VERSION ""

NS_ :

BS_:

BU_: Inverter1 Tester OBC_DDC VCU IPB Labcar_Transmit OBD_Tester TestTool_RB IMU_RB HU_B HU_C HU_A EPAS CKM12RX CKM12TX

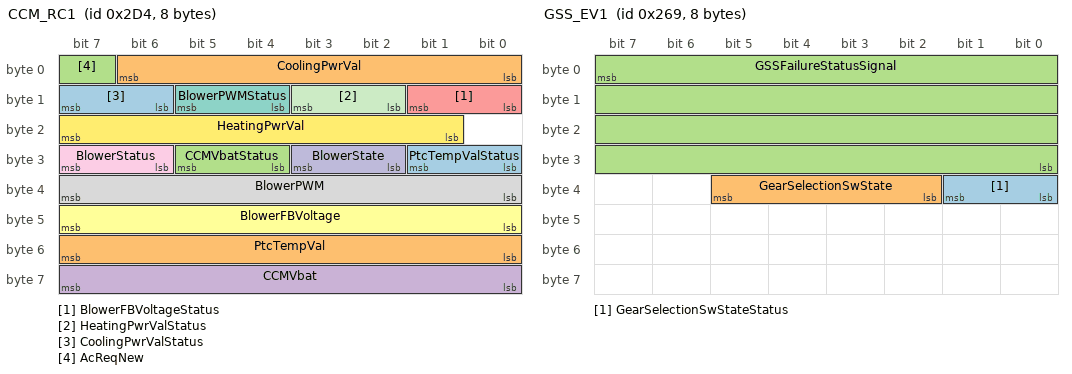
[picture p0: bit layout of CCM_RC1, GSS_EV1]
BO_ 724 CCM_RC1: 8 Vector__XXX
 SG_ PtcTempValStatus : 25|2@0+ (1,0) [0|3] ""  VCU
 SG_ PtcTempVal : 55|8@0+ (1,-40) [-40|215] "°C"  VCU
 SG_ CCMVbatStatus : 29|2@0+ (1,0) [0|3] ""  VCU
 SG_ CCMVbat : 63|8@0+ (0.1,0) [0|25.5] "Volts"  VCU
 SG_ BlowerFBVoltageStatus : 9|2@0+ (1,0) [0|3] ""  VCU
 SG_ BlowerFBVoltage : 47|8@0+ (0.1,0) [0|25.5] "Volts"  VCU
 SG_ BlowerPWMStatus : 13|2@0+ (1,0) [0|3] ""  VCU
 SG_ BlowerPWM : 39|8@0+ (1,0) [0|100] "%"  VCU
 SG_ BlowerStatus : 31|2@0+ (1,0) [0|3] ""  VCU
 SG_ BlowerState : 27|2@0+ (1,0) [0|3] ""  VCU
 SG_ HeatingPwrValStatus : 11|2@0+ (1,0) [0|3] ""  VCU
 SG_ HeatingPwrVal : 23|7@0+ (1,0) [0|100] "%"  VCU
 SG_ CoolingPwrValStatus : 15|2@0+ (1,0) [0|3] ""  VCU
 SG_ CoolingPwrVal : 6|7@0+ (1,0) [0|100] "%"  VCU
 SG_ AcReqNew : 7|1@0+ (1,0) [0|1] ""  VCU

BO_ 408 IPC14: 8 Vector__XXX
 SG_ ICDispSpeedSigStatus : 11|2@0+ (1,0) [0|3] ""  VCU
 SG_ ICDispSpeedSig : 7|12@0+ (0.03125,0) [0|127.96875] "m/s"  VCU

BO_ 495 TelematicsEventMsg_RC4: 8 Vector__XXX
 SG_ RemoteValetCmdStatus : 47|2@0+ (1,0) [0|3] ""  VCU
 SG_ RemoteValetCmd : 33|1@0+ (1,0) [0|1] ""  VCU

BO_ 617 GSS_EV1: 8 Vector__XXX
 SG_ GearSelectionSwStateStatus : 33|2@0+ (1,0) [0|3] ""  VCU
 SG_ GearSelectionSwState : 37|4@0+ (1,0) [0|15] ""  VCU
 SG_ GSSFailureStatusSignal : 7|32@0+ (1,0) [0|4294967295] ""  VCU

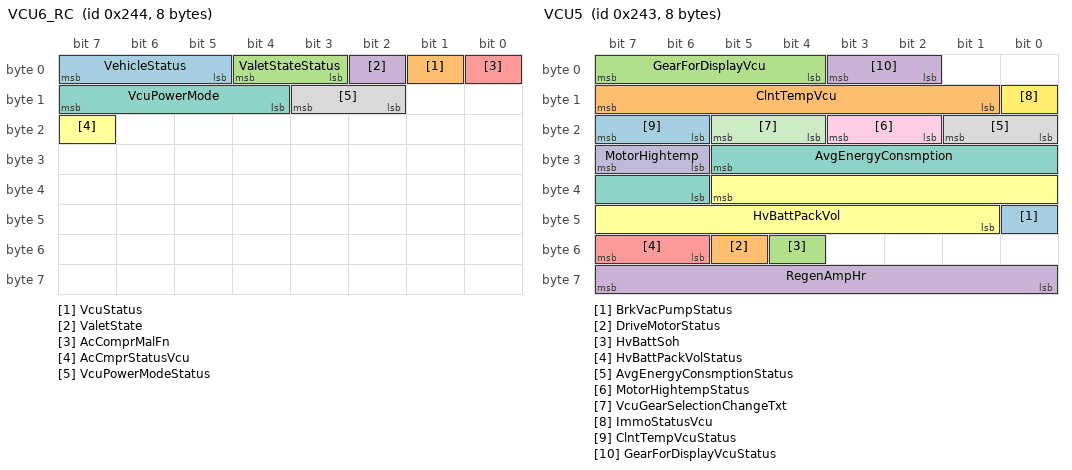
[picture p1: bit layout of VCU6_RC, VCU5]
BO_ 580 VCU6_RC: 8 VCU
 SG_ VehicleStatus : 7|3@0+ (1,0) [0|7] "" Vector__XXX
 SG_ VcuStatus : 1|1@0+ (1,0) [0|1] "" Vector__XXX
 SG_ ValetStateStatus : 4|2@0+ (1,0) [0|3] "" Vector__XXX
 SG_ ValetState : 2|1@0+ (1,0) [0|1] "" Vector__XXX
 SG_ AcComprMalFn : 0|1@0+ (1,0) [0|1] "" Vector__XXX
 SG_ AcCmprStatusVcu : 23|1@0+ (1,0) [0|1] "" Vector__XXX
 SG_ VcuPowerMode : 15|4@0+ (1,0) [0|15] "" Vector__XXX
 SG_ VcuPowerModeStatus : 11|2@0+ (1,0) [0|3] "" Vector__XXX

BO_ 579 VCU5: 8 VCU
 SG_ BrkVacPumpStatus : 40|1@0+ (1,0) [0|1] "" Vector__XXX
 SG_ DriveMotorStatus : 53|1@0+ (1,0) [0|1] "" Vector__XXX
 SG_ HvBattSoh : 52|1@0+ (1,0) [0|1] "" Vector__XXX
 SG_ RegenAmpHr : 63|8@0+ (0.5,0) [0|125] "" Vector__XXX
 SG_ HvBattPackVolStatus : 55|2@0+ (1,0) [0|3] "" Vector__XXX
 SG_ HvBattPackVol : 37|13@0+ (0.1,0) [0|500] "" Vector__XXX
 SG_ AvgEnergyConsmption : 29|8@0+ (1,0) [0|250] "kwH/Km" Vector__XXX
 SG_ AvgEnergyConsmptionStatus : 17|2@0+ (1,0) [0|3] "" Vector__XXX
 SG_ MotorHightempStatus : 19|2@0+ (1,0) [0|3] "" Vector__XXX
 SG_ MotorHightemp : 31|2@0+ (1,0) [0|3] "" Vector__XXX
 SG_ VcuGearSelectionChangeTxt : 21|2@0+ (1,0) [0|3] "" Vector__XXX
 SG_ ImmoStatusVcu : 8|1@0+ (1,0) [0|1] "" Vector__XXX
 SG_ ClntTempVcuStatus : 23|2@0+ (1,0) [0|3] "" Vector__XXX
 SG_ ClntTempVcu : 15|7@0+ (1,-10) [-10|80] "deg" Vector__XXX
 SG_ GearForDisplayVcu : 7|4@0+ (1,0) [0|15] "" Vector__XXX
 SG_ GearForDisplayVcuStatus : 3|2@0+ (1,0) [0|3] "" Vector__XXX

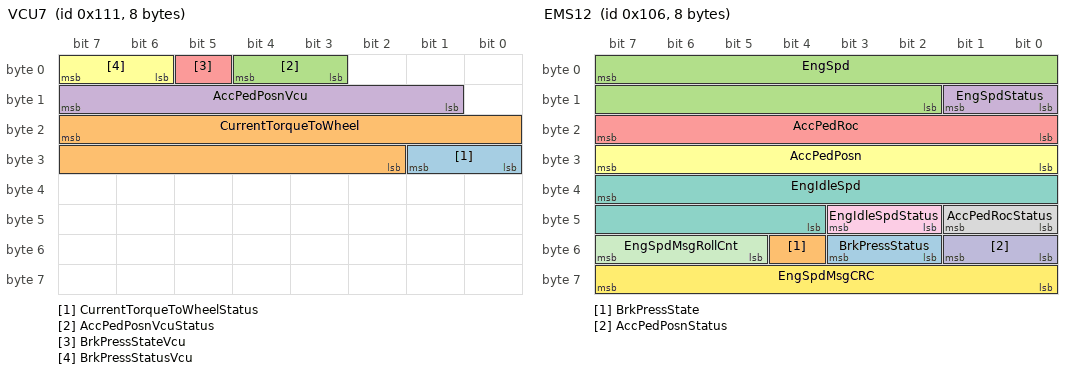
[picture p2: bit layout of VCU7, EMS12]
BO_ 273 VCU7: 8 VCU
 SG_ CurrentTorqueToWheelStatus : 25|2@0+ (1,0) [0|3] "" Vector__XXX
 SG_ CurrentTorqueToWheel : 23|14@0+ (0.25,-2048) [-2048|2047.75] "" Vector__XXX
 SG_ AccPedPosnVcuStatus : 4|2@0+ (1,0) [0|3] "" Vector__XXX
 SG_ AccPedPosnVcu : 15|7@0+ (1,0) [0|100] "%" Vector__XXX
 SG_ BrkPressStateVcu : 5|1@0+ (1,0) [0|1] "" Vector__XXX
 SG_ BrkPressStatusVcu : 7|2@0+ (1,0) [0|3] "" Vector__XXX

BO_ 257 VICM1: 8 Vector__XXX
 SG_ PEPSAuthMsg : 7|64@0+ (1,0) [0|0] ""  VCU

BO_ 259 SRS1: 8 Vector__XXX
 SG_ CrashoutputSignal : 7|8@0+ (1,0) [0|255] ""  VCU

BO_ 262 EMS12: 8 VCU
 SG_ BrkPressStatus : 51|2@0+ (1,0) [0|3] "" Vector__XXX
 SG_ BrkPressState : 52|1@0+ (1,0) [0|1] "" Vector__XXX
 SG_ EngSpd : 7|14@0+ (1,0) [0|16383] "rpm" Vector__XXX
 SG_ EngSpdStatus : 9|2@0+ (1,0) [0|3] "" Vector__XXX
 SG_ AccPedRoc : 23|8@0+ (16,-2000) [-2000|2000] "% / s" Vector__XXX
 SG_ AccPedPosn : 31|8@0+ (0.5,0) [0|100] "%" Vector__XXX
 SG_ EngIdleSpd : 39|12@0+ (1,0) [0|3000] "rpm" Vector__XXX
 SG_ AccPedRocStatus : 41|2@0+ (1,0) [0|3] "" Vector__XXX
 SG_ EngIdleSpdStatus : 43|2@0+ (1,0) [0|3] "" Vector__XXX
 SG_ AccPedPosnStatus : 49|2@0+ (1,0) [0|3] "" Vector__XXX
 SG_ EngSpdMsgRollCnt : 55|3@0+ (1,0) [0|7] "" Vector__XXX
 SG_ EngSpdMsgCRC : 63|8@0+ (1,0) [0|255] "" Vector__XXX

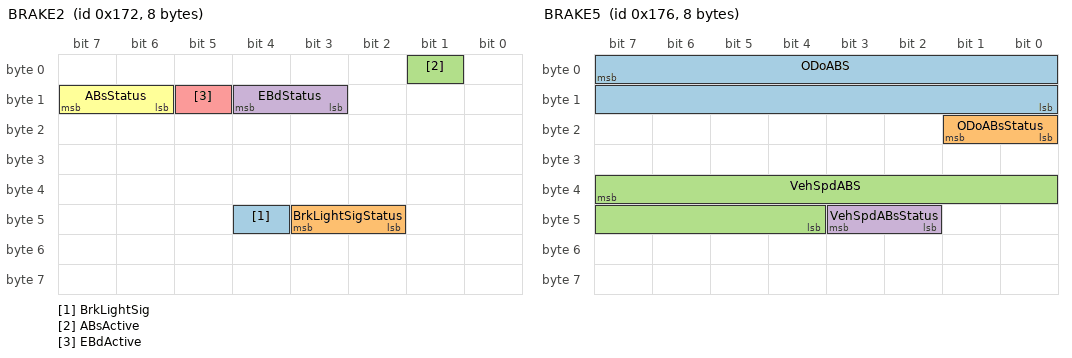
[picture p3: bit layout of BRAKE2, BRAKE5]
BO_ 370 BRAKE2: 8 IPB
 SG_ BrkLightSig : 44|1@0+ (1,0) [0|1] "" Vector__XXX
 SG_ BrkLightSigStatus : 43|2@0+ (1,0) [0|3] "" Vector__XXX
 SG_ ABsActive : 1|1@0+ (1,0) [0|1] ""  VCU
 SG_ EBdStatus : 12|2@0+ (1,0) [0|3] ""  VCU
 SG_ EBdActive : 13|1@0+ (1,0) [0|1] ""  VCU
 SG_ ABsStatus : 15|2@0+ (1,0) [0|3] ""  VCU

BO_ 374 BRAKE5: 8 IPB
 SG_ ODoABS : 7|16@0+ (1,0) [0|65534] "m"  VCU
 SG_ ODoABsStatus : 17|2@0+ (1,0) [0|3] ""  VCU
 SG_ VehSpdABS : 39|12@0+ (0.03125,0) [0|127.96875] "m/s"  VCU
 SG_ VehSpdABsStatus : 43|2@0+ (1,0) [0|3] ""  VCU

BO_ 646 EMS5: 8 VCU
 SG_ UserSpdLim : 7|8@0+ (1,0) [0|255] "km/h" Vector__XXX
 SG_ UserSpdLimLamp : 8|1@0+ (1,0) [0|1] "" Vector__XXX
 SG_ UserSpdLimFault : 10|2@0+ (1,0) [0|3] "" Vector__XXX
 SG_ UserSpdLimStatus : 12|2@0+ (1,0) [0|3] "" Vector__XXX
 SG_ EngStatus : 15|3@0+ (1,0) [0|7] "" Vector__XXX
 SG_ CeLampState : 18|2@0+ (1,0) [0|3] "" Vector__XXX
 SG_ StaterProhibitionDelay : 19|1@0+ (1,0) [0|1] "" Vector__XXX
 SG_ StarterControlState : 21|2@0+ (1,0) [0|3] "" Vector__XXX
 SG_ UserSpdLimState : 23|2@0+ (1,0) [0|3] "" Vector__XXX
 SG_ SFCActiveEMS : 25|2@0+ (1,0) [0|3] "" Vector__XXX
 SG_ DrvModeIndctnEMSstatus : 27|2@0+ (1,0) [0|3] "" Vector__XXX
 SG_ CruiseSpdLamp : 29|2@0+ (1,0) [0|3] "" Vector__XXX
 SG_ StartercControlStatus : 31|2@0+ (1,0) [0|3] "" Vector__XXX
 SG_ CurrGearEms : 35|4@0+ (1,0) [0|15] "" Vector__XXX
 SG_ CruiseSpdFault : 37|2@0+ (1,0) [0|3] "" Vector__XXX
 SG_ CruiseSpdStatus : 39|2@0+ (1,0) [0|3] "" Vector__XXX
 SG_ CruiseSpd : 47|8@0+ (1,0) [0|255] "Km/h" Vector__XXX
 SG_ CurrGearEmsStatus : 50|2@0+ (1,0) [0|3] "" Vector__XXX
 SG_ GearShiftIndctnEmsStatus : 52|2@0+ (1,0) [0|3] "" Vector__XXX
 SG_ GearShiftIndctnEms : 55|3@0+ (1,0) [0|7] "" Vector__XXX
 SG_ CruiseSwitchstate : 57|2@0+ (1,0) [0|3] "" Vector__XXX
 SG_ CruiseSwitchstateStatus : 59|2@0+ (1,0) [0|3] "" Vector__XXX
 SG_ DrvModeIndctnEMS : 63|4@0+ (1,0) [0|15] "" Vector__XXX

BO_ 697 IPC5: 8 Vector__XXX
 SG_ IcHuResetTripB : 57|1@0+ (1,0) [0|1] ""  VCU
 SG_ IcHuResetTripA : 58|1@0+ (1,0) [0|1] ""  VCU

BO_ 699 IPC11: 8 Vector__XXX
 SG_ IcHuTripAInfofull : 7|17@0+ (0.1,0) [0|9999.9] "Km"  VCU
 SG_ IcHuTripBInfofull : 22|17@0+ (0.1,0) [0|9999.9] "Km"  VCU

BO_ 946 BCM_IC_RC4: 8 Vector__XXX
 SG_ DoorStateRearLHStatus : 1|2@0+ (1,0) [0|3] ""  VCU
 SG_ DoorStatePassStatus : 3|2@0+ (1,0) [0|3] ""  VCU
 SG_ DoorStatePass : 4|1@0+ (1,0) [0|1] ""  VCU
 SG_ DoorStateDrvrStatus : 6|2@0+ (1,0) [0|3] ""  VCU
 SG_ DoorStateDrvr : 7|1@0+ (1,0) [0|1] ""  VCU
 SG_ DoorStateRearRH : 8|1@0+ (1,0) [0|1] ""  VCU
 SG_ DoorStateRearRHStatus : 10|2@0+ (1,0) [0|3] ""  VCU
 SG_ DoorStateRearLH : 11|1@0+ (1,0) [0|1] ""  VCU
 SG_ TailgateState : 15|1@0+ (1,0) [0|1] ""  VCU
 SG_ TailgateStateStatus : 19|2@0+ (1,0) [0|3] ""  VCU
 SG_ LowBeamMalFn : 32|1@0+ (1,0) [0|1] ""  VCU
 SG_ HighBeamTelltale : 33|1@0+ (1,0) [0|1] ""  VCU
 SG_ HighBeamTelltaleStatus : 35|2@0+ (1,0) [0|3] ""  VCU
 SG_ DRLTelltale : 36|1@0+ (1,0) [0|1] ""  VCU
 SG_ DRLTelltaleStatus : 43|2@0+ (1,0) [0|3] ""  VCU
 SG_ LowBeamMalFnStatus : 52|2@0+ (1,0) [0|3] ""  VCU
 SG_ BonnetState : 54|1@0+ (1,0) [0|1] ""  VCU
 SG_ BonnetStateStatus : 57|2@0+ (1,0) [0|3] ""  VCU

BO_ 948 IPC12: 8 Vector__XXX
 SG_ OdoICFullSigPeriodic : 7|32@0+ (1,0) [0|999999000] "m"  VCU
 SG_ OdoICFullSigPeriodicStatus : 33|2@0+ (1,0) [0|3] ""  VCU

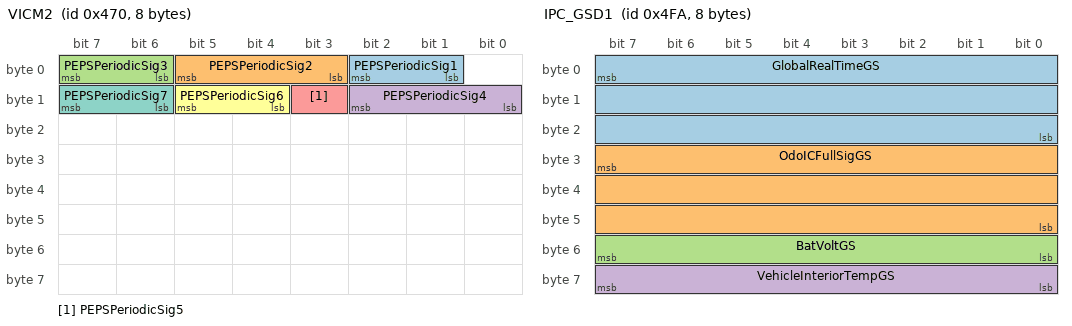
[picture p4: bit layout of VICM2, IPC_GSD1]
BO_ 1136 VICM2: 8 Vector__XXX
 SG_ PEPSPeriodicSig1 : 2|2@0+ (1,0) [0|3] ""  VCU
 SG_ PEPSPeriodicSig2 : 5|3@0+ (1,0) [0|7] ""  VCU
 SG_ PEPSPeriodicSig3 : 7|2@0+ (1,0) [0|3] ""  VCU
 SG_ PEPSPeriodicSig4 : 10|3@0+ (1,0) [0|7] ""  VCU
 SG_ PEPSPeriodicSig5 : 11|1@0+ (1,0) [0|1] ""  VCU
 SG_ PEPSPeriodicSig6 : 13|2@0+ (1,0) [0|3] ""  VCU
 SG_ PEPSPeriodicSig7 : 15|2@0+ (1,0) [0|3] ""  VCU

BO_ 1274 IPC_GSD1: 8 Vector__XXX
 SG_ GlobalRealTimeGS : 7|24@0+ (1,0) [0|16777214] "min"  VCU
 SG_ OdoICFullSigGS : 31|24@0+ (1,0) [0|16777214] "km"  VCU
 SG_ BatVoltGS : 55|8@0+ (0.1,0) [0|25.4] "V"  VCU
 SG_ VehicleInteriorTempGS : 63|8@0+ (1,-40) [-40|214] "Deg"  VCU

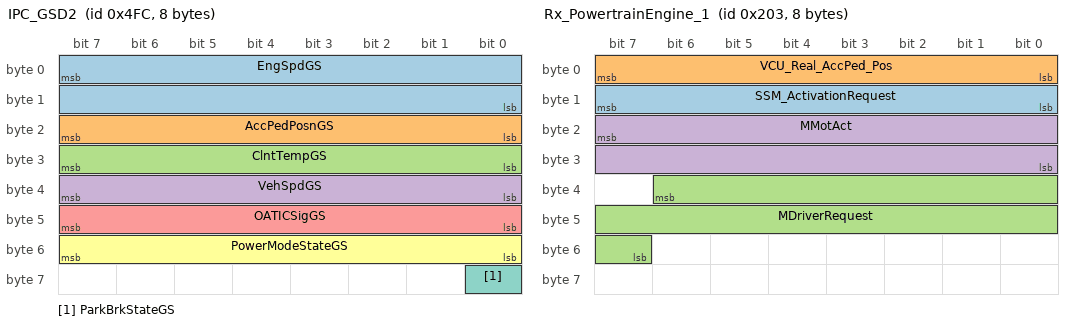
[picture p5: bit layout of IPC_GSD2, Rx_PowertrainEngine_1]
BO_ 1276 IPC_GSD2: 8 Vector__XXX
 SG_ EngSpdGS : 7|16@0+ (1,0) [0|65534] "rpm"  VCU
 SG_ AccPedPosnGS : 23|8@0+ (0.5,0) [0|127] "%"  VCU
 SG_ ClntTempGS : 31|8@0+ (1,-40) [-40|214] "Deg"  VCU
 SG_ VehSpdGS : 39|8@0+ (1,0) [0|254] "km/h"  VCU
 SG_ OATICSigGS : 47|8@0+ (1,-40) [-40|214] "Deg"  VCU
 SG_ PowerModeStateGS : 55|8@0+ (1,0) [0|255] ""  VCU
 SG_ ParkBrkStateGS : 56|1@0+ (1,0) [0|1] ""  VCU

BO_ 1278 IPC_GSD3: 8 Vector__XXX
 SG_ VehIdetNumGS : 7|40@0+ (1,0) [0|0] ""  VCU

BO_ 1280 BCM_NMPDU: 8 Vector__XXX
 SG_ BCM_NMPDU_SRC_ECU_ID : 7|8@0+ (1,0) [0|255] ""  VCU
 SG_ RepeatMessageReq_BCM : 8|1@0+ (1,0) [0|1] ""  VCU
 SG_ Reserved0 : 9|1@0+ (1,0) [0|1] ""  VCU
 SG_ Reserved1 : 10|1@0+ (1,0) [0|1] ""  VCU
 SG_ NMCoOrdSlpReady_BCM : 11|1@0+ (1,0) [0|1] ""  VCU
 SG_ ActiveWakeUp_BCM : 12|1@0+ (1,0) [0|1] ""  VCU
 SG_ Reserved2 : 13|1@0+ (1,0) [0|1] ""  VCU
 SG_ PartialNetworkInformation_BCM : 14|1@0+ (1,0) [0|1] ""  VCU
 SG_ Reserved3 : 15|1@0+ (1,0) [0|1] ""  VCU
 SG_ CurrentState_BCM : 16|1@0+ (1,0) [0|1] ""  VCU
 SG_ PreviousState_BCM : 19|3@0+ (1,0) [0|7] ""  VCU
 SG_ Reserved4 : 20|1@0+ (1,0) [0|1] ""  VCU
 SG_ Reserved5 : 21|1@0+ (1,0) [0|1] ""  VCU
 SG_ Reserved6 : 22|1@0+ (1,0) [0|1] ""  VCU
 SG_ Reserved7 : 23|1@0+ (1,0) [0|1] ""  VCU
 SG_ BCM_NMPDU_USER_DATA_D1 : 31|8@0+ (1,0) [0|255] ""  VCU
 SG_ BCM_NMPDU_USER_DATA_D2 : 39|8@0+ (1,0) [0|255] ""  VCU
 SG_ BCM_NMPDU_USER_DATA_D3 : 47|8@0+ (1,0) [0|255] ""  VCU
 SG_ BCM_NMPDU_USER_DATA_D4 : 55|8@0+ (1,0) [0|255] ""  VCU
 SG_ BCM_NMPDU_USER_DATA_D5 : 63|8@0+ (1,0) [0|255] ""  VCU

BO_ 515 Rx_PowertrainEngine_1: 8 Labcar_Transmit
 SG_ SSM_ActivationRequest : 15|8@0+ (1,0) [0|1] ""  VCU
 SG_ VCU_Real_AccPed_Pos : 7|8@0+ (1,0) [0|100] "%"  VCU
 SG_ MDriverRequest : 38|16@0+ (1,-30000) [-30000|30000] "Nm"  VCU,IPB
 SG_ MMotAct : 23|16@0+ (1,-30000) [-30000|30000] "Nm"  VCU,IPB

BO_ 516 Rx_PowertrainGearbox: 8 Labcar_Transmit
 SG_ ActGear_Updated : 29|1@0+ (1,0) [0|1] "-"  IPB
 SG_ ActGear : 19|6@0+ (1,-16) [-16|16] "-"  IPB

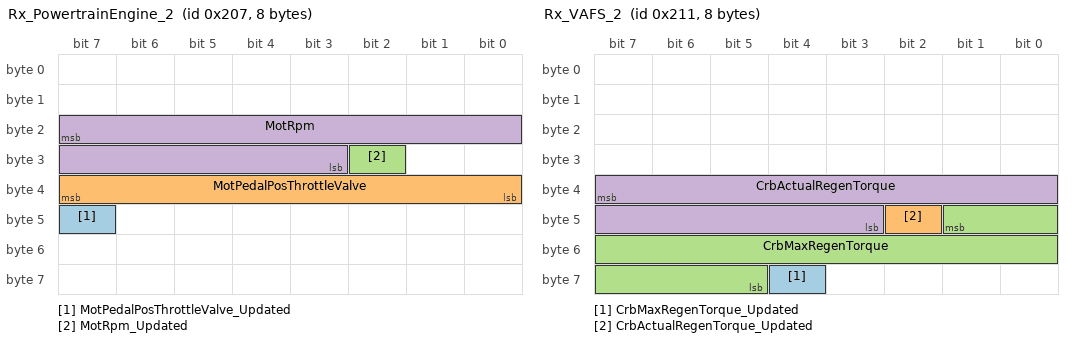
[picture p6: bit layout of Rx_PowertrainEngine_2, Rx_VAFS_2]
BO_ 519 Rx_PowertrainEngine_2: 8 Labcar_Transmit
 SG_ MotPedalPosThrottleValve_Updated : 47|1@0+ (1,0) [0|1] "-"  IPB
 SG_ MotPedalPosThrottleValve : 39|8@0+ (0.012207,0) [0|3.112785] "%"  IPB
 SG_ MotRpm_Updated : 26|1@0+ (1,0) [0|1] "-"  IPB
 SG_ MotRpm : 23|13@0+ (1,0) [0|8000] "rpm"  IPB

BO_ 529 Rx_VAFS_2: 8 Labcar_Transmit
 SG_ CrbMaxRegenTorque_Updated : 60|1@0+ (1,0) [0|1] ""  IPB
 SG_ CrbActualRegenTorque_Updated : 42|1@0+ (1,0) [0|1] ""  IPB
 SG_ CrbMaxRegenTorque : 41|13@0+ (1,0) [0|8191] "Nm"  IPB
 SG_ CrbActualRegenTorque : 39|13@0+ (1,0) [0|8191] "Nm"  IPB

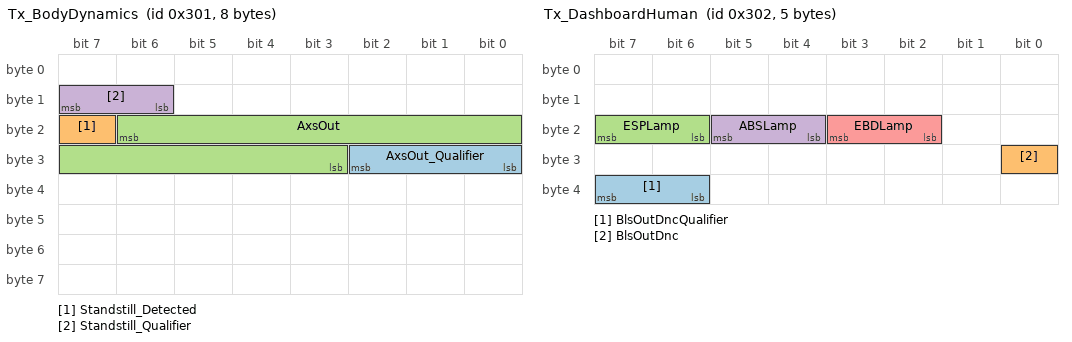
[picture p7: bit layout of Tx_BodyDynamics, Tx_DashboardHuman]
BO_ 769 Tx_BodyDynamics: 8 IPB
 SG_ AxsOut_Qualifier : 26|3@0+ (1,0) [0|7] "enum"  Labcar_Transmit
 SG_ Standstill_Detected : 23|1@0+ (1,0) [0|1] ""  Labcar_Transmit
 SG_ AxsOut : 22|12@0+ (0.027127,-21.5928) [-21.5928|21.5928] "m/s^2"  Labcar_Transmit
 SG_ Standstill_Qualifier : 15|2@0+ (1,0) [0|3] ""  Labcar_Transmit

BO_ 770 Tx_DashboardHuman: 5 IPB
 SG_ BlsOutDncQualifier : 39|2@0+ (1,0) [0|2] ""  Labcar_Transmit
 SG_ BlsOutDnc : 24|1@0+ (1,0) [0|1] ""  Labcar_Transmit
 SG_ ESPLamp : 23|2@0+ (1,0) [0|3] ""  Labcar_Transmit
 SG_ ABSLamp : 21|2@0+ (1,0) [0|3] ""  Labcar_Transmit
 SG_ EBDLamp : 19|2@0+ (1,0) [0|3] ""  Labcar_Transmit

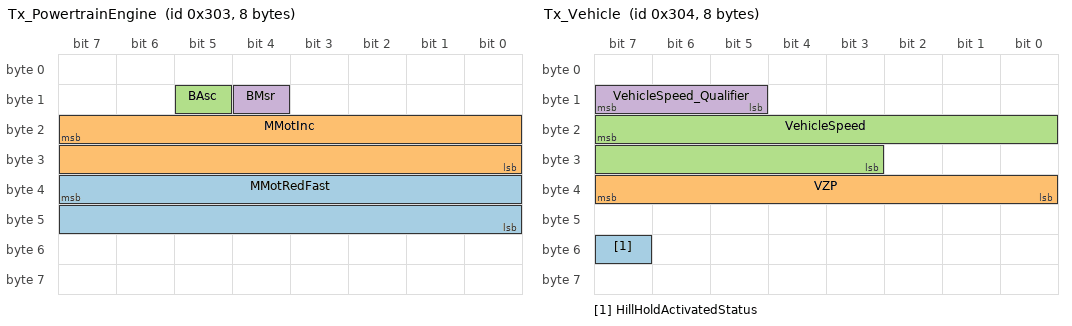
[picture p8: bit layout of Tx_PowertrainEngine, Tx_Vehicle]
BO_ 771 Tx_PowertrainEngine: 8 IPB
 SG_ MMotRedFast : 39|16@0+ (1,-30000) [-30000|30000] "Nm"  Labcar_Transmit
 SG_ MMotInc : 23|16@0+ (1,-30000) [-30000|30000] "Nm"  Labcar_Transmit
 SG_ BAsc : 13|1@0+ (1,0) [0|1] ""  Labcar_Transmit
 SG_ BMsr : 12|1@0+ (1,0) [0|1] ""  Labcar_Transmit

BO_ 772 Tx_Vehicle: 8 IPB
 SG_ HillHoldActivatedStatus : 55|1@0+ (1,0) [0|1] "" Vector__XXX
 SG_ VZP : 39|8@0+ (0.5,0) [0|50] "%" Vector__XXX
 SG_ VehicleSpeed : 23|13@0+ (0.05625,0) [0|460.74375] "Km/h"  Labcar_Transmit
 SG_ VehicleSpeed_Qualifier : 15|3@0+ (1,0) [0|7] ""  Labcar_Transmit

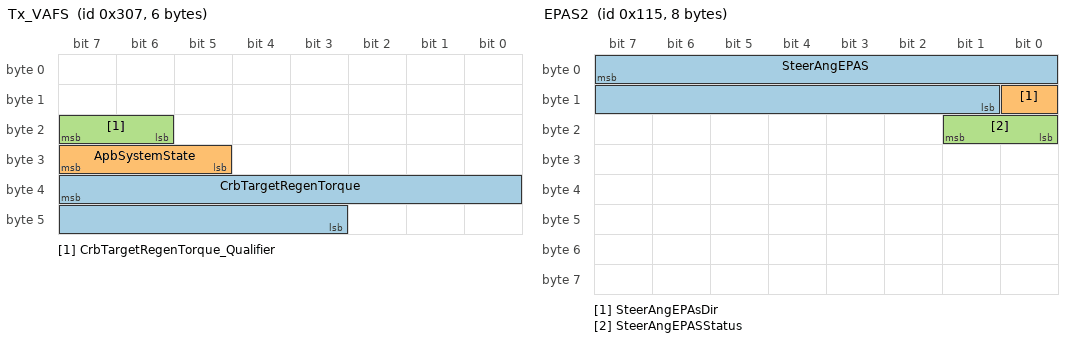
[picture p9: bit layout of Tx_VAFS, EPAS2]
BO_ 775 Tx_VAFS: 6 IPB
 SG_ CrbTargetRegenTorque : 39|13@0+ (1,0) [0|8191] "Nm"  Labcar_Transmit
 SG_ ApbSystemState : 31|3@0+ (1,0) [0|7] ""  Labcar_Transmit
 SG_ CrbTargetRegenTorque_Qualifier : 23|2@0+ (1,0) [0|3] ""  Labcar_Transmit

BO_ 1586 Dev3_IPB: 8 IPB
 SG_ IPB_PlungerPressure : 42|10@1+ (0.3,-5) [-5|301.9] "bar"  Labcar_Transmit

BO_ 277 EPAS2: 8 EPAS
 SG_ SteerAngEPAS : 7|15@0+ (0.04375,0) [0|1433.55625] " deg"  IPB,HU_B,HU_C,HU_A
 SG_ SteerAngEPAsDir : 8|1@0+ (1,0) [0|1] ""  IPB,HU_C,HU_A,HU_B
 SG_ SteerAngEPASStatus : 17|2@0+ (1,0) [0|3] ""  IPB,HU_B,HU_A,HU_C

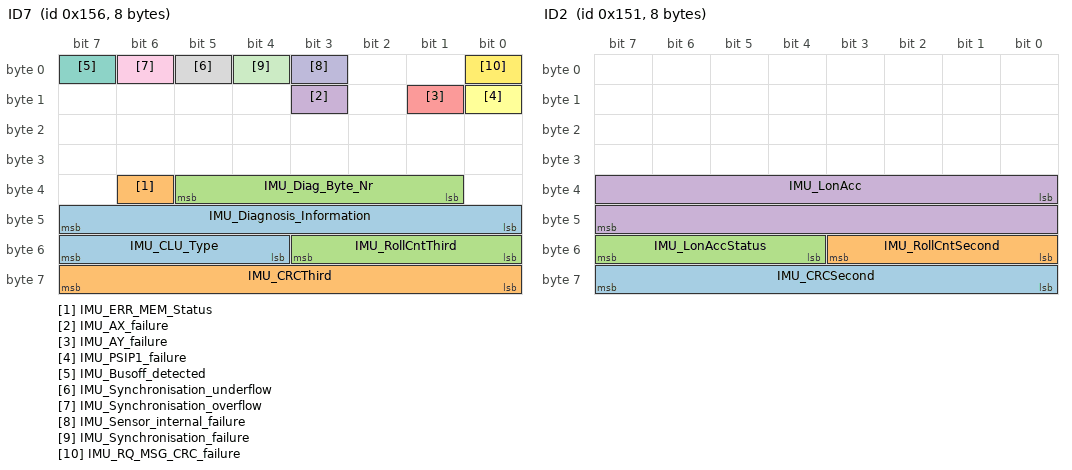
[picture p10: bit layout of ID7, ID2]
BO_ 342 ID7: 8 IMU_RB
 SG_ IMU_Diagnosis_Information : 40|8@1+ (1,0) [0|255] ""  TestTool_RB
 SG_ IMU_ERR_MEM_Status : 38|1@1+ (1,0) [0|1] ""  TestTool_RB
 SG_ IMU_Diag_Byte_Nr : 33|5@1+ (1,0) [0|31] ""  TestTool_RB
 SG_ IMU_AX_failure : 11|1@1+ (1,0) [0|1] ""  TestTool_RB
 SG_ IMU_AY_failure : 9|1@1+ (1,0) [0|1] ""  TestTool_RB
 SG_ IMU_PSIP1_failure : 8|1@1+ (1,0) [0|1] ""  TestTool_RB
 SG_ IMU_Busoff_detected : 7|1@1+ (1,0) [0|1] ""  TestTool_RB
 SG_ IMU_Synchronisation_underflow : 5|1@1+ (1,0) [0|1] ""  TestTool_RB
 SG_ IMU_Synchronisation_overflow : 6|1@1+ (1,0) [0|1] ""  TestTool_RB
 SG_ IMU_Sensor_internal_failure : 3|1@1+ (1,0) [0|1] ""  TestTool_RB
 SG_ IMU_Synchronisation_failure : 4|1@1+ (1,0) [0|1] ""  TestTool_RB
 SG_ IMU_RQ_MSG_CRC_failure : 0|1@1+ (1,0) [0|1] "" Vector__XXX
 SG_ IMU_CLU_Type : 52|4@1+ (1,0) [0|15] ""  TestTool_RB
 SG_ IMU_CRCThird : 56|8@1+ (1,0) [0|255] ""  TestTool_RB
 SG_ IMU_RollCntThird : 48|4@1+ (1,0) [0|15] ""  TestTool_RB

BO_ 337 ID2: 8 IMU_RB
 SG_ IMU_CRCSecond : 56|8@1+ (1,0) [0|255] ""  IPB,TestTool_RB
 SG_ IMU_RollCntSecond : 48|4@1+ (1,0) [0|15] ""  IPB,TestTool_RB
 SG_ IMU_LonAccStatus : 52|4@1+ (1,0) [0|15] ""  IPB,TestTool_RB
 SG_ IMU_LonAcc : 32|16@1+ (0.00125,-40.96) [-40.96|40.95875] "m/s²"  IPB,TestTool_RB

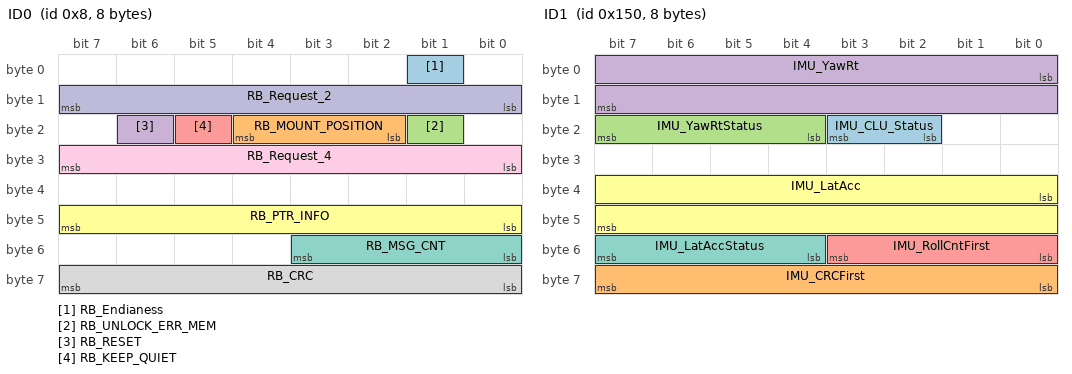
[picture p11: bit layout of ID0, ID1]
BO_ 8 ID0: 8 TestTool_RB
 SG_ RB_Endianess : 1|1@1+ (1,0) [0|1] "" Vector__XXX
 SG_ RB_MOUNT_POSITION : 18|3@1+ (1,0) [0|0] "" Vector__XXX
 SG_ RB_UNLOCK_ERR_MEM : 17|1@1+ (1,0) [0|0] ""  IMU_RB
 SG_ RB_RESET : 22|1@1+ (1,0) [0|0] ""  IMU_RB
 SG_ RB_KEEP_QUIET : 21|1@1+ (1,0) [0|0] ""  IMU_RB
 SG_ RB_PTR_INFO : 40|8@1+ (1,0) [0|0] ""  IMU_RB
 SG_ RB_MSG_CNT : 48|4@1+ (1,0) [0|15] ""  IMU_RB
 SG_ RB_CRC : 56|8@1+ (1,0) [0|0] "" Vector__XXX
 SG_ RB_Request_4 : 24|8@1+ (1,0) [0|0] ""  IMU_RB
 SG_ RB_Request_2 : 8|8@1+ (1,0) [0|0] ""  IMU_RB

BO_ 336 ID1: 8 IMU_RB
 SG_ IMU_CLU_Status : 18|2@1+ (1,0) [0|3] ""  IPB,TestTool_RB
 SG_ IMU_CRCFirst : 56|8@1+ (1,0) [0|255] ""  IPB,TestTool_RB
 SG_ IMU_YawRtStatus : 20|4@1+ (1,0) [0|15] ""  IPB,TestTool_RB
 SG_ IMU_YawRt : 0|16@1+ (0.005,-163.84) [-163.84|163.835] "°/sec"  IPB,TestTool_RB
 SG_ IMU_RollCntFirst : 48|4@1+ (1,0) [0|15] ""  IPB,TestTool_RB
 SG_ IMU_LatAcc : 32|16@1+ (0.00125,-40.96) [-40.96|40.95875] "m/s²"  IPB,TestTool_RB
 SG_ IMU_LatAccStatus : 52|4@1+ (1,0) [0|15] ""  IPB,TestTool_RB

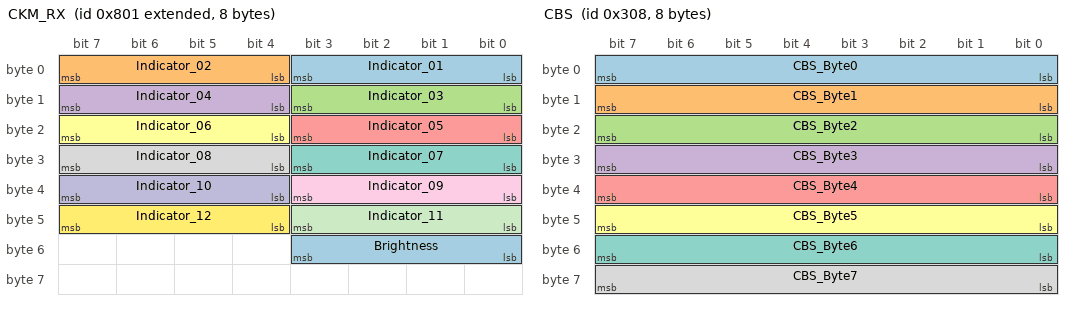
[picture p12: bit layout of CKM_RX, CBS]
BO_ 2147485697 CKM_RX: 8 Vector__XXX
 SG_ Indicator_01 : 0|4@1+ (1,0) [0|0] ""  CKM12RX
 SG_ Indicator_02 : 4|4@1+ (1,0) [0|0] ""  CKM12RX
 SG_ Indicator_03 : 8|4@1+ (1,0) [0|0] ""  CKM12RX
 SG_ Indicator_04 : 12|4@1+ (1,0) [0|0] ""  CKM12RX
 SG_ Indicator_05 : 16|4@1+ (1,0) [0|0] ""  CKM12RX
 SG_ Indicator_06 : 20|4@1+ (1,0) [0|0] ""  CKM12RX
 SG_ Indicator_07 : 24|4@1+ (1,0) [0|0] ""  CKM12RX
 SG_ Indicator_08 : 28|4@1+ (1,0) [0|0] ""  CKM12RX
 SG_ Indicator_09 : 32|4@1+ (1,0) [0|0] ""  CKM12RX
 SG_ Indicator_10 : 36|4@1+ (1,0) [0|0] ""  CKM12RX
 SG_ Indicator_11 : 40|4@1+ (1,0) [0|0] ""  CKM12RX
 SG_ Indicator_12 : 44|4@1+ (1,0) [0|0] ""  CKM12RX
 SG_ Brightness : 48|4@1+ (1,0) [0|0] ""  CKM12RX

BO_ 776 CBS: 8 IPB
 SG_ CBS_Byte0 : 0|8@1+ (1,0) [0|255] ""  Labcar_Transmit
 SG_ CBS_Byte1 : 8|8@1+ (1,0) [0|255] ""  Labcar_Transmit
 SG_ CBS_Byte2 : 16|8@1+ (1,0) [0|255] ""  Labcar_Transmit
 SG_ CBS_Byte3 : 24|8@1+ (1,0) [0|255] ""  Labcar_Transmit
 SG_ CBS_Byte4 : 32|8@1+ (1,0) [0|255] ""  Labcar_Transmit
 SG_ CBS_Byte5 : 40|8@1+ (1,0) [0|255] ""  Labcar_Transmit
 SG_ CBS_Byte6 : 48|8@1+ (1,0) [0|255] ""  Labcar_Transmit
 SG_ CBS_Byte7 : 56|8@1+ (1,0) [0|255] ""  Labcar_Transmit

BO_ 2147485696 CKM_TX: 8 CKM12TX
 SG_ Button_01 : 0|1@1+ (1,0) [0|1] "" Vector__XXX
 SG_ Button_02 : 1|1@1+ (1,0) [0|1] "" Vector__XXX
 SG_ Button_03 : 2|1@1+ (1,0) [0|1] "" Vector__XXX
 SG_ Button_04 : 3|1@1+ (1,0) [0|1] "" Vector__XXX
 SG_ Button_05 : 4|1@1+ (1,0) [0|1] "" Vector__XXX
 SG_ Button_06 : 5|1@1+ (1,0) [0|1] "" Vector__XXX
 SG_ Button_07 : 6|1@1+ (1,0) [0|1] "" Vector__XXX
 SG_ Button_08 : 7|1@1+ (1,0) [0|1] "" Vector__XXX
 SG_ Button_11 : 10|1@1+ (1,0) [0|1] "" Vector__XXX
 SG_ Button_12 : 11|1@1+ (1,0) [0|1] "" Vector__XXX
 SG_ Button_09 : 8|1@1+ (1,0) [0|1] "" Vector__XXX
 SG_ Button_10 : 9|1@1+ (1,0) [0|1] "" Vector__XXX
 SG_ DigIN_1 : 16|1@1+ (1,0) [0|1] "" Vector__XXX
 SG_ DigIN_2 : 17|1@1+ (1,0) [0|1] "" Vector__XXX
 SG_ DigIN_3 : 18|1@1+ (1,0) [0|1] "" Vector__XXX
 SG_ DigIN_4 : 19|1@1+ (1,0) [0|1] "" Vector__XXX
 SG_ DigIN_5 : 20|1@1+ (1,0) [0|1] "" Vector__XXX
 SG_ DigIN_6 : 21|1@1+ (1,0) [0|1] "" Vector__XXX
 SG_ DigIN_7 : 24|1@1+ (1,0) [0|1] "" Vector__XXX
 SG_ DigIN_8 : 25|1@1+ (1,0) [0|1] "" Vector__XXX
 SG_ DigIN_9 : 26|1@1+ (1,0) [0|1] "" Vector__XXX

BO_TX_BU_ 772 : VCU,IPB;
CM_ SG_ 724 PtcTempValStatus "PTC temperature signal status information";
CM_ SG_ 724 PtcTempVal "This signal is used to provide the current value of PTC temperature sensor";
CM_ SG_ 724 CCMVbatStatus "FATC battery Voltage Status";
CM_ SG_ 724 CCMVbat "Battery voltage measured by FATC";
CM_ SG_ 724 BlowerFBVoltageStatus "Blower feedback Voltage Status";
CM_ SG_ 724 BlowerFBVoltage "Blower Feedback voltage measured by FATC";
CM_ SG_ 724 BlowerPWMStatus "Blower PWM status";
CM_ SG_ 724 BlowerPWM "PWM% Given out by FATC for blower";
CM_ SG_ 724 BlowerStatus "Fault Occured:
It means one of the following faults has occured:
Blower Drive Line Short to Ground.
Blower Drive Line Short to Battery.
Blower Drive Line Open
Blower feedback Line Short to Battery.
Blower feedback Line Short to Ground or Open.";
CM_ SG_ 724 BlowerState "General Blower state
Not initialised:
it means blower is not yet initialised and all signal values of CCMblower message are not valid.
Off : it indicates that blower is Off.
On : it indicates that blower is On.";
CM_ SG_ 724 HeatingPwrValStatus "Indicate the status of heating power required for cabin heating ";
CM_ SG_ 724 HeatingPwrVal "This signal is used to control the PTC Heater for cabin heating";
CM_ SG_ 724 CoolingPwrValStatus "Indicate the status of cooling power required for cabin Cooling ";
CM_ SG_ 724 CoolingPwrVal "This signal is used to control the Compressor rpm for cabin Cooling";
CM_ SG_ 724 AcReqNew "VCU to recive the signal from FATC to know the AC request by driver";
CM_ SG_ 408 ICDispSpeedSigStatus "Signal represents Status of Display Vehicle Speed Signal";
CM_ SG_ 408 ICDispSpeedSig "Signal represents Display Vehicle Speed evaluated by Instrument Cluster
";
CM_ SG_ 495 RemoteValetCmdStatus "Status of the Valetcmd Status published by TCU";
CM_ SG_ 495 RemoteValetCmd "Command published by TCU to request FATC";
CM_ BO_ 617 "Gear Selection  Switch";
CM_ SG_ 617 GearSelectionSwStateStatus "Information is used to consider the Gear Selection to VCU";
CM_ SG_ 617 GearSelectionSwState "Information is used to consider the Gear Selection to VCU";
CM_ SG_ 617 GSSFailureStatusSignal "Indicates the Failure Modes in GSS";
CM_ SG_ 580 VehicleStatus "Vehicle status display messages";
CM_ SG_ 580 VcuStatus "This function displays status of the VCU Malfunctioning
";
CM_ SG_ 580 ValetStateStatus "ValetStateStatus signlal published by VCU";
CM_ SG_ 580 ValetState "ValetState as Published by VCU";
CM_ SG_ 580 AcComprMalFn "This function displays status of the AC Compressor Malfunctioning";
CM_ SG_ 580 AcCmprStatusVcu "This signal is used to cycle the compressor and diagnostic";
CM_ SG_ 580 VcuPowerMode "Indicates the VCU power mode";
CM_ SG_ 580 VcuPowerModeStatus "This information is used to determine the plausibility status for VCU power mode message";
CM_ SG_ 579 BrkVacPumpStatus "This function displays status of the Brake Vaccum Pump Malfunctioning";
CM_ SG_ 579 DriveMotorStatus "This function displays status of the Drive Motor Malfunctioning";
CM_ SG_ 579 HvBattSoh "HV Battery State of Health";
CM_ SG_ 579 RegenAmpHr "Regeneration Battery Charge";
CM_ SG_ 579 HvBattPackVolStatus "HV Battery Pack Voltage Status";
CM_ SG_ 579 HvBattPackVol "HV Battery Pack Voltage";
CM_ SG_ 579 AvgEnergyConsmption "Average Energy Consumption";
CM_ SG_ 579 AvgEnergyConsmptionStatus "Average Energy Consumption Status";
CM_ SG_ 579 MotorHightempStatus "This information is used to determine the Motor High Temp Status";
CM_ SG_ 579 MotorHightemp "This feature provides the traction motor High Temperature Status to the user.";
CM_ SG_ 579 VcuGearSelectionChangeTxt "Indicate the VCU Gear Selection Message";
CM_ SG_ 579 ImmoStatusVcu "This gives status of VCU whether mobilized or immobilized.";
CM_ SG_ 579 ClntTempVcuStatus "This information is used to determine the  Battery coolant temperature signal status. 
";
CM_ SG_ 579 ClntTempVcu "This information is used   to display or indicate the coolant temperature 
";
CM_ SG_ 579 GearForDisplayVcu "Gear For Display";
CM_ SG_ 579 GearForDisplayVcuStatus "Gear For Display Status";
CM_ SG_ 273 CurrentTorqueToWheelStatus "Status signal of Current Torque To Wheel signal";
CM_ SG_ 273 CurrentTorqueToWheel "Current Torque To Wheel values";
CM_ SG_ 273 AccPedPosnVcuStatus "This information is used to determine the accelerator pedal position signal status";
CM_ SG_ 273 AccPedPosnVcu "This information is used to determine the accelerator pedal position";
CM_ SG_ 273 BrkPressStateVcu "This inofmation tells whether brake is pressed  or not ";
CM_ SG_ 273 BrkPressStatusVcu "This information is used to determine the  Brake press status signal status. ";
CM_ SG_ 259 CrashoutputSignal "CrashOutput signal in the event of no Crash";
CM_ SG_ 262 BrkPressStatus "status information of Brake pedal";
CM_ SG_ 262 BrkPressState "This inofmation tells whether brake is pressed  or not ";
CM_ SG_ 262 EngSpd "Crank shaft speed of engine";
CM_ SG_ 262 EngSpdStatus "Crank shaft speed of engine, status
";
CM_ SG_ 262 AccPedRoc "accelerator pedal position rate of change
gradient of APM signal";
CM_ SG_ 262 AccPedPosn "accelerator pedal position.";
CM_ SG_ 262 EngIdleSpd "engine idle speed is Engine RPM signal at 0% acclerator pedal condition";
CM_ SG_ 262 AccPedRocStatus "Accelerator pedal rate of change, status
";
CM_ SG_ 262 EngIdleSpdStatus "Crank shaft speed of engine status
";
CM_ SG_ 262 AccPedPosnStatus "Accelerator pedal position, status info
";
CM_ SG_ 262 EngSpdMsgRollCnt "rolling counter for message 0x106";
CM_ SG_ 262 EngSpdMsgCRC "CRC for the message 0x106";
CM_ SG_ 370 BrkLightSig "Brake Light status signal is given by ABS / Esp to BCM for redundaent purpose";
CM_ SG_ 370 BrkLightSigStatus "status information of BrkLightSig";
CM_ SG_ 370 ABsActive "Indication that ABS / ESP system currently performs ABS intervention";
CM_ SG_ 370 EBdStatus "status information of EBD
";
CM_ SG_ 370 EBdActive "Indication that ABS / ESP system currently performs EBD intervention
";
CM_ SG_ 370 ABsStatus "status information of ABs";
CM_ SG_ 374 ODoABS "Mileage counter for odometer evaluated by ABS and ESP ECU and will be given to IC
";
CM_ SG_ 374 ODoABsStatus "status information of ODoABs";
CM_ SG_ 374 VehSpdABS "vehicle speed signal calculated by ABS and ESP ECU and will be given to IC

";
CM_ SG_ 374 VehSpdABsStatus "status information of VehSpdABs";
CM_ SG_ 646 UserSpdLim "User set limit value";
CM_ SG_ 646 UserSpdLimLamp "UserSpdLim Lamp state";
CM_ SG_ 646 UserSpdLimFault "User set limiter Fault";
CM_ SG_ 646 UserSpdLimStatus "User set limiter function state";
CM_ SG_ 646 EngStatus "Current Engine State";
CM_ SG_ 646 CeLampState "This information is used   to display or indicate the vehicle related malfunction state ";
CM_ SG_ 646 StaterProhibitionDelay "This information is used  to indicate whether starter inhibited due to prohibition delay";
CM_ SG_ 646 StarterControlState "This information is used to indicate the state of the starter control function";
CM_ SG_ 646 UserSpdLimState "User set limiter function state";
CM_ SG_ 646 SFCActiveEMS "It indicate Safety fuel cut startergy is active due to crash input from SRS ECU enabled/disabled";
CM_ SG_ 646 DrvModeIndctnEMSstatus "Driver mode statys information";
CM_ SG_ 646 CruiseSpdLamp "This information is used   to display or indicate that speed limiter is active or not";
CM_ SG_ 646 StartercControlStatus "Status information";
CM_ SG_ 646 CurrGearEms "This is information is used to display Current Gear information in cluster
";
CM_ SG_ 646 CruiseSpdFault "It indicate the fault in cruise system";
CM_ SG_ 646 CruiseSpdStatus "It indicate the cruise info status";
CM_ SG_ 646 CruiseSpd "This information is used   to indicate the speed limit values in display";
CM_ SG_ 646 CurrGearEmsStatus "status information of CurrGearRatio
";
CM_ SG_ 646 GearShiftIndctnEmsStatus "Gear shift Indication staus used to indicate the gear status signal";
CM_ SG_ 646 GearShiftIndctnEms "Gear shift Indication used to indicate the required gear status in IC  required Gear by the driver is to Improve the drive habits of driver ";
CM_ SG_ 646 CruiseSwitchstate "Resume and Set Cruise Switches stateinformation to support HDC function";
CM_ SG_ 646 CruiseSwitchstateStatus "CruiseSwitchstate Signal status information";
CM_ SG_ 646 DrvModeIndctnEMS "information is used   to display whether the vehicle is in Sports mode/economy mode";
CM_ SG_ 697 IcHuResetTripB "This signal indicates the Set/Reset of Trip B.";
CM_ SG_ 697 IcHuResetTripA "This signal indicates the Set/Reset of Trip A.";
CM_ SG_ 699 IcHuTripAInfofull "This signal indicates Trip A info";
CM_ SG_ 699 IcHuTripBInfofull "This signal indicates Trip B info";
CM_ SG_ 946 DoorStateRearLHStatus "Rear left side door valid Status





";
CM_ SG_ 946 DoorStatePassStatus "Driver Door Passenger valid Status";
CM_ SG_ 946 DoorStatePass "Co-Driver door switch state from BCM ";
CM_ SG_ 946 DoorStateDrvrStatus "DoorStateDrvr valid Status";
CM_ SG_ 946 DoorStateDrvr "Driver door switch state from BCM ";
CM_ SG_ 946 DoorStateRearRH "Rear right side door switch state from BCM to FATC and IC";
CM_ SG_ 946 DoorStateRearRHStatus "Rear right side door valid status



";
CM_ SG_ 946 DoorStateRearLH "Rear left side door switch state from BCM";
CM_ SG_ 946 TailgateState "Tailgate switch state (open or close) from BCM to various ECUs";
CM_ SG_ 946 TailgateStateStatus "Tailgate switch state vaild status";
CM_ SG_ 946 LowBeamMalFn "IC to display the message when failure in low beam lamp";
CM_ SG_ 946 HighBeamTelltale "IC to display the high beam tell-tale when the high beam lamp is active";
CM_ SG_ 946 HighBeamTelltaleStatus "Status of the High Beam Telltale";
CM_ SG_ 946 DRLTelltale "IC to display the Daytime Running Light (DRL) telltale";
CM_ SG_ 946 DRLTelltaleStatus "Status of the Daytime Running Light (DRL) telltale";
CM_ SG_ 946 LowBeamMalFnStatus "Status of the Low Beam Malfunction";
CM_ SG_ 946 BonnetState "Bonnet switch state (open or close) from BCM";
CM_ SG_ 946 BonnetStateStatus "BonnetState vaild status";
CM_ SG_ 948 OdoICFullSigPeriodic "Signal represents Odometer information in full range.";
CM_ SG_ 948 OdoICFullSigPeriodicStatus "Status of Signal representing Odometer information in full range.";
CM_ SG_ 1274 GlobalRealTimeGS "Global Real Time
";
CM_ SG_ 1274 OdoICFullSigGS "Total Distance Travelled";
CM_ SG_ 1274 BatVoltGS "Supply Voltage of Instrument Cluster";
CM_ SG_ 1274 VehicleInteriorTempGS "Vehicle Interior Temperature
";
CM_ SG_ 1276 EngSpdGS "Engine RPM signal will be transmitted by EMS
";
CM_ SG_ 1276 AccPedPosnGS "Throttle Position";
CM_ SG_ 1276 ClntTempGS "Engine Coolant Temperature";
CM_ SG_ 1276 VehSpdGS "Vehicle Speed";
CM_ SG_ 1276 OATICSigGS "Ambient Air Temperature";
CM_ SG_ 1276 PowerModeStateGS "Vehicle power mode signal shall be used by all ECUs of the vehicle for their respective functional implementation";
CM_ SG_ 1276 ParkBrkStateGS "Signal represents Status of ParkBrake";
CM_ SG_ 1278 VehIdetNumGS "Vehicle Identification Number - Last 5 digits of VIN";
CM_ SG_ 515 SSM_ActivationRequest "Hold request at standstill during eB2Z";
CM_ SG_ 515 VCU_Real_AccPed_Pos "Real Acc Ped position for OPD";
CM_ SG_ 516 ActGear " -3 = Park Gear
 -1 = Reverse Gear
  0 = Not Supported / Neutral Gear
  1 = First Gear
  2 = Second Gear
  3 = Third Gear
  4 = Fourth Gear
  5 = Fifth Gear
  6 = Sixth Gear
  7 = Seventh Gear
  8 = Eight Gear
  9 = CVT Forward Gear";
CM_ SG_ 529 CrbMaxRegenTorque_Updated "CRB - Updated flag for Maximal possible/available generator  torque (MbRegenMaxWheel)";
CM_ SG_ 529 CrbActualRegenTorque_Updated "CRB - Updated Flag for Actual possible generator torque (MbRegenWheel)";
CM_ SG_ 529 CrbMaxRegenTorque "CRB - Maximal possible/available generator torque (MbRegenMaxWheel)";
CM_ SG_ 529 CrbActualRegenTorque "CRB - Actual possible generator torque (MbRegenWheel)";
CM_ SG_ 772 HillHoldActivatedStatus "Acknowledgement of Hydraulic hold during eB2Z";
CM_ SG_ 772 VZP "Current VZP for OPD";
CM_ SG_ 775 CrbTargetRegenTorque "CRB - Target generator torque (MbRegenTargetWheel)";
CM_ BO_ 1586 "Development Message for IPB ECU";
CM_ SG_ 1586 IPB_PlungerPressure "plunger pressure, offset corrected and filtered signal";
CM_ SG_ 277 SteerAngEPAS "Steering Angle information can be used only for comfort function";
CM_ SG_ 277 SteerAngEPAsDir "Steering wheel angle direction";
CM_ SG_ 277 SteerAngEPASStatus "Steering Angle information can be used only for comfort function,Status info";
CM_ SG_ 337 IMU_LonAcc "Inertial Measurement Unit Longitudinal Accleration Primary";
CM_ SG_ 336 IMU_LatAcc "Inertial Measurement Unit Lateral Acceleration Primary";
BA_DEF_ SG_  "SignalType" STRING ;
BA_DEF_ SG_  "Remarks" STRING ;
BA_DEF_ SG_  "NWM_WakeupAllowed" ENUM  "No","Yes";
BA_DEF_ SG_  "GenSigTimeoutTime_HU_Mid_X451" INT 0 65535;
BA_DEF_ SG_  "GenSigTimeoutTime_HU_High_X451" INT 0 65535;
BA_DEF_ SG_  "GenSigTimeoutTime_HU_B" INT 0 65535;
BA_DEF_ SG_  "GenSigTimeoutTime_HU_A" INT 0 65535;
BA_DEF_ SG_  "GenSigTimeoutTime_BCM_Mid" INT 0 65535;
BA_DEF_ SG_  "GenSigTimeoutMsg_HU_Mid_X451" INT 0 65535;
BA_DEF_ SG_  "GenSigTimeoutMsg_HU_High_X451" INT 0 65535;
BA_DEF_ SG_  "GenSigTimeoutMsg_HU_B" INT 0 65535;
BA_DEF_ SG_  "GenSigTimeoutMsg_HU_A" INT 0 65535;
BA_DEF_ SG_  "GenSigStartValue" INT -2147483648 2147483647;
BA_DEF_ SG_  "GenSigSendType" ENUM  "Cyclic","OnWrite","OnWriteWithRepetition","OnChange","OnChangeWithRepetition","IfActive","IfActiveWithRepetition","NoSigSendType","NotUsed","NotUsed","NotUsed","NotUsed","NotUsed";
BA_DEF_ SG_  "GenSigInactiveValue" INT 0 0;
BA_DEF_ SG_  "GenSigEnvVarType" ENUM  "int","float","undef";
BA_DEF_ SG_  "GenSigCycleTimeActive" INT 0 0;
BA_DEF_ SG_  "GenSigCycleTime" INT 0 0;
BA_DEF_ SG_  "GenSigTimeoutMsg_HU_High_X445" INT 0 65535;
BA_DEF_ SG_  "GenSigTimeoutMsg_HU_Mid_X445" INT 0 65535;
BA_DEF_ SG_  "GenSigTimeoutTime_HU_High_X445" INT 0 65535;
BA_DEF_ SG_  "GenSigTimeoutTime_HU_Mid_X445" INT 0 65535;
BA_DEF_ BO_  "NmMessage" ENUM  "no","yes";
BA_DEF_ BO_  "NmAsrMessage" ENUM  "<n.a.>","No","Yes";
BA_DEF_ BO_  "MessageTimeout" INT 0 65535;
BA_DEF_ BO_  "GenMsgStartDelayTime" INT 0 0;
BA_DEF_ BO_  "GenMsgSendType" ENUM  "Cyclic","Event","Mixed","cyclicX","not_used","not_used","not_used","not_used","NoMsgSendType";
BA_DEF_ BO_  "GenMsgNrOfRepetition" INT 0 0;
BA_DEF_ BO_  "GenMsgILSupport" ENUM  "No","Yes";
BA_DEF_ BO_  "GenMsgCycleTimeFast" INT 0 0;
BA_DEF_ BO_  "GenMsgCycleTime" INT 0 65535;
BA_DEF_ BO_  "DiagUudtResponse" ENUM  "false","true";
BA_DEF_ BO_  "DiagUsdtResponse" ENUM  "false","true";
BA_DEF_ BO_  "DiagResponse" ENUM  "No","Yes";
BA_DEF_ BO_  "DiagRequest" ENUM  "No","Yes";
BA_DEF_DEF_  "SignalType" "";
BA_DEF_DEF_  "Remarks" "null";
BA_DEF_DEF_  "NWM_WakeupAllowed" "No";
BA_DEF_DEF_  "GenSigTimeoutTime_HU_Mid_X451" 500;
BA_DEF_DEF_  "GenSigTimeoutTime_HU_High_X451" 500;
BA_DEF_DEF_  "GenSigTimeoutTime_HU_B" 500;
BA_DEF_DEF_  "GenSigTimeoutTime_HU_A" 500;
BA_DEF_DEF_  "GenSigTimeoutTime_BCM_Mid" 0;
BA_DEF_DEF_  "GenSigTimeoutMsg_HU_Mid_X451" 500;
BA_DEF_DEF_  "GenSigTimeoutMsg_HU_High_X451" 500;
BA_DEF_DEF_  "GenSigTimeoutMsg_HU_B" 500;
BA_DEF_DEF_  "GenSigTimeoutMsg_HU_A" 500;
BA_DEF_DEF_  "GenSigStartValue" 0;
BA_DEF_DEF_  "GenSigSendType" "Cyclic";
BA_DEF_DEF_  "GenSigInactiveValue" 0;
BA_DEF_DEF_  "GenSigEnvVarType" "undef";
BA_DEF_DEF_  "GenSigCycleTimeActive" 0;
BA_DEF_DEF_  "GenSigCycleTime" 0;
BA_DEF_DEF_  "GenSigTimeoutMsg_HU_High_X445" 500;
BA_DEF_DEF_  "GenSigTimeoutMsg_HU_Mid_X445" 500;
BA_DEF_DEF_  "GenSigTimeoutTime_HU_High_X445" 500;
BA_DEF_DEF_  "GenSigTimeoutTime_HU_Mid_X445" 500;
BA_DEF_DEF_  "NmMessage" "no";
BA_DEF_DEF_  "NmAsrMessage" "<n.a.>";
BA_DEF_DEF_  "MessageTimeout" 500;
BA_DEF_DEF_  "GenMsgStartDelayTime" 0;
BA_DEF_DEF_  "GenMsgSendType" "NoMsgSendType";
BA_DEF_DEF_  "GenMsgNrOfRepetition" 0;
BA_DEF_DEF_  "GenMsgILSupport" "Yes";
BA_DEF_DEF_  "GenMsgCycleTimeFast" 0;
BA_DEF_DEF_  "GenMsgCycleTime" 0;
BA_DEF_DEF_  "DiagUudtResponse" "false";
BA_DEF_DEF_  "DiagUsdtResponse" "false";
BA_DEF_DEF_  "DiagResponse" "No";
BA_DEF_DEF_  "DiagRequest" "No";
BA_ "GenMsgCycleTime" BO_ 724 100;
BA_ "GenMsgCycleTime" BO_ 408 20;
BA_ "GenMsgCycleTimeFast" BO_ 495 200;
BA_ "GenMsgNrOfRepetition" BO_ 495 10;
BA_ "MessageTimeout" BO_ 495 0;
BA_ "GenMsgCycleTime" BO_ 617 100;
BA_ "GenMsgCycleTimeFast" BO_ 617 100;
BA_ "GenMsgCycleTime" BO_ 580 100;
BA_ "GenMsgCycleTime" BO_ 579 100;
BA_ "GenMsgCycleTime" BO_ 273 10;
BA_ "GenMsgSendType" BO_ 273 0;
BA_ "MessageTimeout" BO_ 257 0;
BA_ "GenMsgCycleTime" BO_ 259 100;
BA_ "GenMsgCycleTimeFast" BO_ 259 20;
BA_ "GenMsgNrOfRepetition" BO_ 259 4;
BA_ "GenMsgSendType" BO_ 259 0;
BA_ "GenMsgCycleTime" BO_ 262 10;
BA_ "GenMsgSendType" BO_ 262 0;
BA_ "GenMsgStartDelayTime" BO_ 262 3;
BA_ "GenMsgCycleTime" BO_ 370 20;
BA_ "GenMsgSendType" BO_ 370 0;
BA_ "GenMsgCycleTime" BO_ 374 20;
BA_ "GenMsgSendType" BO_ 374 0;
BA_ "GenMsgCycleTime" BO_ 646 100;
BA_ "GenMsgSendType" BO_ 646 0;
BA_ "GenMsgStartDelayTime" BO_ 646 18;
BA_ "GenMsgCycleTime" BO_ 697 100;
BA_ "GenMsgSendType" BO_ 697 0;
BA_ "GenMsgStartDelayTime" BO_ 697 15;
BA_ "GenMsgCycleTime" BO_ 699 100;
BA_ "GenMsgCycleTime" BO_ 946 500;
BA_ "GenMsgSendType" BO_ 946 0;
BA_ "MessageTimeout" BO_ 946 2500;
BA_ "GenMsgCycleTime" BO_ 948 500;
BA_ "MessageTimeout" BO_ 948 2500;
BA_ "GenMsgCycleTime" BO_ 1136 100;
BA_ "GenMsgSendType" BO_ 1136 0;
BA_ "GenMsgStartDelayTime" BO_ 1136 10;
BA_ "GenMsgCycleTime" BO_ 1274 1000;
BA_ "GenMsgSendType" BO_ 1274 0;
BA_ "MessageTimeout" BO_ 1274 5000;
BA_ "GenMsgCycleTime" BO_ 1276 1000;
BA_ "GenMsgSendType" BO_ 1276 0;
BA_ "GenMsgStartDelayTime" BO_ 1276 45;
BA_ "MessageTimeout" BO_ 1276 5000;
BA_ "GenMsgCycleTime" BO_ 1278 1000;
BA_ "GenMsgSendType" BO_ 1278 0;
BA_ "MessageTimeout" BO_ 1278 5000;
BA_ "GenMsgCycleTime" BO_ 1280 200;
BA_ "GenMsgSendType" BO_ 1280 0;
BA_ "MessageTimeout" BO_ 1280 1000;
BA_ "GenMsgCycleTime" BO_ 515 10;
BA_ "GenMsgCycleTime" BO_ 516 10;
BA_ "GenMsgCycleTime" BO_ 519 10;
BA_ "GenMsgCycleTime" BO_ 529 10;
BA_ "GenMsgCycleTime" BO_ 769 10;
BA_ "GenMsgCycleTime" BO_ 770 10;
BA_ "GenMsgCycleTime" BO_ 771 10;
BA_ "GenMsgCycleTime" BO_ 772 10;
BA_ "GenMsgCycleTime" BO_ 775 10;
BA_ "GenMsgCycleTime" BO_ 1586 10;
BA_ "GenMsgCycleTime" BO_ 277 10;
BA_ "GenSigCycleTime" SG_ 724 PtcTempValStatus 100;
BA_ "GenSigCycleTimeActive" SG_ 724 PtcTempValStatus 100;
BA_ "GenSigSendType" SG_ 724 PtcTempValStatus 7;
BA_ "GenSigStartValue" SG_ 724 PtcTempValStatus 2;
BA_ "GenSigTimeoutMsg_HU_A" SG_ 724 PtcTempValStatus 0;
BA_ "GenSigTimeoutMsg_HU_B" SG_ 724 PtcTempValStatus 0;
BA_ "GenSigTimeoutMsg_HU_High_X451" SG_ 724 PtcTempValStatus 0;
BA_ "GenSigTimeoutMsg_HU_Mid_X451" SG_ 724 PtcTempValStatus 0;
BA_ "GenSigTimeoutTime_HU_A" SG_ 724 PtcTempValStatus 0;
BA_ "GenSigTimeoutTime_HU_B" SG_ 724 PtcTempValStatus 0;
BA_ "GenSigTimeoutTime_HU_High_X451" SG_ 724 PtcTempValStatus 0;
BA_ "GenSigTimeoutTime_HU_Mid_X451" SG_ 724 PtcTempValStatus 0;
BA_ "GenSigCycleTime" SG_ 724 PtcTempVal 100;
BA_ "GenSigCycleTimeActive" SG_ 724 PtcTempVal 100;
BA_ "GenSigSendType" SG_ 724 PtcTempVal 7;
BA_ "GenSigStartValue" SG_ 724 PtcTempVal 40;
BA_ "GenSigTimeoutMsg_HU_A" SG_ 724 PtcTempVal 0;
BA_ "GenSigTimeoutMsg_HU_B" SG_ 724 PtcTempVal 0;
BA_ "GenSigTimeoutMsg_HU_High_X451" SG_ 724 PtcTempVal 0;
BA_ "GenSigTimeoutMsg_HU_Mid_X451" SG_ 724 PtcTempVal 0;
BA_ "GenSigTimeoutTime_HU_A" SG_ 724 PtcTempVal 0;
BA_ "GenSigTimeoutTime_HU_B" SG_ 724 PtcTempVal 0;
BA_ "GenSigTimeoutTime_HU_High_X451" SG_ 724 PtcTempVal 0;
BA_ "GenSigTimeoutTime_HU_Mid_X451" SG_ 724 PtcTempVal 0;
BA_ "GenSigCycleTime" SG_ 724 CCMVbatStatus 100;
BA_ "GenSigCycleTimeActive" SG_ 724 CCMVbatStatus 100;
BA_ "GenSigSendType" SG_ 724 CCMVbatStatus 7;
BA_ "GenSigTimeoutMsg_HU_A" SG_ 724 CCMVbatStatus 0;
BA_ "GenSigTimeoutMsg_HU_B" SG_ 724 CCMVbatStatus 0;
BA_ "GenSigTimeoutMsg_HU_High_X451" SG_ 724 CCMVbatStatus 0;
BA_ "GenSigTimeoutMsg_HU_Mid_X451" SG_ 724 CCMVbatStatus 0;
BA_ "GenSigTimeoutTime_HU_A" SG_ 724 CCMVbatStatus 0;
BA_ "GenSigTimeoutTime_HU_B" SG_ 724 CCMVbatStatus 0;
BA_ "GenSigTimeoutTime_HU_High_X451" SG_ 724 CCMVbatStatus 0;
BA_ "GenSigTimeoutTime_HU_Mid_X451" SG_ 724 CCMVbatStatus 0;
BA_ "GenSigCycleTime" SG_ 724 CCMVbat 100;
BA_ "GenSigCycleTimeActive" SG_ 724 CCMVbat 100;
BA_ "GenSigSendType" SG_ 724 CCMVbat 7;
BA_ "GenSigTimeoutMsg_HU_A" SG_ 724 CCMVbat 0;
BA_ "GenSigTimeoutMsg_HU_B" SG_ 724 CCMVbat 0;
BA_ "GenSigTimeoutMsg_HU_High_X451" SG_ 724 CCMVbat 0;
BA_ "GenSigTimeoutMsg_HU_Mid_X451" SG_ 724 CCMVbat 0;
BA_ "GenSigTimeoutTime_HU_A" SG_ 724 CCMVbat 0;
BA_ "GenSigTimeoutTime_HU_B" SG_ 724 CCMVbat 0;
BA_ "GenSigTimeoutTime_HU_High_X451" SG_ 724 CCMVbat 0;
BA_ "GenSigTimeoutTime_HU_Mid_X451" SG_ 724 CCMVbat 0;
BA_ "GenSigCycleTime" SG_ 724 BlowerFBVoltageStatus 100;
BA_ "GenSigCycleTimeActive" SG_ 724 BlowerFBVoltageStatus 100;
BA_ "GenSigSendType" SG_ 724 BlowerFBVoltageStatus 7;
BA_ "GenSigTimeoutMsg_HU_A" SG_ 724 BlowerFBVoltageStatus 0;
BA_ "GenSigTimeoutMsg_HU_B" SG_ 724 BlowerFBVoltageStatus 0;
BA_ "GenSigTimeoutMsg_HU_High_X451" SG_ 724 BlowerFBVoltageStatus 0;
BA_ "GenSigTimeoutMsg_HU_Mid_X451" SG_ 724 BlowerFBVoltageStatus 0;
BA_ "GenSigTimeoutTime_HU_A" SG_ 724 BlowerFBVoltageStatus 0;
BA_ "GenSigTimeoutTime_HU_B" SG_ 724 BlowerFBVoltageStatus 0;
BA_ "GenSigTimeoutTime_HU_High_X451" SG_ 724 BlowerFBVoltageStatus 0;
BA_ "GenSigTimeoutTime_HU_Mid_X451" SG_ 724 BlowerFBVoltageStatus 0;
BA_ "GenSigCycleTime" SG_ 724 BlowerFBVoltage 100;
BA_ "GenSigCycleTimeActive" SG_ 724 BlowerFBVoltage 100;
BA_ "GenSigSendType" SG_ 724 BlowerFBVoltage 7;
BA_ "GenSigTimeoutMsg_HU_A" SG_ 724 BlowerFBVoltage 0;
BA_ "GenSigTimeoutMsg_HU_B" SG_ 724 BlowerFBVoltage 0;
BA_ "GenSigTimeoutMsg_HU_High_X451" SG_ 724 BlowerFBVoltage 0;
BA_ "GenSigTimeoutMsg_HU_Mid_X451" SG_ 724 BlowerFBVoltage 0;
BA_ "GenSigTimeoutTime_HU_A" SG_ 724 BlowerFBVoltage 0;
BA_ "GenSigTimeoutTime_HU_B" SG_ 724 BlowerFBVoltage 0;
BA_ "GenSigTimeoutTime_HU_High_X451" SG_ 724 BlowerFBVoltage 0;
BA_ "GenSigTimeoutTime_HU_Mid_X451" SG_ 724 BlowerFBVoltage 0;
BA_ "GenSigCycleTime" SG_ 724 BlowerPWMStatus 100;
BA_ "GenSigCycleTimeActive" SG_ 724 BlowerPWMStatus 100;
BA_ "GenSigSendType" SG_ 724 BlowerPWMStatus 7;
BA_ "GenSigTimeoutMsg_HU_A" SG_ 724 BlowerPWMStatus 0;
BA_ "GenSigTimeoutMsg_HU_B" SG_ 724 BlowerPWMStatus 0;
BA_ "GenSigTimeoutMsg_HU_High_X451" SG_ 724 BlowerPWMStatus 0;
BA_ "GenSigTimeoutMsg_HU_Mid_X451" SG_ 724 BlowerPWMStatus 0;
BA_ "GenSigTimeoutTime_HU_A" SG_ 724 BlowerPWMStatus 0;
BA_ "GenSigTimeoutTime_HU_B" SG_ 724 BlowerPWMStatus 0;
BA_ "GenSigTimeoutTime_HU_High_X451" SG_ 724 BlowerPWMStatus 0;
BA_ "GenSigTimeoutTime_HU_Mid_X451" SG_ 724 BlowerPWMStatus 0;
BA_ "GenSigCycleTime" SG_ 724 BlowerPWM 100;
BA_ "GenSigCycleTimeActive" SG_ 724 BlowerPWM 100;
BA_ "GenSigSendType" SG_ 724 BlowerPWM 7;
BA_ "GenSigTimeoutMsg_HU_A" SG_ 724 BlowerPWM 0;
BA_ "GenSigTimeoutMsg_HU_B" SG_ 724 BlowerPWM 0;
BA_ "GenSigTimeoutMsg_HU_High_X451" SG_ 724 BlowerPWM 0;
BA_ "GenSigTimeoutMsg_HU_Mid_X451" SG_ 724 BlowerPWM 0;
BA_ "GenSigTimeoutTime_HU_A" SG_ 724 BlowerPWM 0;
BA_ "GenSigTimeoutTime_HU_B" SG_ 724 BlowerPWM 0;
BA_ "GenSigTimeoutTime_HU_High_X451" SG_ 724 BlowerPWM 0;
BA_ "GenSigTimeoutTime_HU_Mid_X451" SG_ 724 BlowerPWM 0;
BA_ "GenSigCycleTime" SG_ 724 BlowerStatus 100;
BA_ "GenSigCycleTimeActive" SG_ 724 BlowerStatus 100;
BA_ "GenSigSendType" SG_ 724 BlowerStatus 7;
BA_ "GenSigTimeoutMsg_HU_A" SG_ 724 BlowerStatus 0;
BA_ "GenSigTimeoutMsg_HU_B" SG_ 724 BlowerStatus 0;
BA_ "GenSigTimeoutMsg_HU_High_X451" SG_ 724 BlowerStatus 0;
BA_ "GenSigTimeoutMsg_HU_Mid_X451" SG_ 724 BlowerStatus 0;
BA_ "GenSigTimeoutTime_HU_A" SG_ 724 BlowerStatus 0;
BA_ "GenSigTimeoutTime_HU_B" SG_ 724 BlowerStatus 0;
BA_ "GenSigTimeoutTime_HU_High_X451" SG_ 724 BlowerStatus 0;
BA_ "GenSigTimeoutTime_HU_Mid_X451" SG_ 724 BlowerStatus 0;
BA_ "GenSigCycleTime" SG_ 724 BlowerState 100;
BA_ "GenSigCycleTimeActive" SG_ 724 BlowerState 100;
BA_ "GenSigSendType" SG_ 724 BlowerState 7;
BA_ "GenSigTimeoutMsg_HU_A" SG_ 724 BlowerState 0;
BA_ "GenSigTimeoutMsg_HU_B" SG_ 724 BlowerState 0;
BA_ "GenSigTimeoutMsg_HU_High_X451" SG_ 724 BlowerState 0;
BA_ "GenSigTimeoutMsg_HU_Mid_X451" SG_ 724 BlowerState 0;
BA_ "GenSigTimeoutTime_HU_A" SG_ 724 BlowerState 0;
BA_ "GenSigTimeoutTime_HU_B" SG_ 724 BlowerState 0;
BA_ "GenSigTimeoutTime_HU_High_X451" SG_ 724 BlowerState 0;
BA_ "GenSigTimeoutTime_HU_Mid_X451" SG_ 724 BlowerState 0;
BA_ "GenSigCycleTime" SG_ 724 HeatingPwrValStatus 100;
BA_ "GenSigCycleTimeActive" SG_ 724 HeatingPwrValStatus 100;
BA_ "GenSigSendType" SG_ 724 HeatingPwrValStatus 7;
BA_ "GenSigStartValue" SG_ 724 HeatingPwrValStatus 2;
BA_ "GenSigTimeoutMsg_HU_A" SG_ 724 HeatingPwrValStatus 0;
BA_ "GenSigTimeoutMsg_HU_B" SG_ 724 HeatingPwrValStatus 0;
BA_ "GenSigTimeoutMsg_HU_High_X451" SG_ 724 HeatingPwrValStatus 0;
BA_ "GenSigTimeoutMsg_HU_Mid_X451" SG_ 724 HeatingPwrValStatus 0;
BA_ "GenSigTimeoutTime_HU_A" SG_ 724 HeatingPwrValStatus 0;
BA_ "GenSigTimeoutTime_HU_B" SG_ 724 HeatingPwrValStatus 0;
BA_ "GenSigTimeoutTime_HU_High_X451" SG_ 724 HeatingPwrValStatus 0;
BA_ "GenSigTimeoutTime_HU_Mid_X451" SG_ 724 HeatingPwrValStatus 0;
BA_ "GenSigCycleTime" SG_ 724 HeatingPwrVal 100;
BA_ "GenSigCycleTimeActive" SG_ 724 HeatingPwrVal 100;
BA_ "GenSigSendType" SG_ 724 HeatingPwrVal 7;
BA_ "GenSigTimeoutMsg_HU_A" SG_ 724 HeatingPwrVal 0;
BA_ "GenSigTimeoutMsg_HU_B" SG_ 724 HeatingPwrVal 0;
BA_ "GenSigTimeoutMsg_HU_High_X451" SG_ 724 HeatingPwrVal 0;
BA_ "GenSigTimeoutMsg_HU_Mid_X451" SG_ 724 HeatingPwrVal 0;
BA_ "GenSigTimeoutTime_HU_A" SG_ 724 HeatingPwrVal 0;
BA_ "GenSigTimeoutTime_HU_B" SG_ 724 HeatingPwrVal 0;
BA_ "GenSigTimeoutTime_HU_High_X451" SG_ 724 HeatingPwrVal 0;
BA_ "GenSigTimeoutTime_HU_Mid_X451" SG_ 724 HeatingPwrVal 0;
BA_ "GenSigCycleTime" SG_ 724 CoolingPwrValStatus 100;
BA_ "GenSigCycleTimeActive" SG_ 724 CoolingPwrValStatus 100;
BA_ "GenSigSendType" SG_ 724 CoolingPwrValStatus 7;
BA_ "GenSigStartValue" SG_ 724 CoolingPwrValStatus 2;
BA_ "GenSigTimeoutMsg_HU_A" SG_ 724 CoolingPwrValStatus 0;
BA_ "GenSigTimeoutMsg_HU_B" SG_ 724 CoolingPwrValStatus 0;
BA_ "GenSigTimeoutMsg_HU_High_X451" SG_ 724 CoolingPwrValStatus 0;
BA_ "GenSigTimeoutMsg_HU_Mid_X451" SG_ 724 CoolingPwrValStatus 0;
BA_ "GenSigTimeoutTime_HU_A" SG_ 724 CoolingPwrValStatus 0;
BA_ "GenSigTimeoutTime_HU_B" SG_ 724 CoolingPwrValStatus 0;
BA_ "GenSigTimeoutTime_HU_High_X451" SG_ 724 CoolingPwrValStatus 0;
BA_ "GenSigTimeoutTime_HU_Mid_X451" SG_ 724 CoolingPwrValStatus 0;
BA_ "GenSigCycleTime" SG_ 724 CoolingPwrVal 100;
BA_ "GenSigCycleTimeActive" SG_ 724 CoolingPwrVal 100;
BA_ "GenSigSendType" SG_ 724 CoolingPwrVal 7;
BA_ "GenSigTimeoutMsg_HU_A" SG_ 724 CoolingPwrVal 0;
BA_ "GenSigTimeoutMsg_HU_B" SG_ 724 CoolingPwrVal 0;
BA_ "GenSigTimeoutMsg_HU_High_X451" SG_ 724 CoolingPwrVal 0;
BA_ "GenSigTimeoutMsg_HU_Mid_X451" SG_ 724 CoolingPwrVal 0;
BA_ "GenSigTimeoutTime_HU_A" SG_ 724 CoolingPwrVal 0;
BA_ "GenSigTimeoutTime_HU_B" SG_ 724 CoolingPwrVal 0;
BA_ "GenSigTimeoutTime_HU_High_X451" SG_ 724 CoolingPwrVal 0;
BA_ "GenSigTimeoutTime_HU_Mid_X451" SG_ 724 CoolingPwrVal 0;
BA_ "GenSigCycleTime" SG_ 724 AcReqNew 100;
BA_ "GenSigCycleTimeActive" SG_ 724 AcReqNew 100;
BA_ "GenSigSendType" SG_ 724 AcReqNew 7;
BA_ "GenSigTimeoutMsg_HU_A" SG_ 724 AcReqNew 0;
BA_ "GenSigTimeoutMsg_HU_B" SG_ 724 AcReqNew 0;
BA_ "GenSigTimeoutMsg_HU_High_X451" SG_ 724 AcReqNew 0;
BA_ "GenSigTimeoutMsg_HU_Mid_X451" SG_ 724 AcReqNew 0;
BA_ "GenSigTimeoutTime_HU_A" SG_ 724 AcReqNew 0;
BA_ "GenSigTimeoutTime_HU_B" SG_ 724 AcReqNew 0;
BA_ "GenSigTimeoutTime_HU_High_X451" SG_ 724 AcReqNew 0;
BA_ "GenSigTimeoutTime_HU_Mid_X451" SG_ 724 AcReqNew 0;
BA_ "GenSigCycleTime" SG_ 408 ICDispSpeedSigStatus 20;
BA_ "GenSigCycleTimeActive" SG_ 408 ICDispSpeedSigStatus 20;
BA_ "GenSigSendType" SG_ 408 ICDispSpeedSigStatus 7;
BA_ "GenSigStartValue" SG_ 408 ICDispSpeedSigStatus 2;
BA_ "GenSigTimeoutMsg_HU_A" SG_ 408 ICDispSpeedSigStatus 0;
BA_ "GenSigTimeoutMsg_HU_B" SG_ 408 ICDispSpeedSigStatus 0;
BA_ "GenSigTimeoutMsg_HU_High_X451" SG_ 408 ICDispSpeedSigStatus 0;
BA_ "GenSigTimeoutMsg_HU_Mid_X451" SG_ 408 ICDispSpeedSigStatus 0;
BA_ "GenSigTimeoutTime_HU_A" SG_ 408 ICDispSpeedSigStatus 0;
BA_ "GenSigTimeoutTime_HU_B" SG_ 408 ICDispSpeedSigStatus 0;
BA_ "GenSigTimeoutTime_HU_High_X451" SG_ 408 ICDispSpeedSigStatus 0;
BA_ "GenSigTimeoutTime_HU_Mid_X451" SG_ 408 ICDispSpeedSigStatus 0;
BA_ "GenSigCycleTime" SG_ 408 ICDispSpeedSig 20;
BA_ "GenSigCycleTimeActive" SG_ 408 ICDispSpeedSig 20;
BA_ "GenSigSendType" SG_ 408 ICDispSpeedSig 7;
BA_ "GenSigTimeoutMsg_HU_A" SG_ 408 ICDispSpeedSig 0;
BA_ "GenSigTimeoutMsg_HU_B" SG_ 408 ICDispSpeedSig 0;
BA_ "GenSigTimeoutMsg_HU_High_X451" SG_ 408 ICDispSpeedSig 0;
BA_ "GenSigTimeoutMsg_HU_Mid_X451" SG_ 408 ICDispSpeedSig 0;
BA_ "GenSigTimeoutTime_HU_A" SG_ 408 ICDispSpeedSig 0;
BA_ "GenSigTimeoutTime_HU_B" SG_ 408 ICDispSpeedSig 0;
BA_ "GenSigTimeoutTime_HU_High_X451" SG_ 408 ICDispSpeedSig 0;
BA_ "GenSigTimeoutTime_HU_Mid_X451" SG_ 408 ICDispSpeedSig 0;
BA_ "GenSigSendType" SG_ 495 RemoteValetCmdStatus 2;
BA_ "GenSigStartValue" SG_ 495 RemoteValetCmdStatus 1;
BA_ "GenSigTimeoutMsg_HU_A" SG_ 495 RemoteValetCmdStatus 0;
BA_ "GenSigTimeoutMsg_HU_B" SG_ 495 RemoteValetCmdStatus 0;
BA_ "GenSigTimeoutMsg_HU_High_X451" SG_ 495 RemoteValetCmdStatus 0;
BA_ "GenSigTimeoutMsg_HU_Mid_X451" SG_ 495 RemoteValetCmdStatus 0;
BA_ "GenSigTimeoutTime_HU_A" SG_ 495 RemoteValetCmdStatus 0;
BA_ "GenSigTimeoutTime_HU_B" SG_ 495 RemoteValetCmdStatus 0;
BA_ "GenSigTimeoutTime_HU_High_X451" SG_ 495 RemoteValetCmdStatus 0;
BA_ "GenSigTimeoutTime_HU_Mid_X451" SG_ 495 RemoteValetCmdStatus 0;
BA_ "GenSigSendType" SG_ 495 RemoteValetCmd 2;
BA_ "GenSigTimeoutMsg_HU_A" SG_ 495 RemoteValetCmd 0;
BA_ "GenSigTimeoutMsg_HU_B" SG_ 495 RemoteValetCmd 0;
BA_ "GenSigTimeoutMsg_HU_High_X451" SG_ 495 RemoteValetCmd 0;
BA_ "GenSigTimeoutMsg_HU_Mid_X451" SG_ 495 RemoteValetCmd 0;
BA_ "GenSigTimeoutTime_HU_A" SG_ 495 RemoteValetCmd 0;
BA_ "GenSigTimeoutTime_HU_B" SG_ 495 RemoteValetCmd 0;
BA_ "GenSigTimeoutTime_HU_High_X451" SG_ 495 RemoteValetCmd 0;
BA_ "GenSigTimeoutTime_HU_Mid_X451" SG_ 495 RemoteValetCmd 0;
BA_ "GenSigCycleTime" SG_ 617 GearSelectionSwStateStatus 100;
BA_ "GenSigCycleTimeActive" SG_ 617 GearSelectionSwStateStatus 100;
BA_ "GenSigSendType" SG_ 617 GearSelectionSwStateStatus 7;
BA_ "GenSigTimeoutMsg_HU_A" SG_ 617 GearSelectionSwStateStatus 0;
BA_ "GenSigTimeoutMsg_HU_B" SG_ 617 GearSelectionSwStateStatus 0;
BA_ "GenSigTimeoutMsg_HU_High_X451" SG_ 617 GearSelectionSwStateStatus 0;
BA_ "GenSigTimeoutMsg_HU_Mid_X451" SG_ 617 GearSelectionSwStateStatus 0;
BA_ "GenSigTimeoutTime_HU_A" SG_ 617 GearSelectionSwStateStatus 0;
BA_ "GenSigTimeoutTime_HU_B" SG_ 617 GearSelectionSwStateStatus 0;
BA_ "GenSigTimeoutTime_HU_High_X451" SG_ 617 GearSelectionSwStateStatus 0;
BA_ "GenSigTimeoutTime_HU_Mid_X451" SG_ 617 GearSelectionSwStateStatus 0;
BA_ "GenSigCycleTime" SG_ 617 GearSelectionSwState 100;
BA_ "GenSigCycleTimeActive" SG_ 617 GearSelectionSwState 100;
BA_ "GenSigSendType" SG_ 617 GearSelectionSwState 7;
BA_ "GenSigTimeoutMsg_HU_A" SG_ 617 GearSelectionSwState 0;
BA_ "GenSigTimeoutMsg_HU_B" SG_ 617 GearSelectionSwState 0;
BA_ "GenSigTimeoutMsg_HU_High_X451" SG_ 617 GearSelectionSwState 0;
BA_ "GenSigTimeoutMsg_HU_Mid_X451" SG_ 617 GearSelectionSwState 0;
BA_ "GenSigTimeoutTime_HU_A" SG_ 617 GearSelectionSwState 0;
BA_ "GenSigTimeoutTime_HU_B" SG_ 617 GearSelectionSwState 0;
BA_ "GenSigTimeoutTime_HU_High_X451" SG_ 617 GearSelectionSwState 0;
BA_ "GenSigTimeoutTime_HU_Mid_X451" SG_ 617 GearSelectionSwState 0;
BA_ "GenSigCycleTime" SG_ 617 GSSFailureStatusSignal 100;
BA_ "GenSigCycleTimeActive" SG_ 617 GSSFailureStatusSignal 100;
BA_ "GenSigSendType" SG_ 617 GSSFailureStatusSignal 7;
BA_ "GenSigTimeoutMsg_HU_A" SG_ 617 GSSFailureStatusSignal 0;
BA_ "GenSigTimeoutMsg_HU_B" SG_ 617 GSSFailureStatusSignal 0;
BA_ "GenSigTimeoutMsg_HU_High_X451" SG_ 617 GSSFailureStatusSignal 0;
BA_ "GenSigTimeoutMsg_HU_Mid_X451" SG_ 617 GSSFailureStatusSignal 0;
BA_ "GenSigTimeoutTime_HU_A" SG_ 617 GSSFailureStatusSignal 0;
BA_ "GenSigTimeoutTime_HU_B" SG_ 617 GSSFailureStatusSignal 0;
BA_ "GenSigTimeoutTime_HU_High_X451" SG_ 617 GSSFailureStatusSignal 0;
BA_ "GenSigTimeoutTime_HU_Mid_X451" SG_ 617 GSSFailureStatusSignal 0;
BA_ "GenSigCycleTime" SG_ 580 VehicleStatus 100;
BA_ "GenSigCycleTimeActive" SG_ 580 VehicleStatus 100;
BA_ "GenSigSendType" SG_ 580 VehicleStatus 7;
BA_ "GenSigTimeoutMsg_HU_A" SG_ 580 VehicleStatus 0;
BA_ "GenSigTimeoutMsg_HU_B" SG_ 580 VehicleStatus 0;
BA_ "GenSigTimeoutMsg_HU_High_X451" SG_ 580 VehicleStatus 0;
BA_ "GenSigTimeoutMsg_HU_Mid_X451" SG_ 580 VehicleStatus 0;
BA_ "GenSigTimeoutTime_HU_A" SG_ 580 VehicleStatus 0;
BA_ "GenSigTimeoutTime_HU_B" SG_ 580 VehicleStatus 0;
BA_ "GenSigTimeoutTime_HU_High_X451" SG_ 580 VehicleStatus 0;
BA_ "GenSigTimeoutTime_HU_Mid_X451" SG_ 580 VehicleStatus 0;
BA_ "GenSigTimeoutTime_HU_Mid_X445" SG_ 580 VcuStatus 0;
BA_ "GenSigTimeoutTime_HU_High_X445" SG_ 580 VcuStatus 0;
BA_ "GenSigTimeoutMsg_HU_Mid_X445" SG_ 580 VcuStatus 0;
BA_ "GenSigTimeoutMsg_HU_High_X445" SG_ 580 VcuStatus 0;
BA_ "GenSigCycleTime" SG_ 580 VcuStatus 100;
BA_ "GenSigCycleTimeActive" SG_ 580 VcuStatus 100;
BA_ "GenSigSendType" SG_ 580 VcuStatus 7;
BA_ "GenSigTimeoutMsg_HU_A" SG_ 580 VcuStatus 0;
BA_ "GenSigTimeoutMsg_HU_B" SG_ 580 VcuStatus 0;
BA_ "GenSigTimeoutMsg_HU_High_X451" SG_ 580 VcuStatus 0;
BA_ "GenSigTimeoutMsg_HU_Mid_X451" SG_ 580 VcuStatus 0;
BA_ "GenSigTimeoutTime_HU_A" SG_ 580 VcuStatus 0;
BA_ "GenSigTimeoutTime_HU_B" SG_ 580 VcuStatus 0;
BA_ "GenSigTimeoutTime_HU_High_X451" SG_ 580 VcuStatus 0;
BA_ "GenSigTimeoutTime_HU_Mid_X451" SG_ 580 VcuStatus 0;
BA_ "GenSigTimeoutTime_HU_Mid_X445" SG_ 580 ValetStateStatus 0;
BA_ "GenSigTimeoutTime_HU_High_X445" SG_ 580 ValetStateStatus 0;
BA_ "GenSigTimeoutMsg_HU_Mid_X445" SG_ 580 ValetStateStatus 0;
BA_ "GenSigTimeoutMsg_HU_High_X445" SG_ 580 ValetStateStatus 0;
BA_ "GenSigCycleTime" SG_ 580 ValetStateStatus 100;
BA_ "GenSigCycleTimeActive" SG_ 580 ValetStateStatus 100;
BA_ "GenSigSendType" SG_ 580 ValetStateStatus 7;
BA_ "GenSigTimeoutMsg_HU_A" SG_ 580 ValetStateStatus 0;
BA_ "GenSigTimeoutMsg_HU_B" SG_ 580 ValetStateStatus 0;
BA_ "GenSigTimeoutMsg_HU_High_X451" SG_ 580 ValetStateStatus 0;
BA_ "GenSigTimeoutMsg_HU_Mid_X451" SG_ 580 ValetStateStatus 0;
BA_ "GenSigTimeoutTime_HU_A" SG_ 580 ValetStateStatus 0;
BA_ "GenSigTimeoutTime_HU_B" SG_ 580 ValetStateStatus 0;
BA_ "GenSigTimeoutTime_HU_High_X451" SG_ 580 ValetStateStatus 0;
BA_ "GenSigTimeoutTime_HU_Mid_X451" SG_ 580 ValetStateStatus 0;
BA_ "GenSigTimeoutTime_HU_Mid_X445" SG_ 580 ValetState 0;
BA_ "GenSigTimeoutTime_HU_High_X445" SG_ 580 ValetState 0;
BA_ "GenSigTimeoutMsg_HU_Mid_X445" SG_ 580 ValetState 0;
BA_ "GenSigTimeoutMsg_HU_High_X445" SG_ 580 ValetState 0;
BA_ "GenSigCycleTime" SG_ 580 ValetState 100;
BA_ "GenSigCycleTimeActive" SG_ 580 ValetState 100;
BA_ "GenSigSendType" SG_ 580 ValetState 7;
BA_ "GenSigTimeoutMsg_HU_A" SG_ 580 ValetState 0;
BA_ "GenSigTimeoutMsg_HU_B" SG_ 580 ValetState 0;
BA_ "GenSigTimeoutMsg_HU_High_X451" SG_ 580 ValetState 0;
BA_ "GenSigTimeoutMsg_HU_Mid_X451" SG_ 580 ValetState 0;
BA_ "GenSigTimeoutTime_HU_A" SG_ 580 ValetState 0;
BA_ "GenSigTimeoutTime_HU_B" SG_ 580 ValetState 0;
BA_ "GenSigTimeoutTime_HU_High_X451" SG_ 580 ValetState 0;
BA_ "GenSigTimeoutTime_HU_Mid_X451" SG_ 580 ValetState 0;
BA_ "GenSigTimeoutTime_HU_Mid_X445" SG_ 580 AcComprMalFn 0;
BA_ "GenSigTimeoutTime_HU_High_X445" SG_ 580 AcComprMalFn 0;
BA_ "GenSigTimeoutMsg_HU_Mid_X445" SG_ 580 AcComprMalFn 0;
BA_ "GenSigTimeoutMsg_HU_High_X445" SG_ 580 AcComprMalFn 0;
BA_ "GenSigCycleTime" SG_ 580 AcComprMalFn 100;
BA_ "GenSigCycleTimeActive" SG_ 580 AcComprMalFn 100;
BA_ "GenSigSendType" SG_ 580 AcComprMalFn 7;
BA_ "GenSigTimeoutMsg_HU_A" SG_ 580 AcComprMalFn 0;
BA_ "GenSigTimeoutMsg_HU_B" SG_ 580 AcComprMalFn 0;
BA_ "GenSigTimeoutMsg_HU_High_X451" SG_ 580 AcComprMalFn 0;
BA_ "GenSigTimeoutMsg_HU_Mid_X451" SG_ 580 AcComprMalFn 0;
BA_ "GenSigTimeoutTime_HU_A" SG_ 580 AcComprMalFn 0;
BA_ "GenSigTimeoutTime_HU_B" SG_ 580 AcComprMalFn 0;
BA_ "GenSigTimeoutTime_HU_High_X451" SG_ 580 AcComprMalFn 0;
BA_ "GenSigTimeoutTime_HU_Mid_X451" SG_ 580 AcComprMalFn 0;
BA_ "GenSigCycleTime" SG_ 580 AcCmprStatusVcu 100;
BA_ "GenSigCycleTimeActive" SG_ 580 AcCmprStatusVcu 100;
BA_ "GenSigSendType" SG_ 580 AcCmprStatusVcu 7;
BA_ "GenSigTimeoutMsg_HU_A" SG_ 580 AcCmprStatusVcu 0;
BA_ "GenSigTimeoutMsg_HU_B" SG_ 580 AcCmprStatusVcu 0;
BA_ "GenSigTimeoutMsg_HU_High_X451" SG_ 580 AcCmprStatusVcu 0;
BA_ "GenSigTimeoutMsg_HU_Mid_X451" SG_ 580 AcCmprStatusVcu 0;
BA_ "GenSigTimeoutTime_HU_A" SG_ 580 AcCmprStatusVcu 0;
BA_ "GenSigTimeoutTime_HU_B" SG_ 580 AcCmprStatusVcu 0;
BA_ "GenSigTimeoutTime_HU_High_X451" SG_ 580 AcCmprStatusVcu 0;
BA_ "GenSigTimeoutTime_HU_Mid_X451" SG_ 580 AcCmprStatusVcu 0;
BA_ "GenSigCycleTime" SG_ 580 VcuPowerMode 100;
BA_ "GenSigCycleTimeActive" SG_ 580 VcuPowerMode 100;
BA_ "GenSigSendType" SG_ 580 VcuPowerMode 7;
BA_ "GenSigTimeoutMsg_HU_A" SG_ 580 VcuPowerMode 0;
BA_ "GenSigTimeoutMsg_HU_B" SG_ 580 VcuPowerMode 0;
BA_ "GenSigTimeoutMsg_HU_High_X451" SG_ 580 VcuPowerMode 0;
BA_ "GenSigTimeoutMsg_HU_Mid_X451" SG_ 580 VcuPowerMode 0;
BA_ "GenSigTimeoutTime_HU_A" SG_ 580 VcuPowerMode 0;
BA_ "GenSigTimeoutTime_HU_B" SG_ 580 VcuPowerMode 0;
BA_ "GenSigTimeoutTime_HU_High_X451" SG_ 580 VcuPowerMode 0;
BA_ "GenSigTimeoutTime_HU_Mid_X451" SG_ 580 VcuPowerMode 0;
BA_ "GenSigCycleTime" SG_ 580 VcuPowerModeStatus 100;
BA_ "GenSigCycleTimeActive" SG_ 580 VcuPowerModeStatus 100;
BA_ "GenSigSendType" SG_ 580 VcuPowerModeStatus 7;
BA_ "GenSigTimeoutMsg_HU_A" SG_ 580 VcuPowerModeStatus 0;
BA_ "GenSigTimeoutMsg_HU_B" SG_ 580 VcuPowerModeStatus 0;
BA_ "GenSigTimeoutMsg_HU_High_X451" SG_ 580 VcuPowerModeStatus 0;
BA_ "GenSigTimeoutMsg_HU_Mid_X451" SG_ 580 VcuPowerModeStatus 0;
BA_ "GenSigTimeoutTime_HU_A" SG_ 580 VcuPowerModeStatus 0;
BA_ "GenSigTimeoutTime_HU_B" SG_ 580 VcuPowerModeStatus 0;
BA_ "GenSigTimeoutTime_HU_High_X451" SG_ 580 VcuPowerModeStatus 0;
BA_ "GenSigTimeoutTime_HU_Mid_X451" SG_ 580 VcuPowerModeStatus 0;
BA_ "GenSigTimeoutTime_HU_Mid_X445" SG_ 579 BrkVacPumpStatus 0;
BA_ "GenSigTimeoutTime_HU_High_X445" SG_ 579 BrkVacPumpStatus 0;
BA_ "GenSigTimeoutMsg_HU_Mid_X445" SG_ 579 BrkVacPumpStatus 0;
BA_ "GenSigTimeoutMsg_HU_High_X445" SG_ 579 BrkVacPumpStatus 0;
BA_ "GenSigCycleTime" SG_ 579 BrkVacPumpStatus 100;
BA_ "GenSigCycleTimeActive" SG_ 579 BrkVacPumpStatus 100;
BA_ "GenSigSendType" SG_ 579 BrkVacPumpStatus 7;
BA_ "GenSigTimeoutMsg_HU_A" SG_ 579 BrkVacPumpStatus 0;
BA_ "GenSigTimeoutMsg_HU_B" SG_ 579 BrkVacPumpStatus 0;
BA_ "GenSigTimeoutMsg_HU_High_X451" SG_ 579 BrkVacPumpStatus 0;
BA_ "GenSigTimeoutMsg_HU_Mid_X451" SG_ 579 BrkVacPumpStatus 0;
BA_ "GenSigTimeoutTime_HU_A" SG_ 579 BrkVacPumpStatus 0;
BA_ "GenSigTimeoutTime_HU_B" SG_ 579 BrkVacPumpStatus 0;
BA_ "GenSigTimeoutTime_HU_High_X451" SG_ 579 BrkVacPumpStatus 0;
BA_ "GenSigTimeoutTime_HU_Mid_X451" SG_ 579 BrkVacPumpStatus 0;
BA_ "GenSigTimeoutTime_HU_Mid_X445" SG_ 579 DriveMotorStatus 0;
BA_ "GenSigTimeoutTime_HU_High_X445" SG_ 579 DriveMotorStatus 0;
BA_ "GenSigTimeoutMsg_HU_Mid_X445" SG_ 579 DriveMotorStatus 0;
BA_ "GenSigTimeoutMsg_HU_High_X445" SG_ 579 DriveMotorStatus 0;
BA_ "GenSigCycleTime" SG_ 579 DriveMotorStatus 100;
BA_ "GenSigCycleTimeActive" SG_ 579 DriveMotorStatus 100;
BA_ "GenSigSendType" SG_ 579 DriveMotorStatus 7;
BA_ "GenSigTimeoutMsg_HU_A" SG_ 579 DriveMotorStatus 0;
BA_ "GenSigTimeoutMsg_HU_B" SG_ 579 DriveMotorStatus 0;
BA_ "GenSigTimeoutMsg_HU_High_X451" SG_ 579 DriveMotorStatus 0;
BA_ "GenSigTimeoutMsg_HU_Mid_X451" SG_ 579 DriveMotorStatus 0;
BA_ "GenSigTimeoutTime_HU_A" SG_ 579 DriveMotorStatus 0;
BA_ "GenSigTimeoutTime_HU_B" SG_ 579 DriveMotorStatus 0;
BA_ "GenSigTimeoutTime_HU_High_X451" SG_ 579 DriveMotorStatus 0;
BA_ "GenSigTimeoutTime_HU_Mid_X451" SG_ 579 DriveMotorStatus 0;
BA_ "GenSigTimeoutTime_HU_Mid_X445" SG_ 579 HvBattSoh 0;
BA_ "GenSigTimeoutTime_HU_High_X445" SG_ 579 HvBattSoh 0;
BA_ "GenSigTimeoutMsg_HU_Mid_X445" SG_ 579 HvBattSoh 0;
BA_ "GenSigTimeoutMsg_HU_High_X445" SG_ 579 HvBattSoh 0;
BA_ "GenSigCycleTime" SG_ 579 HvBattSoh 100;
BA_ "GenSigCycleTimeActive" SG_ 579 HvBattSoh 100;
BA_ "GenSigSendType" SG_ 579 HvBattSoh 7;
BA_ "GenSigTimeoutMsg_HU_A" SG_ 579 HvBattSoh 0;
BA_ "GenSigTimeoutMsg_HU_B" SG_ 579 HvBattSoh 0;
BA_ "GenSigTimeoutMsg_HU_High_X451" SG_ 579 HvBattSoh 0;
BA_ "GenSigTimeoutMsg_HU_Mid_X451" SG_ 579 HvBattSoh 0;
BA_ "GenSigTimeoutTime_HU_A" SG_ 579 HvBattSoh 0;
BA_ "GenSigTimeoutTime_HU_B" SG_ 579 HvBattSoh 0;
BA_ "GenSigTimeoutTime_HU_High_X451" SG_ 579 HvBattSoh 0;
BA_ "GenSigTimeoutTime_HU_Mid_X451" SG_ 579 HvBattSoh 0;
BA_ "GenSigTimeoutTime_HU_Mid_X445" SG_ 579 RegenAmpHr 0;
BA_ "GenSigTimeoutTime_HU_High_X445" SG_ 579 RegenAmpHr 0;
BA_ "GenSigTimeoutMsg_HU_Mid_X445" SG_ 579 RegenAmpHr 0;
BA_ "GenSigTimeoutMsg_HU_High_X445" SG_ 579 RegenAmpHr 0;
BA_ "GenSigCycleTime" SG_ 579 RegenAmpHr 100;
BA_ "GenSigCycleTimeActive" SG_ 579 RegenAmpHr 100;
BA_ "GenSigSendType" SG_ 579 RegenAmpHr 7;
BA_ "GenSigTimeoutMsg_HU_A" SG_ 579 RegenAmpHr 0;
BA_ "GenSigTimeoutMsg_HU_B" SG_ 579 RegenAmpHr 0;
BA_ "GenSigTimeoutMsg_HU_High_X451" SG_ 579 RegenAmpHr 0;
BA_ "GenSigTimeoutMsg_HU_Mid_X451" SG_ 579 RegenAmpHr 0;
BA_ "GenSigTimeoutTime_HU_A" SG_ 579 RegenAmpHr 0;
BA_ "GenSigTimeoutTime_HU_B" SG_ 579 RegenAmpHr 0;
BA_ "GenSigTimeoutTime_HU_High_X451" SG_ 579 RegenAmpHr 0;
BA_ "GenSigTimeoutTime_HU_Mid_X451" SG_ 579 RegenAmpHr 0;
BA_ "GenSigCycleTime" SG_ 579 HvBattPackVolStatus 100;
BA_ "GenSigCycleTimeActive" SG_ 579 HvBattPackVolStatus 100;
BA_ "GenSigSendType" SG_ 579 HvBattPackVolStatus 7;
BA_ "GenSigTimeoutMsg_HU_A" SG_ 579 HvBattPackVolStatus 0;
BA_ "GenSigTimeoutMsg_HU_B" SG_ 579 HvBattPackVolStatus 0;
BA_ "GenSigTimeoutMsg_HU_High_X451" SG_ 579 HvBattPackVolStatus 0;
BA_ "GenSigTimeoutMsg_HU_Mid_X451" SG_ 579 HvBattPackVolStatus 0;
BA_ "GenSigTimeoutTime_HU_A" SG_ 579 HvBattPackVolStatus 0;
BA_ "GenSigTimeoutTime_HU_B" SG_ 579 HvBattPackVolStatus 0;
BA_ "GenSigTimeoutTime_HU_High_X451" SG_ 579 HvBattPackVolStatus 0;
BA_ "GenSigTimeoutTime_HU_Mid_X451" SG_ 579 HvBattPackVolStatus 0;
BA_ "GenSigCycleTime" SG_ 579 HvBattPackVol 100;
BA_ "GenSigCycleTimeActive" SG_ 579 HvBattPackVol 100;
BA_ "GenSigSendType" SG_ 579 HvBattPackVol 7;
BA_ "GenSigTimeoutMsg_HU_A" SG_ 579 HvBattPackVol 0;
BA_ "GenSigTimeoutMsg_HU_B" SG_ 579 HvBattPackVol 0;
BA_ "GenSigTimeoutMsg_HU_High_X451" SG_ 579 HvBattPackVol 0;
BA_ "GenSigTimeoutMsg_HU_Mid_X451" SG_ 579 HvBattPackVol 0;
BA_ "GenSigTimeoutTime_HU_A" SG_ 579 HvBattPackVol 0;
BA_ "GenSigTimeoutTime_HU_B" SG_ 579 HvBattPackVol 0;
BA_ "GenSigTimeoutTime_HU_High_X451" SG_ 579 HvBattPackVol 0;
BA_ "GenSigTimeoutTime_HU_Mid_X451" SG_ 579 HvBattPackVol 0;
BA_ "GenSigCycleTime" SG_ 579 AvgEnergyConsmption 100;
BA_ "GenSigCycleTimeActive" SG_ 579 AvgEnergyConsmption 100;
BA_ "GenSigSendType" SG_ 579 AvgEnergyConsmption 7;
BA_ "GenSigTimeoutMsg_HU_A" SG_ 579 AvgEnergyConsmption 0;
BA_ "GenSigTimeoutMsg_HU_B" SG_ 579 AvgEnergyConsmption 0;
BA_ "GenSigTimeoutMsg_HU_High_X451" SG_ 579 AvgEnergyConsmption 0;
BA_ "GenSigTimeoutMsg_HU_Mid_X451" SG_ 579 AvgEnergyConsmption 0;
BA_ "GenSigTimeoutTime_HU_A" SG_ 579 AvgEnergyConsmption 0;
BA_ "GenSigTimeoutTime_HU_B" SG_ 579 AvgEnergyConsmption 0;
BA_ "GenSigTimeoutTime_HU_High_X451" SG_ 579 AvgEnergyConsmption 0;
BA_ "GenSigTimeoutTime_HU_Mid_X451" SG_ 579 AvgEnergyConsmption 0;
BA_ "GenSigCycleTime" SG_ 579 AvgEnergyConsmptionStatus 100;
BA_ "GenSigCycleTimeActive" SG_ 579 AvgEnergyConsmptionStatus 100;
BA_ "GenSigSendType" SG_ 579 AvgEnergyConsmptionStatus 7;
BA_ "GenSigTimeoutMsg_HU_A" SG_ 579 AvgEnergyConsmptionStatus 0;
BA_ "GenSigTimeoutMsg_HU_B" SG_ 579 AvgEnergyConsmptionStatus 0;
BA_ "GenSigTimeoutMsg_HU_High_X451" SG_ 579 AvgEnergyConsmptionStatus 0;
BA_ "GenSigTimeoutMsg_HU_Mid_X451" SG_ 579 AvgEnergyConsmptionStatus 0;
BA_ "GenSigTimeoutTime_HU_A" SG_ 579 AvgEnergyConsmptionStatus 0;
BA_ "GenSigTimeoutTime_HU_B" SG_ 579 AvgEnergyConsmptionStatus 0;
BA_ "GenSigTimeoutTime_HU_High_X451" SG_ 579 AvgEnergyConsmptionStatus 0;
BA_ "GenSigTimeoutTime_HU_Mid_X451" SG_ 579 AvgEnergyConsmptionStatus 0;
BA_ "GenSigCycleTime" SG_ 579 MotorHightempStatus 100;
BA_ "GenSigCycleTimeActive" SG_ 579 MotorHightempStatus 100;
BA_ "GenSigSendType" SG_ 579 MotorHightempStatus 7;
BA_ "GenSigTimeoutMsg_HU_A" SG_ 579 MotorHightempStatus 0;
BA_ "GenSigTimeoutMsg_HU_B" SG_ 579 MotorHightempStatus 0;
BA_ "GenSigTimeoutMsg_HU_High_X451" SG_ 579 MotorHightempStatus 0;
BA_ "GenSigTimeoutMsg_HU_Mid_X451" SG_ 579 MotorHightempStatus 0;
BA_ "GenSigTimeoutTime_HU_A" SG_ 579 MotorHightempStatus 0;
BA_ "GenSigTimeoutTime_HU_B" SG_ 579 MotorHightempStatus 0;
BA_ "GenSigTimeoutTime_HU_High_X451" SG_ 579 MotorHightempStatus 0;
BA_ "GenSigTimeoutTime_HU_Mid_X451" SG_ 579 MotorHightempStatus 0;
BA_ "GenSigCycleTime" SG_ 579 MotorHightemp 100;
BA_ "GenSigCycleTimeActive" SG_ 579 MotorHightemp 100;
BA_ "GenSigSendType" SG_ 579 MotorHightemp 7;
BA_ "GenSigTimeoutMsg_HU_A" SG_ 579 MotorHightemp 0;
BA_ "GenSigTimeoutMsg_HU_B" SG_ 579 MotorHightemp 0;
BA_ "GenSigTimeoutMsg_HU_High_X451" SG_ 579 MotorHightemp 0;
BA_ "GenSigTimeoutMsg_HU_Mid_X451" SG_ 579 MotorHightemp 0;
BA_ "GenSigTimeoutTime_HU_A" SG_ 579 MotorHightemp 0;
BA_ "GenSigTimeoutTime_HU_B" SG_ 579 MotorHightemp 0;
BA_ "GenSigTimeoutTime_HU_High_X451" SG_ 579 MotorHightemp 0;
BA_ "GenSigTimeoutTime_HU_Mid_X451" SG_ 579 MotorHightemp 0;
BA_ "GenSigCycleTime" SG_ 579 VcuGearSelectionChangeTxt 100;
BA_ "GenSigCycleTimeActive" SG_ 579 VcuGearSelectionChangeTxt 100;
BA_ "GenSigSendType" SG_ 579 VcuGearSelectionChangeTxt 7;
BA_ "GenSigStartValue" SG_ 579 VcuGearSelectionChangeTxt 1;
BA_ "GenSigTimeoutMsg_HU_A" SG_ 579 VcuGearSelectionChangeTxt 0;
BA_ "GenSigTimeoutMsg_HU_B" SG_ 579 VcuGearSelectionChangeTxt 0;
BA_ "GenSigTimeoutMsg_HU_High_X451" SG_ 579 VcuGearSelectionChangeTxt 0;
BA_ "GenSigTimeoutMsg_HU_Mid_X451" SG_ 579 VcuGearSelectionChangeTxt 0;
BA_ "GenSigTimeoutTime_HU_A" SG_ 579 VcuGearSelectionChangeTxt 0;
BA_ "GenSigTimeoutTime_HU_B" SG_ 579 VcuGearSelectionChangeTxt 0;
BA_ "GenSigTimeoutTime_HU_High_X451" SG_ 579 VcuGearSelectionChangeTxt 0;
BA_ "GenSigTimeoutTime_HU_Mid_X451" SG_ 579 VcuGearSelectionChangeTxt 0;
BA_ "GenSigCycleTime" SG_ 579 ImmoStatusVcu 100;
BA_ "GenSigCycleTimeActive" SG_ 579 ImmoStatusVcu 100;
BA_ "GenSigSendType" SG_ 579 ImmoStatusVcu 7;
BA_ "GenSigTimeoutMsg_HU_A" SG_ 579 ImmoStatusVcu 0;
BA_ "GenSigTimeoutMsg_HU_B" SG_ 579 ImmoStatusVcu 0;
BA_ "GenSigTimeoutMsg_HU_High_X451" SG_ 579 ImmoStatusVcu 0;
BA_ "GenSigTimeoutMsg_HU_Mid_X451" SG_ 579 ImmoStatusVcu 0;
BA_ "GenSigTimeoutTime_HU_A" SG_ 579 ImmoStatusVcu 0;
BA_ "GenSigTimeoutTime_HU_B" SG_ 579 ImmoStatusVcu 0;
BA_ "GenSigTimeoutTime_HU_High_X451" SG_ 579 ImmoStatusVcu 0;
BA_ "GenSigTimeoutTime_HU_Mid_X451" SG_ 579 ImmoStatusVcu 0;
BA_ "GenSigCycleTime" SG_ 579 ClntTempVcuStatus 100;
BA_ "GenSigCycleTimeActive" SG_ 579 ClntTempVcuStatus 100;
BA_ "GenSigSendType" SG_ 579 ClntTempVcuStatus 7;
BA_ "GenSigTimeoutMsg_HU_A" SG_ 579 ClntTempVcuStatus 0;
BA_ "GenSigTimeoutMsg_HU_B" SG_ 579 ClntTempVcuStatus 0;
BA_ "GenSigTimeoutMsg_HU_High_X451" SG_ 579 ClntTempVcuStatus 0;
BA_ "GenSigTimeoutMsg_HU_Mid_X451" SG_ 579 ClntTempVcuStatus 0;
BA_ "GenSigTimeoutTime_HU_A" SG_ 579 ClntTempVcuStatus 0;
BA_ "GenSigTimeoutTime_HU_B" SG_ 579 ClntTempVcuStatus 0;
BA_ "GenSigTimeoutTime_HU_High_X451" SG_ 579 ClntTempVcuStatus 0;
BA_ "GenSigTimeoutTime_HU_Mid_X451" SG_ 579 ClntTempVcuStatus 0;
BA_ "GenSigCycleTime" SG_ 579 ClntTempVcu 100;
BA_ "GenSigCycleTimeActive" SG_ 579 ClntTempVcu 100;
BA_ "GenSigSendType" SG_ 579 ClntTempVcu 7;
BA_ "GenSigStartValue" SG_ 579 ClntTempVcu 10;
BA_ "GenSigTimeoutMsg_HU_A" SG_ 579 ClntTempVcu 0;
BA_ "GenSigTimeoutMsg_HU_B" SG_ 579 ClntTempVcu 0;
BA_ "GenSigTimeoutMsg_HU_High_X451" SG_ 579 ClntTempVcu 0;
BA_ "GenSigTimeoutMsg_HU_Mid_X451" SG_ 579 ClntTempVcu 0;
BA_ "GenSigTimeoutTime_HU_A" SG_ 579 ClntTempVcu 0;
BA_ "GenSigTimeoutTime_HU_B" SG_ 579 ClntTempVcu 0;
BA_ "GenSigTimeoutTime_HU_High_X451" SG_ 579 ClntTempVcu 0;
BA_ "GenSigTimeoutTime_HU_Mid_X451" SG_ 579 ClntTempVcu 0;
BA_ "GenSigCycleTime" SG_ 579 GearForDisplayVcu 100;
BA_ "GenSigCycleTimeActive" SG_ 579 GearForDisplayVcu 100;
BA_ "GenSigSendType" SG_ 579 GearForDisplayVcu 7;
BA_ "GenSigStartValue" SG_ 579 GearForDisplayVcu 3;
BA_ "GenSigTimeoutMsg_HU_A" SG_ 579 GearForDisplayVcu 0;
BA_ "GenSigTimeoutMsg_HU_B" SG_ 579 GearForDisplayVcu 0;
BA_ "GenSigTimeoutMsg_HU_High_X451" SG_ 579 GearForDisplayVcu 0;
BA_ "GenSigTimeoutMsg_HU_Mid_X451" SG_ 579 GearForDisplayVcu 0;
BA_ "GenSigTimeoutTime_HU_A" SG_ 579 GearForDisplayVcu 0;
BA_ "GenSigTimeoutTime_HU_B" SG_ 579 GearForDisplayVcu 0;
BA_ "GenSigTimeoutTime_HU_High_X451" SG_ 579 GearForDisplayVcu 0;
BA_ "GenSigTimeoutTime_HU_Mid_X451" SG_ 579 GearForDisplayVcu 0;
BA_ "GenSigCycleTime" SG_ 579 GearForDisplayVcuStatus 100;
BA_ "GenSigCycleTimeActive" SG_ 579 GearForDisplayVcuStatus 100;
BA_ "GenSigSendType" SG_ 579 GearForDisplayVcuStatus 7;
BA_ "GenSigTimeoutMsg_HU_A" SG_ 579 GearForDisplayVcuStatus 0;
BA_ "GenSigTimeoutMsg_HU_B" SG_ 579 GearForDisplayVcuStatus 0;
BA_ "GenSigTimeoutMsg_HU_High_X451" SG_ 579 GearForDisplayVcuStatus 0;
BA_ "GenSigTimeoutMsg_HU_Mid_X451" SG_ 579 GearForDisplayVcuStatus 0;
BA_ "GenSigTimeoutTime_HU_A" SG_ 579 GearForDisplayVcuStatus 0;
BA_ "GenSigTimeoutTime_HU_B" SG_ 579 GearForDisplayVcuStatus 0;
BA_ "GenSigTimeoutTime_HU_High_X451" SG_ 579 GearForDisplayVcuStatus 0;
BA_ "GenSigTimeoutTime_HU_Mid_X451" SG_ 579 GearForDisplayVcuStatus 0;
BA_ "GenSigCycleTime" SG_ 273 CurrentTorqueToWheelStatus 10;
BA_ "GenSigCycleTimeActive" SG_ 273 CurrentTorqueToWheelStatus 10;
BA_ "GenSigSendType" SG_ 273 CurrentTorqueToWheelStatus 7;
BA_ "GenSigTimeoutMsg_HU_A" SG_ 273 CurrentTorqueToWheelStatus 0;
BA_ "GenSigTimeoutMsg_HU_B" SG_ 273 CurrentTorqueToWheelStatus 0;
BA_ "GenSigTimeoutMsg_HU_High_X451" SG_ 273 CurrentTorqueToWheelStatus 0;
BA_ "GenSigTimeoutMsg_HU_Mid_X451" SG_ 273 CurrentTorqueToWheelStatus 0;
BA_ "GenSigTimeoutTime_HU_A" SG_ 273 CurrentTorqueToWheelStatus 0;
BA_ "GenSigTimeoutTime_HU_B" SG_ 273 CurrentTorqueToWheelStatus 0;
BA_ "GenSigTimeoutTime_HU_High_X451" SG_ 273 CurrentTorqueToWheelStatus 0;
BA_ "GenSigTimeoutTime_HU_Mid_X451" SG_ 273 CurrentTorqueToWheelStatus 0;
BA_ "GenSigCycleTime" SG_ 273 CurrentTorqueToWheel 10;
BA_ "GenSigCycleTimeActive" SG_ 273 CurrentTorqueToWheel 10;
BA_ "GenSigSendType" SG_ 273 CurrentTorqueToWheel 7;
BA_ "GenSigStartValue" SG_ 273 CurrentTorqueToWheel 8192;
BA_ "GenSigTimeoutMsg_HU_A" SG_ 273 CurrentTorqueToWheel 0;
BA_ "GenSigTimeoutMsg_HU_B" SG_ 273 CurrentTorqueToWheel 0;
BA_ "GenSigTimeoutMsg_HU_High_X451" SG_ 273 CurrentTorqueToWheel 0;
BA_ "GenSigTimeoutMsg_HU_Mid_X451" SG_ 273 CurrentTorqueToWheel 0;
BA_ "GenSigTimeoutTime_HU_A" SG_ 273 CurrentTorqueToWheel 0;
BA_ "GenSigTimeoutTime_HU_B" SG_ 273 CurrentTorqueToWheel 0;
BA_ "GenSigTimeoutTime_HU_High_X451" SG_ 273 CurrentTorqueToWheel 0;
BA_ "GenSigTimeoutTime_HU_Mid_X451" SG_ 273 CurrentTorqueToWheel 0;
BA_ "GenSigCycleTime" SG_ 273 AccPedPosnVcuStatus 10;
BA_ "GenSigCycleTimeActive" SG_ 273 AccPedPosnVcuStatus 10;
BA_ "GenSigSendType" SG_ 273 AccPedPosnVcuStatus 7;
BA_ "GenSigTimeoutMsg_HU_A" SG_ 273 AccPedPosnVcuStatus 0;
BA_ "GenSigTimeoutMsg_HU_B" SG_ 273 AccPedPosnVcuStatus 0;
BA_ "GenSigTimeoutMsg_HU_High_X451" SG_ 273 AccPedPosnVcuStatus 0;
BA_ "GenSigTimeoutMsg_HU_Mid_X451" SG_ 273 AccPedPosnVcuStatus 0;
BA_ "GenSigTimeoutTime_HU_A" SG_ 273 AccPedPosnVcuStatus 0;
BA_ "GenSigTimeoutTime_HU_B" SG_ 273 AccPedPosnVcuStatus 0;
BA_ "GenSigTimeoutTime_HU_High_X451" SG_ 273 AccPedPosnVcuStatus 0;
BA_ "GenSigTimeoutTime_HU_Mid_X451" SG_ 273 AccPedPosnVcuStatus 0;
BA_ "GenSigCycleTime" SG_ 273 AccPedPosnVcu 10;
BA_ "GenSigCycleTimeActive" SG_ 273 AccPedPosnVcu 10;
BA_ "GenSigSendType" SG_ 273 AccPedPosnVcu 7;
BA_ "GenSigTimeoutMsg_HU_A" SG_ 273 AccPedPosnVcu 0;
BA_ "GenSigTimeoutMsg_HU_B" SG_ 273 AccPedPosnVcu 0;
BA_ "GenSigTimeoutMsg_HU_High_X451" SG_ 273 AccPedPosnVcu 0;
BA_ "GenSigTimeoutMsg_HU_Mid_X451" SG_ 273 AccPedPosnVcu 0;
BA_ "GenSigTimeoutTime_HU_A" SG_ 273 AccPedPosnVcu 0;
BA_ "GenSigTimeoutTime_HU_B" SG_ 273 AccPedPosnVcu 0;
BA_ "GenSigTimeoutTime_HU_High_X451" SG_ 273 AccPedPosnVcu 0;
BA_ "GenSigTimeoutTime_HU_Mid_X451" SG_ 273 AccPedPosnVcu 0;
BA_ "GenSigCycleTime" SG_ 273 BrkPressStateVcu 10;
BA_ "GenSigCycleTimeActive" SG_ 273 BrkPressStateVcu 10;
BA_ "GenSigSendType" SG_ 273 BrkPressStateVcu 7;
BA_ "GenSigStartValue" SG_ 273 BrkPressStateVcu 1;
BA_ "GenSigTimeoutMsg_HU_A" SG_ 273 BrkPressStateVcu 0;
BA_ "GenSigTimeoutMsg_HU_B" SG_ 273 BrkPressStateVcu 0;
BA_ "GenSigTimeoutMsg_HU_High_X451" SG_ 273 BrkPressStateVcu 0;
BA_ "GenSigTimeoutMsg_HU_Mid_X451" SG_ 273 BrkPressStateVcu 0;
BA_ "GenSigTimeoutTime_HU_A" SG_ 273 BrkPressStateVcu 0;
BA_ "GenSigTimeoutTime_HU_B" SG_ 273 BrkPressStateVcu 0;
BA_ "GenSigTimeoutTime_HU_High_X451" SG_ 273 BrkPressStateVcu 0;
BA_ "GenSigTimeoutTime_HU_Mid_X451" SG_ 273 BrkPressStateVcu 0;
BA_ "GenSigCycleTime" SG_ 273 BrkPressStatusVcu 10;
BA_ "GenSigCycleTimeActive" SG_ 273 BrkPressStatusVcu 10;
BA_ "GenSigSendType" SG_ 273 BrkPressStatusVcu 7;
BA_ "GenSigTimeoutMsg_HU_A" SG_ 273 BrkPressStatusVcu 0;
BA_ "GenSigTimeoutMsg_HU_B" SG_ 273 BrkPressStatusVcu 0;
BA_ "GenSigTimeoutMsg_HU_High_X451" SG_ 273 BrkPressStatusVcu 0;
BA_ "GenSigTimeoutMsg_HU_Mid_X451" SG_ 273 BrkPressStatusVcu 0;
BA_ "GenSigTimeoutTime_HU_A" SG_ 273 BrkPressStatusVcu 0;
BA_ "GenSigTimeoutTime_HU_B" SG_ 273 BrkPressStatusVcu 0;
BA_ "GenSigTimeoutTime_HU_High_X451" SG_ 273 BrkPressStatusVcu 0;
BA_ "GenSigTimeoutTime_HU_Mid_X451" SG_ 273 BrkPressStatusVcu 0;
BA_ "GenSigSendType" SG_ 257 PEPSAuthMsg 1;
BA_ "GenSigTimeoutMsg_HU_A" SG_ 257 PEPSAuthMsg 0;
BA_ "GenSigTimeoutMsg_HU_B" SG_ 257 PEPSAuthMsg 0;
BA_ "GenSigTimeoutTime_HU_A" SG_ 257 PEPSAuthMsg 0;
BA_ "GenSigTimeoutTime_HU_B" SG_ 257 PEPSAuthMsg 0;
BA_ "GenSigCycleTime" SG_ 259 CrashoutputSignal 100;
BA_ "GenSigCycleTimeActive" SG_ 259 CrashoutputSignal 100;
BA_ "GenSigSendType" SG_ 259 CrashoutputSignal 2;
BA_ "GenSigCycleTime" SG_ 262 BrkPressStatus 10;
BA_ "GenSigCycleTimeActive" SG_ 262 BrkPressStatus 10;
BA_ "GenSigSendType" SG_ 262 BrkPressStatus 7;
BA_ "GenSigCycleTime" SG_ 262 BrkPressState 10;
BA_ "GenSigCycleTimeActive" SG_ 262 BrkPressState 10;
BA_ "GenSigSendType" SG_ 262 BrkPressState 7;
BA_ "GenSigCycleTime" SG_ 262 EngSpd 10;
BA_ "GenSigCycleTimeActive" SG_ 262 EngSpd 10;
BA_ "GenSigSendType" SG_ 262 EngSpd 7;
BA_ "GenSigCycleTime" SG_ 262 EngSpdStatus 10;
BA_ "GenSigCycleTimeActive" SG_ 262 EngSpdStatus 10;
BA_ "GenSigSendType" SG_ 262 EngSpdStatus 7;
BA_ "GenSigCycleTime" SG_ 262 AccPedRoc 10;
BA_ "GenSigCycleTimeActive" SG_ 262 AccPedRoc 10;
BA_ "GenSigSendType" SG_ 262 AccPedRoc 7;
BA_ "GenSigStartValue" SG_ 262 AccPedRoc 125;
BA_ "GenSigCycleTime" SG_ 262 AccPedPosn 10;
BA_ "GenSigCycleTimeActive" SG_ 262 AccPedPosn 10;
BA_ "GenSigSendType" SG_ 262 AccPedPosn 7;
BA_ "GenSigCycleTime" SG_ 262 EngIdleSpd 10;
BA_ "GenSigCycleTimeActive" SG_ 262 EngIdleSpd 10;
BA_ "GenSigSendType" SG_ 262 EngIdleSpd 7;
BA_ "GenSigCycleTime" SG_ 262 AccPedRocStatus 10;
BA_ "GenSigCycleTimeActive" SG_ 262 AccPedRocStatus 10;
BA_ "GenSigSendType" SG_ 262 AccPedRocStatus 7;
BA_ "GenSigCycleTime" SG_ 262 EngIdleSpdStatus 10;
BA_ "GenSigCycleTimeActive" SG_ 262 EngIdleSpdStatus 10;
BA_ "GenSigSendType" SG_ 262 EngIdleSpdStatus 7;
BA_ "GenSigCycleTime" SG_ 262 AccPedPosnStatus 10;
BA_ "GenSigCycleTimeActive" SG_ 262 AccPedPosnStatus 10;
BA_ "GenSigSendType" SG_ 262 AccPedPosnStatus 7;
BA_ "GenSigCycleTime" SG_ 262 EngSpdMsgRollCnt 10;
BA_ "GenSigCycleTimeActive" SG_ 262 EngSpdMsgRollCnt 10;
BA_ "GenSigSendType" SG_ 262 EngSpdMsgRollCnt 7;
BA_ "GenSigTimeoutMsg_HU_A" SG_ 262 EngSpdMsgRollCnt 0;
BA_ "GenSigTimeoutMsg_HU_B" SG_ 262 EngSpdMsgRollCnt 0;
BA_ "GenSigTimeoutTime_HU_A" SG_ 262 EngSpdMsgRollCnt 0;
BA_ "GenSigTimeoutTime_HU_B" SG_ 262 EngSpdMsgRollCnt 0;
BA_ "GenSigCycleTime" SG_ 262 EngSpdMsgCRC 10;
BA_ "GenSigCycleTimeActive" SG_ 262 EngSpdMsgCRC 10;
BA_ "GenSigSendType" SG_ 262 EngSpdMsgCRC 7;
BA_ "GenSigTimeoutMsg_HU_A" SG_ 262 EngSpdMsgCRC 0;
BA_ "GenSigTimeoutMsg_HU_B" SG_ 262 EngSpdMsgCRC 0;
BA_ "GenSigTimeoutTime_HU_A" SG_ 262 EngSpdMsgCRC 0;
BA_ "GenSigTimeoutTime_HU_B" SG_ 262 EngSpdMsgCRC 0;
BA_ "GenSigCycleTime" SG_ 370 ABsActive 20;
BA_ "GenSigCycleTimeActive" SG_ 370 ABsActive 20;
BA_ "GenSigSendType" SG_ 370 ABsActive 7;
BA_ "GenSigCycleTime" SG_ 370 EBdStatus 20;
BA_ "GenSigCycleTimeActive" SG_ 370 EBdStatus 20;
BA_ "GenSigSendType" SG_ 370 EBdStatus 7;
BA_ "GenSigCycleTime" SG_ 370 EBdActive 20;
BA_ "GenSigCycleTimeActive" SG_ 370 EBdActive 20;
BA_ "GenSigSendType" SG_ 370 EBdActive 7;
BA_ "GenSigCycleTime" SG_ 370 ABsStatus 20;
BA_ "GenSigCycleTimeActive" SG_ 370 ABsStatus 20;
BA_ "GenSigSendType" SG_ 370 ABsStatus 7;
BA_ "GenSigCycleTime" SG_ 374 ODoABS 20;
BA_ "GenSigCycleTimeActive" SG_ 374 ODoABS 20;
BA_ "GenSigSendType" SG_ 374 ODoABS 7;
BA_ "GenSigTimeoutMsg_HU_A" SG_ 374 ODoABS 0;
BA_ "GenSigTimeoutMsg_HU_B" SG_ 374 ODoABS 0;
BA_ "GenSigTimeoutTime_HU_A" SG_ 374 ODoABS 0;
BA_ "GenSigTimeoutTime_HU_B" SG_ 374 ODoABS 0;
BA_ "GenSigCycleTime" SG_ 374 ODoABsStatus 20;
BA_ "GenSigCycleTimeActive" SG_ 374 ODoABsStatus 20;
BA_ "GenSigSendType" SG_ 374 ODoABsStatus 7;
BA_ "GenSigTimeoutMsg_HU_A" SG_ 374 ODoABsStatus 0;
BA_ "GenSigTimeoutMsg_HU_B" SG_ 374 ODoABsStatus 0;
BA_ "GenSigTimeoutTime_HU_A" SG_ 374 ODoABsStatus 0;
BA_ "GenSigTimeoutTime_HU_B" SG_ 374 ODoABsStatus 0;
BA_ "GenSigCycleTime" SG_ 374 VehSpdABS 20;
BA_ "GenSigCycleTimeActive" SG_ 374 VehSpdABS 20;
BA_ "GenSigSendType" SG_ 374 VehSpdABS 7;
BA_ "GenSigTimeoutMsg_HU_A" SG_ 374 VehSpdABS 0;
BA_ "GenSigTimeoutMsg_HU_B" SG_ 374 VehSpdABS 0;
BA_ "GenSigTimeoutTime_HU_A" SG_ 374 VehSpdABS 0;
BA_ "GenSigTimeoutTime_HU_B" SG_ 374 VehSpdABS 0;
BA_ "GenSigCycleTime" SG_ 374 VehSpdABsStatus 20;
BA_ "GenSigCycleTimeActive" SG_ 374 VehSpdABsStatus 20;
BA_ "GenSigSendType" SG_ 374 VehSpdABsStatus 7;
BA_ "GenSigTimeoutMsg_HU_A" SG_ 374 VehSpdABsStatus 0;
BA_ "GenSigTimeoutMsg_HU_B" SG_ 374 VehSpdABsStatus 0;
BA_ "GenSigTimeoutTime_HU_A" SG_ 374 VehSpdABsStatus 0;
BA_ "GenSigTimeoutTime_HU_B" SG_ 374 VehSpdABsStatus 0;
BA_ "GenSigCycleTime" SG_ 646 UserSpdLim 100;
BA_ "GenSigCycleTimeActive" SG_ 646 UserSpdLim 100;
BA_ "GenSigSendType" SG_ 646 UserSpdLim 7;
BA_ "GenSigCycleTime" SG_ 646 UserSpdLimLamp 100;
BA_ "GenSigCycleTimeActive" SG_ 646 UserSpdLimLamp 100;
BA_ "GenSigSendType" SG_ 646 UserSpdLimLamp 7;
BA_ "GenSigTimeoutMsg_HU_A" SG_ 646 UserSpdLimLamp 0;
BA_ "GenSigTimeoutMsg_HU_B" SG_ 646 UserSpdLimLamp 0;
BA_ "GenSigTimeoutTime_HU_A" SG_ 646 UserSpdLimLamp 0;
BA_ "GenSigTimeoutTime_HU_B" SG_ 646 UserSpdLimLamp 0;
BA_ "GenSigCycleTime" SG_ 646 UserSpdLimFault 100;
BA_ "GenSigCycleTimeActive" SG_ 646 UserSpdLimFault 100;
BA_ "GenSigSendType" SG_ 646 UserSpdLimFault 7;
BA_ "GenSigTimeoutMsg_HU_A" SG_ 646 UserSpdLimFault 0;
BA_ "GenSigTimeoutMsg_HU_B" SG_ 646 UserSpdLimFault 0;
BA_ "GenSigTimeoutTime_HU_A" SG_ 646 UserSpdLimFault 0;
BA_ "GenSigTimeoutTime_HU_B" SG_ 646 UserSpdLimFault 0;
BA_ "GenSigCycleTime" SG_ 646 UserSpdLimStatus 100;
BA_ "GenSigCycleTimeActive" SG_ 646 UserSpdLimStatus 100;
BA_ "GenSigSendType" SG_ 646 UserSpdLimStatus 7;
BA_ "GenSigCycleTime" SG_ 646 EngStatus 100;
BA_ "GenSigCycleTimeActive" SG_ 646 EngStatus 100;
BA_ "GenSigSendType" SG_ 646 EngStatus 7;
BA_ "GenSigCycleTime" SG_ 646 CeLampState 100;
BA_ "GenSigCycleTimeActive" SG_ 646 CeLampState 100;
BA_ "GenSigSendType" SG_ 646 CeLampState 7;
BA_ "GenSigCycleTime" SG_ 646 StaterProhibitionDelay 100;
BA_ "GenSigCycleTimeActive" SG_ 646 StaterProhibitionDelay 100;
BA_ "GenSigSendType" SG_ 646 StaterProhibitionDelay 7;
BA_ "GenSigTimeoutMsg_HU_A" SG_ 646 StaterProhibitionDelay 0;
BA_ "GenSigTimeoutMsg_HU_B" SG_ 646 StaterProhibitionDelay 0;
BA_ "GenSigTimeoutTime_HU_A" SG_ 646 StaterProhibitionDelay 0;
BA_ "GenSigTimeoutTime_HU_B" SG_ 646 StaterProhibitionDelay 0;
BA_ "GenSigCycleTime" SG_ 646 StarterControlState 100;
BA_ "GenSigCycleTimeActive" SG_ 646 StarterControlState 100;
BA_ "GenSigSendType" SG_ 646 StarterControlState 7;
BA_ "GenSigStartValue" SG_ 646 StarterControlState 1;
BA_ "GenSigTimeoutMsg_HU_A" SG_ 646 StarterControlState 0;
BA_ "GenSigTimeoutMsg_HU_B" SG_ 646 StarterControlState 0;
BA_ "GenSigTimeoutTime_HU_A" SG_ 646 StarterControlState 0;
BA_ "GenSigTimeoutTime_HU_B" SG_ 646 StarterControlState 0;
BA_ "GenSigCycleTime" SG_ 646 UserSpdLimState 100;
BA_ "GenSigCycleTimeActive" SG_ 646 UserSpdLimState 100;
BA_ "GenSigSendType" SG_ 646 UserSpdLimState 7;
BA_ "GenSigTimeoutMsg_HU_A" SG_ 646 UserSpdLimState 0;
BA_ "GenSigTimeoutMsg_HU_B" SG_ 646 UserSpdLimState 0;
BA_ "GenSigTimeoutTime_HU_A" SG_ 646 UserSpdLimState 0;
BA_ "GenSigTimeoutTime_HU_B" SG_ 646 UserSpdLimState 0;
BA_ "GenSigCycleTime" SG_ 646 SFCActiveEMS 100;
BA_ "GenSigCycleTimeActive" SG_ 646 SFCActiveEMS 100;
BA_ "GenSigSendType" SG_ 646 SFCActiveEMS 7;
BA_ "GenSigTimeoutMsg_HU_A" SG_ 646 SFCActiveEMS 0;
BA_ "GenSigTimeoutMsg_HU_B" SG_ 646 SFCActiveEMS 0;
BA_ "GenSigTimeoutTime_HU_A" SG_ 646 SFCActiveEMS 0;
BA_ "GenSigTimeoutTime_HU_B" SG_ 646 SFCActiveEMS 0;
BA_ "GenSigCycleTime" SG_ 646 DrvModeIndctnEMSstatus 100;
BA_ "GenSigCycleTimeActive" SG_ 646 DrvModeIndctnEMSstatus 100;
BA_ "GenSigSendType" SG_ 646 DrvModeIndctnEMSstatus 7;
BA_ "GenSigCycleTime" SG_ 646 CruiseSpdLamp 100;
BA_ "GenSigCycleTimeActive" SG_ 646 CruiseSpdLamp 100;
BA_ "GenSigSendType" SG_ 646 CruiseSpdLamp 7;
BA_ "GenSigTimeoutMsg_HU_A" SG_ 646 CruiseSpdLamp 0;
BA_ "GenSigTimeoutMsg_HU_B" SG_ 646 CruiseSpdLamp 0;
BA_ "GenSigTimeoutTime_HU_A" SG_ 646 CruiseSpdLamp 0;
BA_ "GenSigTimeoutTime_HU_B" SG_ 646 CruiseSpdLamp 0;
BA_ "GenSigCycleTime" SG_ 646 StartercControlStatus 100;
BA_ "GenSigCycleTimeActive" SG_ 646 StartercControlStatus 100;
BA_ "GenSigSendType" SG_ 646 StartercControlStatus 7;
BA_ "GenSigTimeoutMsg_HU_A" SG_ 646 StartercControlStatus 0;
BA_ "GenSigTimeoutMsg_HU_B" SG_ 646 StartercControlStatus 0;
BA_ "GenSigTimeoutTime_HU_A" SG_ 646 StartercControlStatus 0;
BA_ "GenSigTimeoutTime_HU_B" SG_ 646 StartercControlStatus 0;
BA_ "GenSigCycleTime" SG_ 646 CurrGearEms 100;
BA_ "GenSigCycleTimeActive" SG_ 646 CurrGearEms 100;
BA_ "GenSigSendType" SG_ 646 CurrGearEms 7;
BA_ "GenSigCycleTime" SG_ 646 CruiseSpdFault 100;
BA_ "GenSigCycleTimeActive" SG_ 646 CruiseSpdFault 100;
BA_ "GenSigSendType" SG_ 646 CruiseSpdFault 7;
BA_ "GenSigTimeoutMsg_HU_A" SG_ 646 CruiseSpdFault 0;
BA_ "GenSigTimeoutMsg_HU_B" SG_ 646 CruiseSpdFault 0;
BA_ "GenSigTimeoutTime_HU_A" SG_ 646 CruiseSpdFault 0;
BA_ "GenSigTimeoutTime_HU_B" SG_ 646 CruiseSpdFault 0;
BA_ "GenSigCycleTime" SG_ 646 CruiseSpdStatus 100;
BA_ "GenSigCycleTimeActive" SG_ 646 CruiseSpdStatus 100;
BA_ "GenSigSendType" SG_ 646 CruiseSpdStatus 7;
BA_ "GenSigTimeoutMsg_HU_A" SG_ 646 CruiseSpdStatus 0;
BA_ "GenSigTimeoutMsg_HU_B" SG_ 646 CruiseSpdStatus 0;
BA_ "GenSigTimeoutTime_HU_A" SG_ 646 CruiseSpdStatus 0;
BA_ "GenSigTimeoutTime_HU_B" SG_ 646 CruiseSpdStatus 0;
BA_ "GenSigCycleTime" SG_ 646 CruiseSpd 100;
BA_ "GenSigCycleTimeActive" SG_ 646 CruiseSpd 100;
BA_ "GenSigSendType" SG_ 646 CruiseSpd 7;
BA_ "GenSigTimeoutMsg_HU_A" SG_ 646 CruiseSpd 0;
BA_ "GenSigTimeoutMsg_HU_B" SG_ 646 CruiseSpd 0;
BA_ "GenSigTimeoutTime_HU_A" SG_ 646 CruiseSpd 0;
BA_ "GenSigTimeoutTime_HU_B" SG_ 646 CruiseSpd 0;
BA_ "GenSigCycleTime" SG_ 646 CurrGearEmsStatus 100;
BA_ "GenSigCycleTimeActive" SG_ 646 CurrGearEmsStatus 100;
BA_ "GenSigSendType" SG_ 646 CurrGearEmsStatus 7;
BA_ "GenSigCycleTime" SG_ 646 GearShiftIndctnEmsStatus 100;
BA_ "GenSigCycleTimeActive" SG_ 646 GearShiftIndctnEmsStatus 100;
BA_ "GenSigSendType" SG_ 646 GearShiftIndctnEmsStatus 7;
BA_ "GenSigCycleTime" SG_ 646 GearShiftIndctnEms 100;
BA_ "GenSigCycleTimeActive" SG_ 646 GearShiftIndctnEms 100;
BA_ "GenSigSendType" SG_ 646 GearShiftIndctnEms 7;
BA_ "GenSigCycleTime" SG_ 646 CruiseSwitchstate 100;
BA_ "GenSigCycleTimeActive" SG_ 646 CruiseSwitchstate 100;
BA_ "GenSigSendType" SG_ 646 CruiseSwitchstate 7;
BA_ "GenSigTimeoutMsg_HU_A" SG_ 646 CruiseSwitchstate 0;
BA_ "GenSigTimeoutMsg_HU_B" SG_ 646 CruiseSwitchstate 0;
BA_ "GenSigTimeoutTime_HU_A" SG_ 646 CruiseSwitchstate 0;
BA_ "GenSigTimeoutTime_HU_B" SG_ 646 CruiseSwitchstate 0;
BA_ "GenSigCycleTime" SG_ 646 CruiseSwitchstateStatus 100;
BA_ "GenSigCycleTimeActive" SG_ 646 CruiseSwitchstateStatus 100;
BA_ "GenSigSendType" SG_ 646 CruiseSwitchstateStatus 7;
BA_ "GenSigTimeoutMsg_HU_A" SG_ 646 CruiseSwitchstateStatus 0;
BA_ "GenSigTimeoutMsg_HU_B" SG_ 646 CruiseSwitchstateStatus 0;
BA_ "GenSigTimeoutTime_HU_A" SG_ 646 CruiseSwitchstateStatus 0;
BA_ "GenSigTimeoutTime_HU_B" SG_ 646 CruiseSwitchstateStatus 0;
BA_ "GenSigCycleTime" SG_ 646 DrvModeIndctnEMS 100;
BA_ "GenSigCycleTimeActive" SG_ 646 DrvModeIndctnEMS 100;
BA_ "GenSigSendType" SG_ 646 DrvModeIndctnEMS 7;
BA_ "GenSigCycleTime" SG_ 697 IcHuResetTripB 100;
BA_ "GenSigCycleTimeActive" SG_ 697 IcHuResetTripB 100;
BA_ "GenSigSendType" SG_ 697 IcHuResetTripB 7;
BA_ "GenSigCycleTime" SG_ 697 IcHuResetTripA 100;
BA_ "GenSigCycleTimeActive" SG_ 697 IcHuResetTripA 100;
BA_ "GenSigSendType" SG_ 697 IcHuResetTripA 7;
BA_ "GenSigCycleTime" SG_ 699 IcHuTripAInfofull 100;
BA_ "GenSigCycleTimeActive" SG_ 699 IcHuTripAInfofull 100;
BA_ "GenSigSendType" SG_ 699 IcHuTripAInfofull 7;
BA_ "GenSigCycleTime" SG_ 699 IcHuTripBInfofull 100;
BA_ "GenSigCycleTimeActive" SG_ 699 IcHuTripBInfofull 100;
BA_ "GenSigSendType" SG_ 699 IcHuTripBInfofull 7;
BA_ "GenSigCycleTime" SG_ 946 DoorStateRearLHStatus 500;
BA_ "GenSigCycleTimeActive" SG_ 946 DoorStateRearLHStatus 500;
BA_ "GenSigSendType" SG_ 946 DoorStateRearLHStatus 7;
BA_ "GenSigTimeoutMsg_HU_A" SG_ 946 DoorStateRearLHStatus 2500;
BA_ "GenSigTimeoutMsg_HU_B" SG_ 946 DoorStateRearLHStatus 2500;
BA_ "GenSigTimeoutMsg_HU_High_X451" SG_ 946 DoorStateRearLHStatus 2500;
BA_ "GenSigTimeoutMsg_HU_Mid_X451" SG_ 946 DoorStateRearLHStatus 2500;
BA_ "GenSigTimeoutTime_HU_A" SG_ 946 DoorStateRearLHStatus 2500;
BA_ "GenSigTimeoutTime_HU_B" SG_ 946 DoorStateRearLHStatus 2500;
BA_ "GenSigTimeoutTime_HU_High_X451" SG_ 946 DoorStateRearLHStatus 2500;
BA_ "GenSigTimeoutTime_HU_Mid_X451" SG_ 946 DoorStateRearLHStatus 2500;
BA_ "GenSigCycleTime" SG_ 946 DoorStatePassStatus 500;
BA_ "GenSigCycleTimeActive" SG_ 946 DoorStatePassStatus 500;
BA_ "GenSigSendType" SG_ 946 DoorStatePassStatus 7;
BA_ "GenSigTimeoutMsg_HU_A" SG_ 946 DoorStatePassStatus 2500;
BA_ "GenSigTimeoutMsg_HU_B" SG_ 946 DoorStatePassStatus 2500;
BA_ "GenSigTimeoutMsg_HU_High_X451" SG_ 946 DoorStatePassStatus 2500;
BA_ "GenSigTimeoutMsg_HU_Mid_X451" SG_ 946 DoorStatePassStatus 2500;
BA_ "GenSigTimeoutTime_HU_A" SG_ 946 DoorStatePassStatus 2500;
BA_ "GenSigTimeoutTime_HU_B" SG_ 946 DoorStatePassStatus 2500;
BA_ "GenSigTimeoutTime_HU_High_X451" SG_ 946 DoorStatePassStatus 2500;
BA_ "GenSigTimeoutTime_HU_Mid_X451" SG_ 946 DoorStatePassStatus 2500;
BA_ "GenSigCycleTime" SG_ 946 DoorStatePass 500;
BA_ "GenSigCycleTimeActive" SG_ 946 DoorStatePass 500;
BA_ "GenSigSendType" SG_ 946 DoorStatePass 7;
BA_ "GenSigTimeoutMsg_HU_A" SG_ 946 DoorStatePass 2500;
BA_ "GenSigTimeoutMsg_HU_B" SG_ 946 DoorStatePass 2500;
BA_ "GenSigTimeoutMsg_HU_High_X451" SG_ 946 DoorStatePass 2500;
BA_ "GenSigTimeoutMsg_HU_Mid_X451" SG_ 946 DoorStatePass 2500;
BA_ "GenSigTimeoutTime_HU_A" SG_ 946 DoorStatePass 2500;
BA_ "GenSigTimeoutTime_HU_B" SG_ 946 DoorStatePass 2500;
BA_ "GenSigTimeoutTime_HU_High_X451" SG_ 946 DoorStatePass 2500;
BA_ "GenSigTimeoutTime_HU_Mid_X451" SG_ 946 DoorStatePass 2500;
BA_ "GenSigCycleTime" SG_ 946 DoorStateDrvrStatus 500;
BA_ "GenSigCycleTimeActive" SG_ 946 DoorStateDrvrStatus 500;
BA_ "GenSigSendType" SG_ 946 DoorStateDrvrStatus 7;
BA_ "GenSigTimeoutMsg_HU_A" SG_ 946 DoorStateDrvrStatus 2500;
BA_ "GenSigTimeoutMsg_HU_B" SG_ 946 DoorStateDrvrStatus 2500;
BA_ "GenSigTimeoutMsg_HU_High_X451" SG_ 946 DoorStateDrvrStatus 2500;
BA_ "GenSigTimeoutMsg_HU_Mid_X451" SG_ 946 DoorStateDrvrStatus 2500;
BA_ "GenSigTimeoutTime_HU_A" SG_ 946 DoorStateDrvrStatus 2500;
BA_ "GenSigTimeoutTime_HU_B" SG_ 946 DoorStateDrvrStatus 2500;
BA_ "GenSigTimeoutTime_HU_High_X451" SG_ 946 DoorStateDrvrStatus 2500;
BA_ "GenSigTimeoutTime_HU_Mid_X451" SG_ 946 DoorStateDrvrStatus 2500;
BA_ "GenSigCycleTime" SG_ 946 DoorStateDrvr 500;
BA_ "GenSigCycleTimeActive" SG_ 946 DoorStateDrvr 500;
BA_ "GenSigSendType" SG_ 946 DoorStateDrvr 7;
BA_ "GenSigTimeoutMsg_HU_A" SG_ 946 DoorStateDrvr 2500;
BA_ "GenSigTimeoutMsg_HU_B" SG_ 946 DoorStateDrvr 2500;
BA_ "GenSigTimeoutMsg_HU_High_X451" SG_ 946 DoorStateDrvr 2500;
BA_ "GenSigTimeoutMsg_HU_Mid_X451" SG_ 946 DoorStateDrvr 2500;
BA_ "GenSigTimeoutTime_HU_A" SG_ 946 DoorStateDrvr 2500;
BA_ "GenSigTimeoutTime_HU_B" SG_ 946 DoorStateDrvr 2500;
BA_ "GenSigTimeoutTime_HU_High_X451" SG_ 946 DoorStateDrvr 2500;
BA_ "GenSigTimeoutTime_HU_Mid_X451" SG_ 946 DoorStateDrvr 2500;
BA_ "GenSigCycleTime" SG_ 946 DoorStateRearRH 500;
BA_ "GenSigCycleTimeActive" SG_ 946 DoorStateRearRH 500;
BA_ "GenSigSendType" SG_ 946 DoorStateRearRH 7;
BA_ "GenSigTimeoutMsg_HU_A" SG_ 946 DoorStateRearRH 2500;
BA_ "GenSigTimeoutMsg_HU_B" SG_ 946 DoorStateRearRH 2500;
BA_ "GenSigTimeoutMsg_HU_High_X451" SG_ 946 DoorStateRearRH 2500;
BA_ "GenSigTimeoutMsg_HU_Mid_X451" SG_ 946 DoorStateRearRH 2500;
BA_ "GenSigTimeoutTime_HU_A" SG_ 946 DoorStateRearRH 2500;
BA_ "GenSigTimeoutTime_HU_B" SG_ 946 DoorStateRearRH 2500;
BA_ "GenSigTimeoutTime_HU_High_X451" SG_ 946 DoorStateRearRH 2500;
BA_ "GenSigTimeoutTime_HU_Mid_X451" SG_ 946 DoorStateRearRH 2500;
BA_ "GenSigCycleTime" SG_ 946 DoorStateRearRHStatus 500;
BA_ "GenSigCycleTimeActive" SG_ 946 DoorStateRearRHStatus 500;
BA_ "GenSigSendType" SG_ 946 DoorStateRearRHStatus 7;
BA_ "GenSigTimeoutMsg_HU_A" SG_ 946 DoorStateRearRHStatus 2500;
BA_ "GenSigTimeoutMsg_HU_B" SG_ 946 DoorStateRearRHStatus 2500;
BA_ "GenSigTimeoutMsg_HU_High_X451" SG_ 946 DoorStateRearRHStatus 2500;
BA_ "GenSigTimeoutMsg_HU_Mid_X451" SG_ 946 DoorStateRearRHStatus 2500;
BA_ "GenSigTimeoutTime_HU_A" SG_ 946 DoorStateRearRHStatus 2500;
BA_ "GenSigTimeoutTime_HU_B" SG_ 946 DoorStateRearRHStatus 2500;
BA_ "GenSigTimeoutTime_HU_High_X451" SG_ 946 DoorStateRearRHStatus 2500;
BA_ "GenSigTimeoutTime_HU_Mid_X451" SG_ 946 DoorStateRearRHStatus 2500;
BA_ "GenSigCycleTime" SG_ 946 DoorStateRearLH 500;
BA_ "GenSigCycleTimeActive" SG_ 946 DoorStateRearLH 500;
BA_ "GenSigSendType" SG_ 946 DoorStateRearLH 7;
BA_ "GenSigTimeoutMsg_HU_A" SG_ 946 DoorStateRearLH 2500;
BA_ "GenSigTimeoutMsg_HU_B" SG_ 946 DoorStateRearLH 2500;
BA_ "GenSigTimeoutMsg_HU_High_X451" SG_ 946 DoorStateRearLH 2500;
BA_ "GenSigTimeoutMsg_HU_Mid_X451" SG_ 946 DoorStateRearLH 2500;
BA_ "GenSigTimeoutTime_HU_A" SG_ 946 DoorStateRearLH 2500;
BA_ "GenSigTimeoutTime_HU_B" SG_ 946 DoorStateRearLH 2500;
BA_ "GenSigTimeoutTime_HU_High_X451" SG_ 946 DoorStateRearLH 2500;
BA_ "GenSigTimeoutTime_HU_Mid_X451" SG_ 946 DoorStateRearLH 2500;
BA_ "GenSigCycleTime" SG_ 946 TailgateState 500;
BA_ "GenSigCycleTimeActive" SG_ 946 TailgateState 500;
BA_ "GenSigSendType" SG_ 946 TailgateState 7;
BA_ "GenSigTimeoutMsg_HU_A" SG_ 946 TailgateState 2500;
BA_ "GenSigTimeoutMsg_HU_B" SG_ 946 TailgateState 2500;
BA_ "GenSigTimeoutMsg_HU_High_X451" SG_ 946 TailgateState 2500;
BA_ "GenSigTimeoutMsg_HU_Mid_X451" SG_ 946 TailgateState 2500;
BA_ "GenSigTimeoutTime_HU_A" SG_ 946 TailgateState 2500;
BA_ "GenSigTimeoutTime_HU_B" SG_ 946 TailgateState 2500;
BA_ "GenSigTimeoutTime_HU_High_X451" SG_ 946 TailgateState 2500;
BA_ "GenSigTimeoutTime_HU_Mid_X451" SG_ 946 TailgateState 2500;
BA_ "GenSigCycleTime" SG_ 946 TailgateStateStatus 500;
BA_ "GenSigCycleTimeActive" SG_ 946 TailgateStateStatus 500;
BA_ "GenSigSendType" SG_ 946 TailgateStateStatus 7;
BA_ "GenSigTimeoutMsg_HU_A" SG_ 946 TailgateStateStatus 2500;
BA_ "GenSigTimeoutMsg_HU_B" SG_ 946 TailgateStateStatus 2500;
BA_ "GenSigTimeoutMsg_HU_High_X451" SG_ 946 TailgateStateStatus 2500;
BA_ "GenSigTimeoutMsg_HU_Mid_X451" SG_ 946 TailgateStateStatus 2500;
BA_ "GenSigTimeoutTime_HU_A" SG_ 946 TailgateStateStatus 2500;
BA_ "GenSigTimeoutTime_HU_B" SG_ 946 TailgateStateStatus 2500;
BA_ "GenSigTimeoutTime_HU_High_X451" SG_ 946 TailgateStateStatus 2500;
BA_ "GenSigTimeoutTime_HU_Mid_X451" SG_ 946 TailgateStateStatus 2500;
BA_ "GenSigCycleTime" SG_ 946 LowBeamMalFn 500;
BA_ "GenSigCycleTimeActive" SG_ 946 LowBeamMalFn 500;
BA_ "GenSigSendType" SG_ 946 LowBeamMalFn 7;
BA_ "GenSigTimeoutMsg_HU_A" SG_ 946 LowBeamMalFn 2500;
BA_ "GenSigTimeoutMsg_HU_B" SG_ 946 LowBeamMalFn 2500;
BA_ "GenSigTimeoutMsg_HU_High_X451" SG_ 946 LowBeamMalFn 2500;
BA_ "GenSigTimeoutMsg_HU_Mid_X451" SG_ 946 LowBeamMalFn 2500;
BA_ "GenSigTimeoutTime_HU_A" SG_ 946 LowBeamMalFn 2500;
BA_ "GenSigTimeoutTime_HU_B" SG_ 946 LowBeamMalFn 2500;
BA_ "GenSigTimeoutTime_HU_High_X451" SG_ 946 LowBeamMalFn 2500;
BA_ "GenSigTimeoutTime_HU_Mid_X451" SG_ 946 LowBeamMalFn 2500;
BA_ "GenSigCycleTime" SG_ 946 HighBeamTelltale 500;
BA_ "GenSigCycleTimeActive" SG_ 946 HighBeamTelltale 500;
BA_ "GenSigSendType" SG_ 946 HighBeamTelltale 7;
BA_ "GenSigTimeoutMsg_HU_A" SG_ 946 HighBeamTelltale 2500;
BA_ "GenSigTimeoutMsg_HU_B" SG_ 946 HighBeamTelltale 2500;
BA_ "GenSigTimeoutMsg_HU_High_X451" SG_ 946 HighBeamTelltale 2500;
BA_ "GenSigTimeoutMsg_HU_Mid_X451" SG_ 946 HighBeamTelltale 2500;
BA_ "GenSigTimeoutTime_HU_A" SG_ 946 HighBeamTelltale 2500;
BA_ "GenSigTimeoutTime_HU_B" SG_ 946 HighBeamTelltale 2500;
BA_ "GenSigTimeoutTime_HU_High_X451" SG_ 946 HighBeamTelltale 2500;
BA_ "GenSigTimeoutTime_HU_Mid_X451" SG_ 946 HighBeamTelltale 2500;
BA_ "GenSigCycleTime" SG_ 946 HighBeamTelltaleStatus 500;
BA_ "GenSigCycleTimeActive" SG_ 946 HighBeamTelltaleStatus 500;
BA_ "GenSigSendType" SG_ 946 HighBeamTelltaleStatus 7;
BA_ "GenSigTimeoutMsg_HU_A" SG_ 946 HighBeamTelltaleStatus 2500;
BA_ "GenSigTimeoutMsg_HU_B" SG_ 946 HighBeamTelltaleStatus 2500;
BA_ "GenSigTimeoutMsg_HU_High_X451" SG_ 946 HighBeamTelltaleStatus 2500;
BA_ "GenSigTimeoutMsg_HU_Mid_X451" SG_ 946 HighBeamTelltaleStatus 2500;
BA_ "GenSigTimeoutTime_HU_A" SG_ 946 HighBeamTelltaleStatus 2500;
BA_ "GenSigTimeoutTime_HU_B" SG_ 946 HighBeamTelltaleStatus 2500;
BA_ "GenSigTimeoutTime_HU_High_X451" SG_ 946 HighBeamTelltaleStatus 2500;
BA_ "GenSigTimeoutTime_HU_Mid_X451" SG_ 946 HighBeamTelltaleStatus 2500;
BA_ "GenSigCycleTime" SG_ 946 DRLTelltale 500;
BA_ "GenSigCycleTimeActive" SG_ 946 DRLTelltale 500;
BA_ "GenSigSendType" SG_ 946 DRLTelltale 7;
BA_ "GenSigTimeoutMsg_HU_A" SG_ 946 DRLTelltale 2500;
BA_ "GenSigTimeoutMsg_HU_B" SG_ 946 DRLTelltale 2500;
BA_ "GenSigTimeoutMsg_HU_High_X451" SG_ 946 DRLTelltale 2500;
BA_ "GenSigTimeoutMsg_HU_Mid_X451" SG_ 946 DRLTelltale 2500;
BA_ "GenSigTimeoutTime_HU_A" SG_ 946 DRLTelltale 2500;
BA_ "GenSigTimeoutTime_HU_B" SG_ 946 DRLTelltale 2500;
BA_ "GenSigTimeoutTime_HU_High_X451" SG_ 946 DRLTelltale 2500;
BA_ "GenSigTimeoutTime_HU_Mid_X451" SG_ 946 DRLTelltale 2500;
BA_ "GenSigCycleTime" SG_ 946 DRLTelltaleStatus 500;
BA_ "GenSigCycleTimeActive" SG_ 946 DRLTelltaleStatus 500;
BA_ "GenSigSendType" SG_ 946 DRLTelltaleStatus 7;
BA_ "GenSigTimeoutMsg_HU_A" SG_ 946 DRLTelltaleStatus 2500;
BA_ "GenSigTimeoutMsg_HU_B" SG_ 946 DRLTelltaleStatus 2500;
BA_ "GenSigTimeoutMsg_HU_High_X451" SG_ 946 DRLTelltaleStatus 2500;
BA_ "GenSigTimeoutMsg_HU_Mid_X451" SG_ 946 DRLTelltaleStatus 2500;
BA_ "GenSigTimeoutTime_HU_A" SG_ 946 DRLTelltaleStatus 2500;
BA_ "GenSigTimeoutTime_HU_B" SG_ 946 DRLTelltaleStatus 2500;
BA_ "GenSigTimeoutTime_HU_High_X451" SG_ 946 DRLTelltaleStatus 2500;
BA_ "GenSigTimeoutTime_HU_Mid_X451" SG_ 946 DRLTelltaleStatus 2500;
BA_ "GenSigCycleTime" SG_ 946 LowBeamMalFnStatus 500;
BA_ "GenSigCycleTimeActive" SG_ 946 LowBeamMalFnStatus 500;
BA_ "GenSigSendType" SG_ 946 LowBeamMalFnStatus 7;
BA_ "GenSigTimeoutMsg_HU_A" SG_ 946 LowBeamMalFnStatus 2500;
BA_ "GenSigTimeoutMsg_HU_B" SG_ 946 LowBeamMalFnStatus 2500;
BA_ "GenSigTimeoutMsg_HU_High_X451" SG_ 946 LowBeamMalFnStatus 2500;
BA_ "GenSigTimeoutMsg_HU_Mid_X451" SG_ 946 LowBeamMalFnStatus 2500;
BA_ "GenSigTimeoutTime_HU_A" SG_ 946 LowBeamMalFnStatus 2500;
BA_ "GenSigTimeoutTime_HU_B" SG_ 946 LowBeamMalFnStatus 2500;
BA_ "GenSigTimeoutTime_HU_High_X451" SG_ 946 LowBeamMalFnStatus 2500;
BA_ "GenSigTimeoutTime_HU_Mid_X451" SG_ 946 LowBeamMalFnStatus 2500;
BA_ "GenSigCycleTime" SG_ 946 BonnetState 500;
BA_ "GenSigCycleTimeActive" SG_ 946 BonnetState 500;
BA_ "GenSigSendType" SG_ 946 BonnetState 7;
BA_ "GenSigTimeoutMsg_HU_A" SG_ 946 BonnetState 0;
BA_ "GenSigTimeoutMsg_HU_B" SG_ 946 BonnetState 0;
BA_ "GenSigTimeoutTime_HU_A" SG_ 946 BonnetState 0;
BA_ "GenSigTimeoutTime_HU_B" SG_ 946 BonnetState 0;
BA_ "GenSigCycleTime" SG_ 946 BonnetStateStatus 500;
BA_ "GenSigCycleTimeActive" SG_ 946 BonnetStateStatus 500;
BA_ "GenSigSendType" SG_ 946 BonnetStateStatus 7;
BA_ "GenSigTimeoutMsg_HU_A" SG_ 946 BonnetStateStatus 0;
BA_ "GenSigTimeoutMsg_HU_B" SG_ 946 BonnetStateStatus 0;
BA_ "GenSigTimeoutTime_HU_A" SG_ 946 BonnetStateStatus 0;
BA_ "GenSigTimeoutTime_HU_B" SG_ 946 BonnetStateStatus 0;
BA_ "GenSigCycleTime" SG_ 948 OdoICFullSigPeriodic 500;
BA_ "GenSigCycleTimeActive" SG_ 948 OdoICFullSigPeriodic 500;
BA_ "GenSigSendType" SG_ 948 OdoICFullSigPeriodic 7;
BA_ "GenSigTimeoutMsg_HU_A" SG_ 948 OdoICFullSigPeriodic 0;
BA_ "GenSigTimeoutMsg_HU_B" SG_ 948 OdoICFullSigPeriodic 0;
BA_ "GenSigTimeoutTime_HU_A" SG_ 948 OdoICFullSigPeriodic 0;
BA_ "GenSigTimeoutTime_HU_B" SG_ 948 OdoICFullSigPeriodic 0;
BA_ "GenSigCycleTime" SG_ 948 OdoICFullSigPeriodicStatus 500;
BA_ "GenSigCycleTimeActive" SG_ 948 OdoICFullSigPeriodicStatus 500;
BA_ "GenSigSendType" SG_ 948 OdoICFullSigPeriodicStatus 7;
BA_ "GenSigTimeoutMsg_HU_A" SG_ 948 OdoICFullSigPeriodicStatus 0;
BA_ "GenSigTimeoutMsg_HU_B" SG_ 948 OdoICFullSigPeriodicStatus 0;
BA_ "GenSigTimeoutTime_HU_A" SG_ 948 OdoICFullSigPeriodicStatus 0;
BA_ "GenSigTimeoutTime_HU_B" SG_ 948 OdoICFullSigPeriodicStatus 0;
BA_ "GenSigCycleTime" SG_ 1136 PEPSPeriodicSig1 100;
BA_ "GenSigCycleTimeActive" SG_ 1136 PEPSPeriodicSig1 100;
BA_ "GenSigSendType" SG_ 1136 PEPSPeriodicSig1 7;
BA_ "GenSigTimeoutMsg_HU_A" SG_ 1136 PEPSPeriodicSig1 0;
BA_ "GenSigTimeoutMsg_HU_B" SG_ 1136 PEPSPeriodicSig1 0;
BA_ "GenSigTimeoutTime_HU_A" SG_ 1136 PEPSPeriodicSig1 0;
BA_ "GenSigTimeoutTime_HU_B" SG_ 1136 PEPSPeriodicSig1 0;
BA_ "GenSigCycleTime" SG_ 1136 PEPSPeriodicSig2 100;
BA_ "GenSigCycleTimeActive" SG_ 1136 PEPSPeriodicSig2 100;
BA_ "GenSigSendType" SG_ 1136 PEPSPeriodicSig2 7;
BA_ "GenSigTimeoutMsg_HU_A" SG_ 1136 PEPSPeriodicSig2 0;
BA_ "GenSigTimeoutMsg_HU_B" SG_ 1136 PEPSPeriodicSig2 0;
BA_ "GenSigTimeoutTime_HU_A" SG_ 1136 PEPSPeriodicSig2 0;
BA_ "GenSigTimeoutTime_HU_B" SG_ 1136 PEPSPeriodicSig2 0;
BA_ "GenSigCycleTime" SG_ 1136 PEPSPeriodicSig3 100;
BA_ "GenSigCycleTimeActive" SG_ 1136 PEPSPeriodicSig3 100;
BA_ "GenSigSendType" SG_ 1136 PEPSPeriodicSig3 7;
BA_ "GenSigTimeoutMsg_HU_A" SG_ 1136 PEPSPeriodicSig3 0;
BA_ "GenSigTimeoutMsg_HU_B" SG_ 1136 PEPSPeriodicSig3 0;
BA_ "GenSigTimeoutTime_HU_A" SG_ 1136 PEPSPeriodicSig3 0;
BA_ "GenSigTimeoutTime_HU_B" SG_ 1136 PEPSPeriodicSig3 0;
BA_ "GenSigCycleTime" SG_ 1136 PEPSPeriodicSig4 100;
BA_ "GenSigCycleTimeActive" SG_ 1136 PEPSPeriodicSig4 100;
BA_ "GenSigSendType" SG_ 1136 PEPSPeriodicSig4 7;
BA_ "GenSigTimeoutMsg_HU_A" SG_ 1136 PEPSPeriodicSig4 0;
BA_ "GenSigTimeoutMsg_HU_B" SG_ 1136 PEPSPeriodicSig4 0;
BA_ "GenSigTimeoutTime_HU_A" SG_ 1136 PEPSPeriodicSig4 0;
BA_ "GenSigTimeoutTime_HU_B" SG_ 1136 PEPSPeriodicSig4 0;
BA_ "GenSigCycleTime" SG_ 1136 PEPSPeriodicSig5 100;
BA_ "GenSigCycleTimeActive" SG_ 1136 PEPSPeriodicSig5 100;
BA_ "GenSigSendType" SG_ 1136 PEPSPeriodicSig5 7;
BA_ "GenSigTimeoutMsg_HU_A" SG_ 1136 PEPSPeriodicSig5 0;
BA_ "GenSigTimeoutMsg_HU_B" SG_ 1136 PEPSPeriodicSig5 0;
BA_ "GenSigTimeoutTime_HU_A" SG_ 1136 PEPSPeriodicSig5 0;
BA_ "GenSigTimeoutTime_HU_B" SG_ 1136 PEPSPeriodicSig5 0;
BA_ "GenSigCycleTime" SG_ 1136 PEPSPeriodicSig6 100;
BA_ "GenSigCycleTimeActive" SG_ 1136 PEPSPeriodicSig6 100;
BA_ "GenSigSendType" SG_ 1136 PEPSPeriodicSig6 7;
BA_ "GenSigTimeoutMsg_HU_A" SG_ 1136 PEPSPeriodicSig6 0;
BA_ "GenSigTimeoutMsg_HU_B" SG_ 1136 PEPSPeriodicSig6 0;
BA_ "GenSigTimeoutTime_HU_A" SG_ 1136 PEPSPeriodicSig6 0;
BA_ "GenSigTimeoutTime_HU_B" SG_ 1136 PEPSPeriodicSig6 0;
BA_ "GenSigCycleTime" SG_ 1136 PEPSPeriodicSig7 100;
BA_ "GenSigCycleTimeActive" SG_ 1136 PEPSPeriodicSig7 100;
BA_ "GenSigSendType" SG_ 1136 PEPSPeriodicSig7 7;
BA_ "GenSigTimeoutMsg_HU_A" SG_ 1136 PEPSPeriodicSig7 0;
BA_ "GenSigTimeoutMsg_HU_B" SG_ 1136 PEPSPeriodicSig7 0;
BA_ "GenSigTimeoutTime_HU_A" SG_ 1136 PEPSPeriodicSig7 0;
BA_ "GenSigTimeoutTime_HU_B" SG_ 1136 PEPSPeriodicSig7 0;
BA_ "GenSigCycleTime" SG_ 1274 GlobalRealTimeGS 1000;
BA_ "GenSigCycleTimeActive" SG_ 1274 GlobalRealTimeGS 1000;
BA_ "GenSigSendType" SG_ 1274 GlobalRealTimeGS 7;
BA_ "GenSigTimeoutMsg_HU_A" SG_ 1274 GlobalRealTimeGS 5000;
BA_ "GenSigTimeoutMsg_HU_B" SG_ 1274 GlobalRealTimeGS 5000;
BA_ "GenSigTimeoutMsg_HU_High_X451" SG_ 1274 GlobalRealTimeGS 5000;
BA_ "GenSigTimeoutMsg_HU_Mid_X451" SG_ 1274 GlobalRealTimeGS 5000;
BA_ "GenSigTimeoutTime_HU_A" SG_ 1274 GlobalRealTimeGS 5000;
BA_ "GenSigTimeoutTime_HU_B" SG_ 1274 GlobalRealTimeGS 5000;
BA_ "GenSigTimeoutTime_HU_High_X451" SG_ 1274 GlobalRealTimeGS 5000;
BA_ "GenSigTimeoutTime_HU_Mid_X451" SG_ 1274 GlobalRealTimeGS 5000;
BA_ "GenSigCycleTime" SG_ 1274 OdoICFullSigGS 1000;
BA_ "GenSigCycleTimeActive" SG_ 1274 OdoICFullSigGS 1000;
BA_ "GenSigSendType" SG_ 1274 OdoICFullSigGS 7;
BA_ "GenSigTimeoutMsg_HU_A" SG_ 1274 OdoICFullSigGS 5000;
BA_ "GenSigTimeoutMsg_HU_B" SG_ 1274 OdoICFullSigGS 5000;
BA_ "GenSigTimeoutMsg_HU_High_X451" SG_ 1274 OdoICFullSigGS 5000;
BA_ "GenSigTimeoutMsg_HU_Mid_X451" SG_ 1274 OdoICFullSigGS 5000;
BA_ "GenSigTimeoutTime_HU_A" SG_ 1274 OdoICFullSigGS 5000;
BA_ "GenSigTimeoutTime_HU_B" SG_ 1274 OdoICFullSigGS 5000;
BA_ "GenSigTimeoutTime_HU_High_X451" SG_ 1274 OdoICFullSigGS 5000;
BA_ "GenSigTimeoutTime_HU_Mid_X451" SG_ 1274 OdoICFullSigGS 5000;
BA_ "GenSigCycleTime" SG_ 1274 BatVoltGS 1000;
BA_ "GenSigCycleTimeActive" SG_ 1274 BatVoltGS 1000;
BA_ "GenSigSendType" SG_ 1274 BatVoltGS 7;
BA_ "GenSigTimeoutMsg_HU_A" SG_ 1274 BatVoltGS 5000;
BA_ "GenSigTimeoutMsg_HU_B" SG_ 1274 BatVoltGS 5000;
BA_ "GenSigTimeoutMsg_HU_High_X451" SG_ 1274 BatVoltGS 5000;
BA_ "GenSigTimeoutMsg_HU_Mid_X451" SG_ 1274 BatVoltGS 5000;
BA_ "GenSigTimeoutTime_HU_A" SG_ 1274 BatVoltGS 5000;
BA_ "GenSigTimeoutTime_HU_B" SG_ 1274 BatVoltGS 5000;
BA_ "GenSigTimeoutTime_HU_High_X451" SG_ 1274 BatVoltGS 5000;
BA_ "GenSigTimeoutTime_HU_Mid_X451" SG_ 1274 BatVoltGS 5000;
BA_ "GenSigCycleTime" SG_ 1274 VehicleInteriorTempGS 1000;
BA_ "GenSigCycleTimeActive" SG_ 1274 VehicleInteriorTempGS 1000;
BA_ "GenSigSendType" SG_ 1274 VehicleInteriorTempGS 7;
BA_ "GenSigStartValue" SG_ 1274 VehicleInteriorTempGS 40;
BA_ "GenSigTimeoutMsg_HU_A" SG_ 1274 VehicleInteriorTempGS 5000;
BA_ "GenSigTimeoutMsg_HU_B" SG_ 1274 VehicleInteriorTempGS 5000;
BA_ "GenSigTimeoutMsg_HU_High_X451" SG_ 1274 VehicleInteriorTempGS 5000;
BA_ "GenSigTimeoutMsg_HU_Mid_X451" SG_ 1274 VehicleInteriorTempGS 5000;
BA_ "GenSigTimeoutTime_HU_A" SG_ 1274 VehicleInteriorTempGS 5000;
BA_ "GenSigTimeoutTime_HU_B" SG_ 1274 VehicleInteriorTempGS 5000;
BA_ "GenSigTimeoutTime_HU_High_X451" SG_ 1274 VehicleInteriorTempGS 5000;
BA_ "GenSigTimeoutTime_HU_Mid_X451" SG_ 1274 VehicleInteriorTempGS 5000;
BA_ "GenSigCycleTime" SG_ 1276 EngSpdGS 1000;
BA_ "GenSigCycleTimeActive" SG_ 1276 EngSpdGS 1000;
BA_ "GenSigSendType" SG_ 1276 EngSpdGS 7;
BA_ "GenSigTimeoutMsg_HU_A" SG_ 1276 EngSpdGS 5000;
BA_ "GenSigTimeoutMsg_HU_B" SG_ 1276 EngSpdGS 5000;
BA_ "GenSigTimeoutMsg_HU_High_X451" SG_ 1276 EngSpdGS 5000;
BA_ "GenSigTimeoutMsg_HU_Mid_X451" SG_ 1276 EngSpdGS 5000;
BA_ "GenSigTimeoutTime_HU_A" SG_ 1276 EngSpdGS 5000;
BA_ "GenSigTimeoutTime_HU_B" SG_ 1276 EngSpdGS 5000;
BA_ "GenSigTimeoutTime_HU_High_X451" SG_ 1276 EngSpdGS 5000;
BA_ "GenSigTimeoutTime_HU_Mid_X451" SG_ 1276 EngSpdGS 5000;
BA_ "GenSigCycleTime" SG_ 1276 AccPedPosnGS 1000;
BA_ "GenSigCycleTimeActive" SG_ 1276 AccPedPosnGS 1000;
BA_ "GenSigSendType" SG_ 1276 AccPedPosnGS 7;
BA_ "GenSigTimeoutMsg_HU_A" SG_ 1276 AccPedPosnGS 5000;
BA_ "GenSigTimeoutMsg_HU_B" SG_ 1276 AccPedPosnGS 5000;
BA_ "GenSigTimeoutMsg_HU_High_X451" SG_ 1276 AccPedPosnGS 5000;
BA_ "GenSigTimeoutMsg_HU_Mid_X451" SG_ 1276 AccPedPosnGS 5000;
BA_ "GenSigTimeoutTime_HU_A" SG_ 1276 AccPedPosnGS 5000;
BA_ "GenSigTimeoutTime_HU_B" SG_ 1276 AccPedPosnGS 5000;
BA_ "GenSigTimeoutTime_HU_High_X451" SG_ 1276 AccPedPosnGS 5000;
BA_ "GenSigTimeoutTime_HU_Mid_X451" SG_ 1276 AccPedPosnGS 5000;
BA_ "GenSigCycleTime" SG_ 1276 ClntTempGS 1000;
BA_ "GenSigCycleTimeActive" SG_ 1276 ClntTempGS 1000;
BA_ "GenSigSendType" SG_ 1276 ClntTempGS 7;
BA_ "GenSigStartValue" SG_ 1276 ClntTempGS 40;
BA_ "GenSigTimeoutMsg_HU_A" SG_ 1276 ClntTempGS 5000;
BA_ "GenSigTimeoutMsg_HU_B" SG_ 1276 ClntTempGS 5000;
BA_ "GenSigTimeoutMsg_HU_High_X451" SG_ 1276 ClntTempGS 5000;
BA_ "GenSigTimeoutMsg_HU_Mid_X451" SG_ 1276 ClntTempGS 5000;
BA_ "GenSigTimeoutTime_HU_A" SG_ 1276 ClntTempGS 5000;
BA_ "GenSigTimeoutTime_HU_B" SG_ 1276 ClntTempGS 5000;
BA_ "GenSigTimeoutTime_HU_High_X451" SG_ 1276 ClntTempGS 5000;
BA_ "GenSigTimeoutTime_HU_Mid_X451" SG_ 1276 ClntTempGS 5000;
BA_ "GenSigCycleTime" SG_ 1276 VehSpdGS 1000;
BA_ "GenSigCycleTimeActive" SG_ 1276 VehSpdGS 1000;
BA_ "GenSigSendType" SG_ 1276 VehSpdGS 7;
BA_ "GenSigTimeoutMsg_HU_A" SG_ 1276 VehSpdGS 5000;
BA_ "GenSigTimeoutMsg_HU_B" SG_ 1276 VehSpdGS 5000;
BA_ "GenSigTimeoutMsg_HU_High_X451" SG_ 1276 VehSpdGS 5000;
BA_ "GenSigTimeoutMsg_HU_Mid_X451" SG_ 1276 VehSpdGS 5000;
BA_ "GenSigTimeoutTime_HU_A" SG_ 1276 VehSpdGS 5000;
BA_ "GenSigTimeoutTime_HU_B" SG_ 1276 VehSpdGS 5000;
BA_ "GenSigTimeoutTime_HU_High_X451" SG_ 1276 VehSpdGS 5000;
BA_ "GenSigTimeoutTime_HU_Mid_X451" SG_ 1276 VehSpdGS 5000;
BA_ "GenSigCycleTime" SG_ 1276 OATICSigGS 1000;
BA_ "GenSigCycleTimeActive" SG_ 1276 OATICSigGS 1000;
BA_ "GenSigSendType" SG_ 1276 OATICSigGS 7;
BA_ "GenSigStartValue" SG_ 1276 OATICSigGS 40;
BA_ "GenSigTimeoutMsg_HU_A" SG_ 1276 OATICSigGS 5000;
BA_ "GenSigTimeoutMsg_HU_B" SG_ 1276 OATICSigGS 5000;
BA_ "GenSigTimeoutMsg_HU_High_X451" SG_ 1276 OATICSigGS 5000;
BA_ "GenSigTimeoutMsg_HU_Mid_X451" SG_ 1276 OATICSigGS 5000;
BA_ "GenSigTimeoutTime_HU_A" SG_ 1276 OATICSigGS 5000;
BA_ "GenSigTimeoutTime_HU_B" SG_ 1276 OATICSigGS 5000;
BA_ "GenSigTimeoutTime_HU_High_X451" SG_ 1276 OATICSigGS 5000;
BA_ "GenSigTimeoutTime_HU_Mid_X451" SG_ 1276 OATICSigGS 5000;
BA_ "GenSigCycleTime" SG_ 1276 PowerModeStateGS 1000;
BA_ "GenSigCycleTimeActive" SG_ 1276 PowerModeStateGS 1000;
BA_ "GenSigSendType" SG_ 1276 PowerModeStateGS 7;
BA_ "GenSigTimeoutMsg_HU_A" SG_ 1276 PowerModeStateGS 5000;
BA_ "GenSigTimeoutMsg_HU_B" SG_ 1276 PowerModeStateGS 5000;
BA_ "GenSigTimeoutMsg_HU_High_X451" SG_ 1276 PowerModeStateGS 5000;
BA_ "GenSigTimeoutMsg_HU_Mid_X451" SG_ 1276 PowerModeStateGS 5000;
BA_ "GenSigTimeoutTime_HU_A" SG_ 1276 PowerModeStateGS 5000;
BA_ "GenSigTimeoutTime_HU_B" SG_ 1276 PowerModeStateGS 5000;
BA_ "GenSigTimeoutTime_HU_High_X451" SG_ 1276 PowerModeStateGS 5000;
BA_ "GenSigTimeoutTime_HU_Mid_X451" SG_ 1276 PowerModeStateGS 5000;
BA_ "GenSigCycleTime" SG_ 1276 ParkBrkStateGS 1000;
BA_ "GenSigCycleTimeActive" SG_ 1276 ParkBrkStateGS 1000;
BA_ "GenSigSendType" SG_ 1276 ParkBrkStateGS 7;
BA_ "GenSigTimeoutMsg_HU_A" SG_ 1276 ParkBrkStateGS 5000;
BA_ "GenSigTimeoutMsg_HU_B" SG_ 1276 ParkBrkStateGS 5000;
BA_ "GenSigTimeoutMsg_HU_High_X451" SG_ 1276 ParkBrkStateGS 5000;
BA_ "GenSigTimeoutMsg_HU_Mid_X451" SG_ 1276 ParkBrkStateGS 5000;
BA_ "GenSigTimeoutTime_HU_A" SG_ 1276 ParkBrkStateGS 5000;
BA_ "GenSigTimeoutTime_HU_B" SG_ 1276 ParkBrkStateGS 5000;
BA_ "GenSigTimeoutTime_HU_High_X451" SG_ 1276 ParkBrkStateGS 5000;
BA_ "GenSigTimeoutTime_HU_Mid_X451" SG_ 1276 ParkBrkStateGS 5000;
BA_ "GenSigCycleTime" SG_ 1278 VehIdetNumGS 1000;
BA_ "GenSigCycleTimeActive" SG_ 1278 VehIdetNumGS 1000;
BA_ "GenSigSendType" SG_ 1278 VehIdetNumGS 7;
BA_ "GenSigTimeoutMsg_HU_A" SG_ 1278 VehIdetNumGS 5000;
BA_ "GenSigTimeoutMsg_HU_B" SG_ 1278 VehIdetNumGS 5000;
BA_ "GenSigTimeoutMsg_HU_High_X451" SG_ 1278 VehIdetNumGS 5000;
BA_ "GenSigTimeoutMsg_HU_Mid_X451" SG_ 1278 VehIdetNumGS 5000;
BA_ "GenSigTimeoutTime_HU_A" SG_ 1278 VehIdetNumGS 5000;
BA_ "GenSigTimeoutTime_HU_B" SG_ 1278 VehIdetNumGS 5000;
BA_ "GenSigTimeoutTime_HU_High_X451" SG_ 1278 VehIdetNumGS 5000;
BA_ "GenSigTimeoutTime_HU_Mid_X451" SG_ 1278 VehIdetNumGS 5000;
BA_ "GenSigCycleTime" SG_ 1280 BCM_NMPDU_SRC_ECU_ID 200;
BA_ "GenSigCycleTimeActive" SG_ 1280 BCM_NMPDU_SRC_ECU_ID 200;
BA_ "GenSigSendType" SG_ 1280 BCM_NMPDU_SRC_ECU_ID 7;
BA_ "GenSigTimeoutMsg_HU_A" SG_ 1280 BCM_NMPDU_SRC_ECU_ID 1000;
BA_ "GenSigTimeoutMsg_HU_B" SG_ 1280 BCM_NMPDU_SRC_ECU_ID 1000;
BA_ "GenSigTimeoutMsg_HU_High_X451" SG_ 1280 BCM_NMPDU_SRC_ECU_ID 1000;
BA_ "GenSigTimeoutMsg_HU_Mid_X451" SG_ 1280 BCM_NMPDU_SRC_ECU_ID 1000;
BA_ "GenSigTimeoutTime_HU_A" SG_ 1280 BCM_NMPDU_SRC_ECU_ID 1000;
BA_ "GenSigTimeoutTime_HU_B" SG_ 1280 BCM_NMPDU_SRC_ECU_ID 1000;
BA_ "GenSigTimeoutTime_HU_High_X451" SG_ 1280 BCM_NMPDU_SRC_ECU_ID 1000;
BA_ "GenSigTimeoutTime_HU_Mid_X451" SG_ 1280 BCM_NMPDU_SRC_ECU_ID 1000;
BA_ "GenSigCycleTime" SG_ 1280 RepeatMessageReq_BCM 200;
BA_ "GenSigCycleTimeActive" SG_ 1280 RepeatMessageReq_BCM 200;
BA_ "GenSigSendType" SG_ 1280 RepeatMessageReq_BCM 7;
BA_ "GenSigTimeoutMsg_HU_A" SG_ 1280 RepeatMessageReq_BCM 1000;
BA_ "GenSigTimeoutMsg_HU_B" SG_ 1280 RepeatMessageReq_BCM 1000;
BA_ "GenSigTimeoutMsg_HU_High_X451" SG_ 1280 RepeatMessageReq_BCM 1000;
BA_ "GenSigTimeoutMsg_HU_Mid_X451" SG_ 1280 RepeatMessageReq_BCM 1000;
BA_ "GenSigTimeoutTime_HU_A" SG_ 1280 RepeatMessageReq_BCM 1000;
BA_ "GenSigTimeoutTime_HU_B" SG_ 1280 RepeatMessageReq_BCM 1000;
BA_ "GenSigTimeoutTime_HU_High_X451" SG_ 1280 RepeatMessageReq_BCM 1000;
BA_ "GenSigTimeoutTime_HU_Mid_X451" SG_ 1280 RepeatMessageReq_BCM 1000;
BA_ "GenSigCycleTime" SG_ 1280 Reserved0 200;
BA_ "GenSigCycleTimeActive" SG_ 1280 Reserved0 200;
BA_ "GenSigSendType" SG_ 1280 Reserved0 7;
BA_ "GenSigTimeoutMsg_HU_A" SG_ 1280 Reserved0 1000;
BA_ "GenSigTimeoutMsg_HU_B" SG_ 1280 Reserved0 1000;
BA_ "GenSigTimeoutMsg_HU_High_X451" SG_ 1280 Reserved0 1000;
BA_ "GenSigTimeoutMsg_HU_Mid_X451" SG_ 1280 Reserved0 1000;
BA_ "GenSigTimeoutTime_HU_A" SG_ 1280 Reserved0 1000;
BA_ "GenSigTimeoutTime_HU_B" SG_ 1280 Reserved0 1000;
BA_ "GenSigTimeoutTime_HU_High_X451" SG_ 1280 Reserved0 1000;
BA_ "GenSigTimeoutTime_HU_Mid_X451" SG_ 1280 Reserved0 1000;
BA_ "GenSigCycleTime" SG_ 1280 Reserved1 200;
BA_ "GenSigCycleTimeActive" SG_ 1280 Reserved1 200;
BA_ "GenSigSendType" SG_ 1280 Reserved1 7;
BA_ "GenSigTimeoutMsg_HU_A" SG_ 1280 Reserved1 1000;
BA_ "GenSigTimeoutMsg_HU_B" SG_ 1280 Reserved1 1000;
BA_ "GenSigTimeoutMsg_HU_High_X451" SG_ 1280 Reserved1 1000;
BA_ "GenSigTimeoutMsg_HU_Mid_X451" SG_ 1280 Reserved1 1000;
BA_ "GenSigTimeoutTime_HU_A" SG_ 1280 Reserved1 1000;
BA_ "GenSigTimeoutTime_HU_B" SG_ 1280 Reserved1 1000;
BA_ "GenSigTimeoutTime_HU_High_X451" SG_ 1280 Reserved1 1000;
BA_ "GenSigTimeoutTime_HU_Mid_X451" SG_ 1280 Reserved1 1000;
BA_ "GenSigCycleTime" SG_ 1280 NMCoOrdSlpReady_BCM 200;
BA_ "GenSigCycleTimeActive" SG_ 1280 NMCoOrdSlpReady_BCM 200;
BA_ "GenSigSendType" SG_ 1280 NMCoOrdSlpReady_BCM 7;
BA_ "GenSigTimeoutMsg_HU_A" SG_ 1280 NMCoOrdSlpReady_BCM 1000;
BA_ "GenSigTimeoutMsg_HU_B" SG_ 1280 NMCoOrdSlpReady_BCM 1000;
BA_ "GenSigTimeoutMsg_HU_High_X451" SG_ 1280 NMCoOrdSlpReady_BCM 1000;
BA_ "GenSigTimeoutMsg_HU_Mid_X451" SG_ 1280 NMCoOrdSlpReady_BCM 1000;
BA_ "GenSigTimeoutTime_HU_A" SG_ 1280 NMCoOrdSlpReady_BCM 1000;
BA_ "GenSigTimeoutTime_HU_B" SG_ 1280 NMCoOrdSlpReady_BCM 1000;
BA_ "GenSigTimeoutTime_HU_High_X451" SG_ 1280 NMCoOrdSlpReady_BCM 1000;
BA_ "GenSigTimeoutTime_HU_Mid_X451" SG_ 1280 NMCoOrdSlpReady_BCM 1000;
BA_ "GenSigCycleTime" SG_ 1280 ActiveWakeUp_BCM 200;
BA_ "GenSigCycleTimeActive" SG_ 1280 ActiveWakeUp_BCM 200;
BA_ "GenSigSendType" SG_ 1280 ActiveWakeUp_BCM 7;
BA_ "GenSigTimeoutMsg_HU_A" SG_ 1280 ActiveWakeUp_BCM 1000;
BA_ "GenSigTimeoutMsg_HU_B" SG_ 1280 ActiveWakeUp_BCM 1000;
BA_ "GenSigTimeoutMsg_HU_High_X451" SG_ 1280 ActiveWakeUp_BCM 1000;
BA_ "GenSigTimeoutMsg_HU_Mid_X451" SG_ 1280 ActiveWakeUp_BCM 1000;
BA_ "GenSigTimeoutTime_HU_A" SG_ 1280 ActiveWakeUp_BCM 1000;
BA_ "GenSigTimeoutTime_HU_B" SG_ 1280 ActiveWakeUp_BCM 1000;
BA_ "GenSigTimeoutTime_HU_High_X451" SG_ 1280 ActiveWakeUp_BCM 1000;
BA_ "GenSigTimeoutTime_HU_Mid_X451" SG_ 1280 ActiveWakeUp_BCM 1000;
BA_ "GenSigCycleTime" SG_ 1280 Reserved2 200;
BA_ "GenSigCycleTimeActive" SG_ 1280 Reserved2 200;
BA_ "GenSigSendType" SG_ 1280 Reserved2 7;
BA_ "GenSigTimeoutMsg_HU_A" SG_ 1280 Reserved2 1000;
BA_ "GenSigTimeoutMsg_HU_B" SG_ 1280 Reserved2 1000;
BA_ "GenSigTimeoutMsg_HU_High_X451" SG_ 1280 Reserved2 1000;
BA_ "GenSigTimeoutMsg_HU_Mid_X451" SG_ 1280 Reserved2 1000;
BA_ "GenSigTimeoutTime_HU_A" SG_ 1280 Reserved2 1000;
BA_ "GenSigTimeoutTime_HU_B" SG_ 1280 Reserved2 1000;
BA_ "GenSigTimeoutTime_HU_High_X451" SG_ 1280 Reserved2 1000;
BA_ "GenSigTimeoutTime_HU_Mid_X451" SG_ 1280 Reserved2 1000;
BA_ "GenSigCycleTime" SG_ 1280 PartialNetworkInformation_BCM 200;
BA_ "GenSigCycleTimeActive" SG_ 1280 PartialNetworkInformation_BCM 200;
BA_ "GenSigSendType" SG_ 1280 PartialNetworkInformation_BCM 7;
BA_ "GenSigTimeoutMsg_HU_A" SG_ 1280 PartialNetworkInformation_BCM 1000;
BA_ "GenSigTimeoutMsg_HU_B" SG_ 1280 PartialNetworkInformation_BCM 1000;
BA_ "GenSigTimeoutMsg_HU_High_X451" SG_ 1280 PartialNetworkInformation_BCM 1000;
BA_ "GenSigTimeoutMsg_HU_Mid_X451" SG_ 1280 PartialNetworkInformation_BCM 1000;
BA_ "GenSigTimeoutTime_HU_A" SG_ 1280 PartialNetworkInformation_BCM 1000;
BA_ "GenSigTimeoutTime_HU_B" SG_ 1280 PartialNetworkInformation_BCM 1000;
BA_ "GenSigTimeoutTime_HU_High_X451" SG_ 1280 PartialNetworkInformation_BCM 1000;
BA_ "GenSigTimeoutTime_HU_Mid_X451" SG_ 1280 PartialNetworkInformation_BCM 1000;
BA_ "GenSigCycleTime" SG_ 1280 Reserved3 200;
BA_ "GenSigCycleTimeActive" SG_ 1280 Reserved3 200;
BA_ "GenSigSendType" SG_ 1280 Reserved3 7;
BA_ "GenSigTimeoutMsg_HU_A" SG_ 1280 Reserved3 1000;
BA_ "GenSigTimeoutMsg_HU_B" SG_ 1280 Reserved3 1000;
BA_ "GenSigTimeoutMsg_HU_High_X451" SG_ 1280 Reserved3 1000;
BA_ "GenSigTimeoutMsg_HU_Mid_X451" SG_ 1280 Reserved3 1000;
BA_ "GenSigTimeoutTime_HU_A" SG_ 1280 Reserved3 1000;
BA_ "GenSigTimeoutTime_HU_B" SG_ 1280 Reserved3 1000;
BA_ "GenSigTimeoutTime_HU_High_X451" SG_ 1280 Reserved3 1000;
BA_ "GenSigTimeoutTime_HU_Mid_X451" SG_ 1280 Reserved3 1000;
BA_ "GenSigCycleTime" SG_ 1280 CurrentState_BCM 200;
BA_ "GenSigCycleTimeActive" SG_ 1280 CurrentState_BCM 200;
BA_ "GenSigSendType" SG_ 1280 CurrentState_BCM 7;
BA_ "GenSigTimeoutMsg_HU_A" SG_ 1280 CurrentState_BCM 1000;
BA_ "GenSigTimeoutMsg_HU_B" SG_ 1280 CurrentState_BCM 1000;
BA_ "GenSigTimeoutMsg_HU_High_X451" SG_ 1280 CurrentState_BCM 1000;
BA_ "GenSigTimeoutMsg_HU_Mid_X451" SG_ 1280 CurrentState_BCM 1000;
BA_ "GenSigTimeoutTime_HU_A" SG_ 1280 CurrentState_BCM 1000;
BA_ "GenSigTimeoutTime_HU_B" SG_ 1280 CurrentState_BCM 1000;
BA_ "GenSigTimeoutTime_HU_High_X451" SG_ 1280 CurrentState_BCM 1000;
BA_ "GenSigTimeoutTime_HU_Mid_X451" SG_ 1280 CurrentState_BCM 1000;
BA_ "GenSigCycleTime" SG_ 1280 PreviousState_BCM 200;
BA_ "GenSigCycleTimeActive" SG_ 1280 PreviousState_BCM 200;
BA_ "GenSigSendType" SG_ 1280 PreviousState_BCM 7;
BA_ "GenSigTimeoutMsg_HU_A" SG_ 1280 PreviousState_BCM 1000;
BA_ "GenSigTimeoutMsg_HU_B" SG_ 1280 PreviousState_BCM 1000;
BA_ "GenSigTimeoutMsg_HU_High_X451" SG_ 1280 PreviousState_BCM 1000;
BA_ "GenSigTimeoutMsg_HU_Mid_X451" SG_ 1280 PreviousState_BCM 1000;
BA_ "GenSigTimeoutTime_HU_A" SG_ 1280 PreviousState_BCM 1000;
BA_ "GenSigTimeoutTime_HU_B" SG_ 1280 PreviousState_BCM 1000;
BA_ "GenSigTimeoutTime_HU_High_X451" SG_ 1280 PreviousState_BCM 1000;
BA_ "GenSigTimeoutTime_HU_Mid_X451" SG_ 1280 PreviousState_BCM 1000;
BA_ "GenSigCycleTime" SG_ 1280 Reserved4 200;
BA_ "GenSigCycleTimeActive" SG_ 1280 Reserved4 200;
BA_ "GenSigSendType" SG_ 1280 Reserved4 7;
BA_ "GenSigTimeoutMsg_HU_A" SG_ 1280 Reserved4 1000;
BA_ "GenSigTimeoutMsg_HU_B" SG_ 1280 Reserved4 1000;
BA_ "GenSigTimeoutMsg_HU_High_X451" SG_ 1280 Reserved4 1000;
BA_ "GenSigTimeoutMsg_HU_Mid_X451" SG_ 1280 Reserved4 1000;
BA_ "GenSigTimeoutTime_HU_A" SG_ 1280 Reserved4 1000;
BA_ "GenSigTimeoutTime_HU_B" SG_ 1280 Reserved4 1000;
BA_ "GenSigTimeoutTime_HU_High_X451" SG_ 1280 Reserved4 1000;
BA_ "GenSigTimeoutTime_HU_Mid_X451" SG_ 1280 Reserved4 1000;
BA_ "GenSigCycleTime" SG_ 1280 Reserved5 200;
BA_ "GenSigCycleTimeActive" SG_ 1280 Reserved5 200;
BA_ "GenSigSendType" SG_ 1280 Reserved5 7;
BA_ "GenSigTimeoutMsg_HU_A" SG_ 1280 Reserved5 1000;
BA_ "GenSigTimeoutMsg_HU_B" SG_ 1280 Reserved5 1000;
BA_ "GenSigTimeoutMsg_HU_High_X451" SG_ 1280 Reserved5 1000;
BA_ "GenSigTimeoutMsg_HU_Mid_X451" SG_ 1280 Reserved5 1000;
BA_ "GenSigTimeoutTime_HU_A" SG_ 1280 Reserved5 1000;
BA_ "GenSigTimeoutTime_HU_B" SG_ 1280 Reserved5 1000;
BA_ "GenSigTimeoutTime_HU_High_X451" SG_ 1280 Reserved5 1000;
BA_ "GenSigTimeoutTime_HU_Mid_X451" SG_ 1280 Reserved5 1000;
BA_ "GenSigCycleTime" SG_ 1280 Reserved6 200;
BA_ "GenSigCycleTimeActive" SG_ 1280 Reserved6 200;
BA_ "GenSigSendType" SG_ 1280 Reserved6 7;
BA_ "GenSigTimeoutMsg_HU_A" SG_ 1280 Reserved6 1000;
BA_ "GenSigTimeoutMsg_HU_B" SG_ 1280 Reserved6 1000;
BA_ "GenSigTimeoutMsg_HU_High_X451" SG_ 1280 Reserved6 1000;
BA_ "GenSigTimeoutMsg_HU_Mid_X451" SG_ 1280 Reserved6 1000;
BA_ "GenSigTimeoutTime_HU_A" SG_ 1280 Reserved6 1000;
BA_ "GenSigTimeoutTime_HU_B" SG_ 1280 Reserved6 1000;
BA_ "GenSigTimeoutTime_HU_High_X451" SG_ 1280 Reserved6 1000;
BA_ "GenSigTimeoutTime_HU_Mid_X451" SG_ 1280 Reserved6 1000;
BA_ "GenSigCycleTime" SG_ 1280 Reserved7 200;
BA_ "GenSigCycleTimeActive" SG_ 1280 Reserved7 200;
BA_ "GenSigSendType" SG_ 1280 Reserved7 7;
BA_ "GenSigTimeoutMsg_HU_A" SG_ 1280 Reserved7 1000;
BA_ "GenSigTimeoutMsg_HU_B" SG_ 1280 Reserved7 1000;
BA_ "GenSigTimeoutMsg_HU_High_X451" SG_ 1280 Reserved7 1000;
BA_ "GenSigTimeoutMsg_HU_Mid_X451" SG_ 1280 Reserved7 1000;
BA_ "GenSigTimeoutTime_HU_A" SG_ 1280 Reserved7 1000;
BA_ "GenSigTimeoutTime_HU_B" SG_ 1280 Reserved7 1000;
BA_ "GenSigTimeoutTime_HU_High_X451" SG_ 1280 Reserved7 1000;
BA_ "GenSigTimeoutTime_HU_Mid_X451" SG_ 1280 Reserved7 1000;
BA_ "GenSigCycleTime" SG_ 1280 BCM_NMPDU_USER_DATA_D1 200;
BA_ "GenSigCycleTimeActive" SG_ 1280 BCM_NMPDU_USER_DATA_D1 200;
BA_ "GenSigSendType" SG_ 1280 BCM_NMPDU_USER_DATA_D1 7;
BA_ "GenSigTimeoutMsg_HU_A" SG_ 1280 BCM_NMPDU_USER_DATA_D1 1000;
BA_ "GenSigTimeoutMsg_HU_B" SG_ 1280 BCM_NMPDU_USER_DATA_D1 1000;
BA_ "GenSigTimeoutMsg_HU_High_X451" SG_ 1280 BCM_NMPDU_USER_DATA_D1 1000;
BA_ "GenSigTimeoutMsg_HU_Mid_X451" SG_ 1280 BCM_NMPDU_USER_DATA_D1 1000;
BA_ "GenSigTimeoutTime_HU_A" SG_ 1280 BCM_NMPDU_USER_DATA_D1 1000;
BA_ "GenSigTimeoutTime_HU_B" SG_ 1280 BCM_NMPDU_USER_DATA_D1 1000;
BA_ "GenSigTimeoutTime_HU_High_X451" SG_ 1280 BCM_NMPDU_USER_DATA_D1 1000;
BA_ "GenSigTimeoutTime_HU_Mid_X451" SG_ 1280 BCM_NMPDU_USER_DATA_D1 1000;
BA_ "GenSigCycleTime" SG_ 1280 BCM_NMPDU_USER_DATA_D2 200;
BA_ "GenSigCycleTimeActive" SG_ 1280 BCM_NMPDU_USER_DATA_D2 200;
BA_ "GenSigSendType" SG_ 1280 BCM_NMPDU_USER_DATA_D2 7;
BA_ "GenSigTimeoutMsg_HU_A" SG_ 1280 BCM_NMPDU_USER_DATA_D2 1000;
BA_ "GenSigTimeoutMsg_HU_B" SG_ 1280 BCM_NMPDU_USER_DATA_D2 1000;
BA_ "GenSigTimeoutMsg_HU_High_X451" SG_ 1280 BCM_NMPDU_USER_DATA_D2 1000;
BA_ "GenSigTimeoutMsg_HU_Mid_X451" SG_ 1280 BCM_NMPDU_USER_DATA_D2 1000;
BA_ "GenSigTimeoutTime_HU_A" SG_ 1280 BCM_NMPDU_USER_DATA_D2 1000;
BA_ "GenSigTimeoutTime_HU_B" SG_ 1280 BCM_NMPDU_USER_DATA_D2 1000;
BA_ "GenSigTimeoutTime_HU_High_X451" SG_ 1280 BCM_NMPDU_USER_DATA_D2 1000;
BA_ "GenSigTimeoutTime_HU_Mid_X451" SG_ 1280 BCM_NMPDU_USER_DATA_D2 1000;
BA_ "GenSigCycleTime" SG_ 1280 BCM_NMPDU_USER_DATA_D3 200;
BA_ "GenSigCycleTimeActive" SG_ 1280 BCM_NMPDU_USER_DATA_D3 200;
BA_ "GenSigSendType" SG_ 1280 BCM_NMPDU_USER_DATA_D3 7;
BA_ "GenSigTimeoutMsg_HU_A" SG_ 1280 BCM_NMPDU_USER_DATA_D3 1000;
BA_ "GenSigTimeoutMsg_HU_B" SG_ 1280 BCM_NMPDU_USER_DATA_D3 1000;
BA_ "GenSigTimeoutMsg_HU_High_X451" SG_ 1280 BCM_NMPDU_USER_DATA_D3 1000;
BA_ "GenSigTimeoutMsg_HU_Mid_X451" SG_ 1280 BCM_NMPDU_USER_DATA_D3 1000;
BA_ "GenSigTimeoutTime_HU_A" SG_ 1280 BCM_NMPDU_USER_DATA_D3 1000;
BA_ "GenSigTimeoutTime_HU_B" SG_ 1280 BCM_NMPDU_USER_DATA_D3 1000;
BA_ "GenSigTimeoutTime_HU_High_X451" SG_ 1280 BCM_NMPDU_USER_DATA_D3 1000;
BA_ "GenSigTimeoutTime_HU_Mid_X451" SG_ 1280 BCM_NMPDU_USER_DATA_D3 1000;
BA_ "GenSigCycleTime" SG_ 1280 BCM_NMPDU_USER_DATA_D4 200;
BA_ "GenSigCycleTimeActive" SG_ 1280 BCM_NMPDU_USER_DATA_D4 200;
BA_ "GenSigSendType" SG_ 1280 BCM_NMPDU_USER_DATA_D4 7;
BA_ "GenSigTimeoutMsg_HU_A" SG_ 1280 BCM_NMPDU_USER_DATA_D4 1000;
BA_ "GenSigTimeoutMsg_HU_B" SG_ 1280 BCM_NMPDU_USER_DATA_D4 1000;
BA_ "GenSigTimeoutMsg_HU_High_X451" SG_ 1280 BCM_NMPDU_USER_DATA_D4 1000;
BA_ "GenSigTimeoutMsg_HU_Mid_X451" SG_ 1280 BCM_NMPDU_USER_DATA_D4 1000;
BA_ "GenSigTimeoutTime_HU_A" SG_ 1280 BCM_NMPDU_USER_DATA_D4 1000;
BA_ "GenSigTimeoutTime_HU_B" SG_ 1280 BCM_NMPDU_USER_DATA_D4 1000;
BA_ "GenSigTimeoutTime_HU_High_X451" SG_ 1280 BCM_NMPDU_USER_DATA_D4 1000;
BA_ "GenSigTimeoutTime_HU_Mid_X451" SG_ 1280 BCM_NMPDU_USER_DATA_D4 1000;
BA_ "GenSigCycleTime" SG_ 1280 BCM_NMPDU_USER_DATA_D5 200;
BA_ "GenSigCycleTimeActive" SG_ 1280 BCM_NMPDU_USER_DATA_D5 200;
BA_ "GenSigSendType" SG_ 1280 BCM_NMPDU_USER_DATA_D5 7;
BA_ "GenSigTimeoutMsg_HU_A" SG_ 1280 BCM_NMPDU_USER_DATA_D5 1000;
BA_ "GenSigTimeoutMsg_HU_B" SG_ 1280 BCM_NMPDU_USER_DATA_D5 1000;
BA_ "GenSigTimeoutMsg_HU_High_X451" SG_ 1280 BCM_NMPDU_USER_DATA_D5 1000;
BA_ "GenSigTimeoutMsg_HU_Mid_X451" SG_ 1280 BCM_NMPDU_USER_DATA_D5 1000;
BA_ "GenSigTimeoutTime_HU_A" SG_ 1280 BCM_NMPDU_USER_DATA_D5 1000;
BA_ "GenSigTimeoutTime_HU_B" SG_ 1280 BCM_NMPDU_USER_DATA_D5 1000;
BA_ "GenSigTimeoutTime_HU_High_X451" SG_ 1280 BCM_NMPDU_USER_DATA_D5 1000;
BA_ "GenSigTimeoutTime_HU_Mid_X451" SG_ 1280 BCM_NMPDU_USER_DATA_D5 1000;
VAL_ 724 PtcTempValStatus 3 "Signal not available" 2 "Implausible" 1 "Reserved for future use" 0 "Plausible and signal is correct" ;
VAL_ 724 CCMVbatStatus 3 "Signal Not Available" 2 "Implausible" 1 "Reserved" 0 "Plausible" ;
VAL_ 724 BlowerFBVoltageStatus 3 "Signal BlowerFBVoltage Not Available" 2 "Information given at BlowerFBVoltage is implausible" 1 "Reserved for future use" 0 "Information  is correct and according to specification" ;
VAL_ 724 BlowerPWMStatus 3 "Signal BlowerPWM  Not Available" 2 "Information given at BlowerPWM  is implausible" 1 "Reserved for future use" 0 "Information  is correct and according to specification" ;
VAL_ 724 BlowerStatus 3 "Signal BlowerStatus Not Available" 2 "Information given at blowerstatus is implausible" 1 "Reserved for future use" 0 "Information  is correct and according to specification" ;
VAL_ 724 BlowerState 3 "Fault Occurred" 2 "On" 1 "Off " 0 "Not initialised" ;
VAL_ 724 HeatingPwrValStatus 3 "Signal not available" 2 "Implausible" 1 "Reserved for future use" 0 "Plausible and signal is correct" ;
VAL_ 724 CoolingPwrValStatus 3 "Signal not available" 2 "Implausible" 1 "Reserved for future use" 0 "Plausible and signal is correct" ;
VAL_ 724 AcReqNew 1 "AC request from driver activated" 0 "AC Request from driver deactivated" ;
VAL_ 408 ICDispSpeedSigStatus 3 "Reserved" 2 "Implausible -Information given at ICDispSpeedSig is implausible" 1 "Reserved for future use" 0 "Plausible-Informationgiveniscorrectandaccordingtospecification" ;
VAL_ 495 RemoteValetCmdStatus 3 "Signal not available" 2 "Signal is implausible" 1 "Don't Care " 0 "Plausible and signal is correct" ;
VAL_ 495 RemoteValetCmd 1 "valet Command enable" 0 "Valet command Disable" ;
VAL_ 617 GearSelectionSwStateStatus 3 "Signal Not available" 2 "Information given  is implausible" 1 "Reserved" 0 "Information given is correct and according to specification" ;
VAL_ 617 GearSelectionSwState 15 "Reserved" 14 "Reserved" 13 "Reserved" 12 "Reserved" 11 "Reserved" 10 "Reserved" 9 "Reserved" 8 "Reserved" 7 "Reserved" 6 "Reserved" 5 "Reserved" 4 "Reserved" 3 "Reverse" 2 "Sport" 1 "Drive" 0 "Neutral" ;
VAL_ 580 VehicleStatus 7 "Reserved" 6 "Reserved" 5 "Reserved" 4 "Reserved" 3 "EV System Disengaged" 2 "Not Ready to Go,  HV System Not Ready" 1 "Not Ready to Go, Charger Connected" 0 "Ready to Go" ;
VAL_ 580 VcuStatus 1 "VCU Malfunction" 0 "VCU Normal" ;
VAL_ 580 ValetStateStatus 3 "Signal not available" 2 "Signal is implausible" 1 "Reserved for future use" 0 "Plausible and signal is correct" ;
VAL_ 580 ValetState 1 "Valet State Mode On" 0 "Valet State Mode OFF" ;
VAL_ 580 AcComprMalFn 1 "AC Compressor Malfunction" 0 "AC Compressor Normal" ;
VAL_ 580 AcCmprStatusVcu 1 "AC Compressor is On" 0 "AC Compressor is Off" ;
VAL_ 580 VcuPowerMode 15 "Reserved" 14 "Reserved" 13 "Reserved" 12 "Reserved" 11 "Reserved" 10 "Reserved" 9 "Reserved" 8 "Reserved" 7 "Reserved" 6 "Limited power mode" 5 "Charging mode" 4 "Energy Recuperation" 3 "Normal Run" 2 "Crank" 1 "Active" 0 "Awake" ;
VAL_ 580 VcuPowerModeStatus 3 "Reserved" 2 "Information given is implausible due to a detected failure" 1 "Reserved" 0 "Information given is correct and according to specification" ;
VAL_ 579 BrkVacPumpStatus 1 "Brake Vaccum Pump Malfunction" 0 "Brake Vaccum Pump Normal" ;
VAL_ 579 DriveMotorStatus 1 "Drive Motor Malfunction" 0 "Drive Motor  Normal" ;
VAL_ 579 HvBattSoh 1 "HV Batt SOH Not OK" 0 "HV Batt SOH OK" ;
VAL_ 579 HvBattPackVolStatus 3 "Reserved" 2 "Information is implausible due to a detected failure " 1 "Reserved" 0 "Information is correct and according to specification" ;
VAL_ 579 AvgEnergyConsmptionStatus 3 "Reserved" 2 "Information given is implausible due to a detected failure" 1 "Reserved" 0 "Information given is correct and according to specification" ;
VAL_ 579 MotorHightempStatus 3 "Reserved" 2 "Information given is implausible due to a detected failure" 1 "Reserved" 0 "Information given is correct and according to specification" ;
VAL_ 579 MotorHightemp 3 " Reserved for future use" 2 "Motor Temp lamp ON" 1 "Motor Temp lamp Flashing" 0 "Motor Temp lamp is OFF. " ;
VAL_ 579 VcuGearSelectionChangeTxt 3 "Signal not available" 2 "Gear Selections selection is not possible due to System failure" 1 "Press The Brake for Gear selection " 0 "Gear selection possible" ;
VAL_ 579 ImmoStatusVcu 1 "VCU is immobilized" 0 "VCU is mobilized" ;
VAL_ 579 ClntTempVcuStatus 3 "Reserved for future use" 2 "Value is implausible" 1 "Reserved for future use" 0 "ClntTemp signal is correct" ;
VAL_ 579 GearForDisplayVcu 15 "Reserved" 14 "Reserved" 13 "Reserved" 12 "Reserved" 11 "Reserved" 10 "Reserved" 9 "Reserved" 8 "Reserved" 7 "Reserved" 6 "Reserved" 5 "Sport" 4 "Forward/Drive" 3 "Neutral" 2 "Reverse" 1 "Park" 0 "Not Used" ;
VAL_ 579 GearForDisplayVcuStatus 3 "Reserved" 2 "Information given is implausible due to a detected failure" 1 "Reserved" 0 "Information given correct and according to specification" ;
VAL_ 273 CurrentTorqueToWheelStatus 3 "Reserved for future use" 2 "Information given  is implausible" 1 "Reserved for future use" 0 "Information given is correct " ;
VAL_ 273 AccPedPosnVcuStatus 3 "Reserved" 2 "Information given is implausible" 1 "Reserved" 0 "Information given is correct" ;
VAL_ 273 BrkPressStateVcu 1 "Brake is not pressed" 0 "Brake is pressed" ;
VAL_ 273 BrkPressStatusVcu 3 "Reserved" 2 "Information given is implausible due to a detected failure" 1 "Reserved" 0 "Information given is correct and according to specification" ;
VAL_ 259 CrashoutputSignal 16 "Left hand side deploy crash" 8 "Right hand side deploy crash" 4 "Rear Crash" 2 "Front Deploy Crash" 1 "No Fire Crash" 0 "No Crash" ;
VAL_ 262 BrkPressStatus 3 "Signal not available" 2 "Value is implausible" 1 "Reserved for future" 0 "Value is correct" ;
VAL_ 262 BrkPressState 1 "Brake pedal Released" 0 "Brake pedal pressed" ;
VAL_ 262 EngSpdStatus 3 "Reserved for future use" 2 "Value is implausible" 1 "Reserved for future use" 0 "EngSpd signal is correct" ;
VAL_ 262 AccPedRocStatus 3 "Signal not available" 2 "Signal  AccPedROC is implausible" 1 "Reserved for future use" 0 "Signal  AccPedROC is correct" ;
VAL_ 262 EngIdleSpdStatus 3 "Signal not available" 2 "Value is implausible" 1 "Reserved" 0 "Value is correct" ;
VAL_ 262 AccPedPosnStatus 3 "Signal not available" 2 "AccPedPosn signal value is implausible" 1 "Reserved for future use" 0 "Signal AccPedPosn is correct " ;
VAL_ 370 BrkLightSig 1 "Brake lamp on request" 0 "No request od brake lamp" ;
VAL_ 370 BrkLightSigStatus 3 "Signal not available" 2 "Value is implausible" 1 "Reserved for future" 0 "Value is correct" ;
VAL_ 370 ABsActive 1 "ABS intervention by ABS/ESP is active" 0 "No ABS internention by ABS/ESP" ;
VAL_ 370 EBdStatus 3 "Reserved for future" 2 "EBD function is switched off due to failure @EBD Warn Lamp is ON" 1 "Reserved for future" 0 "EBD function fully available@EBD Warning Lamp is OFF" ;
VAL_ 370 EBdActive 1 "EBD intervention  by ABS/ESP is active" 0 "No EBD intervention by ABS/ESP" ;
VAL_ 370 ABsStatus 3 "Reserved for future" 2 "ABS function switched off due to failure at ABS/ESP@ABS Warn Lamp ON" 1 "Reserved for future" 0 "ABS function fully available@ABS Warning Lamp is OFF" ;
VAL_ 374 ODoABsStatus 3 "Reserved for future use" 2 "Signal is implausible due to detected failure" 1 "Reserved for future" 0 "Signal is correct" ;
VAL_ 374 VehSpdABsStatus 3 "Reserved for future" 2 "Value is implausible" 1 "Reserved for future" 0 "Value is correct" ;
VAL_ 646 UserSpdLimLamp 1 "UserSpdLimLamp is active" 0 "UserSpdLimLamp is not active" ;
VAL_ 646 UserSpdLimFault 3 "other subsystem fault (engine fault)" 2 "Speed limiter regulation fault" 1 "Speed limiter input switch fault" 0 "No Fault detected" ;
VAL_ 646 UserSpdLimStatus 3 "Signal not available" 2 "Signal is Implausible" 1 "Reserved for future use" 0 "Signal is correct" ;
VAL_ 646 EngStatus 7 "Reserved for future" 6 "Reserved for future" 5 "Engine stalled" 4 "Engine ready to crank" 3 "Engine running" 2 "Engine running at idle speed" 1 "Engine cranking in progress" 0 "Engine not running/Ignition ON" ;
VAL_ 646 CeLampState 3 "Not supported or Signal not available" 2 "Check engine /Service lamp Flashing" 1 "Check engine /Service lamp is ON" 0 "Check engine /Service lamp is Off" ;
VAL_ 646 StaterProhibitionDelay 1 "Prohibition delay is  active" 0 "Prohibition delay is not active" ;
VAL_ 646 StarterControlState 3 "Starter function  fault-Stalled starter" 2 "Starter function fault-Relay" 1 "Starter switched OFF by EMS" 0 "Starter switched ON by EMS" ;
VAL_ 646 UserSpdLimState 3 "Temporary override" 2 "Speed limter active" 1 "Speed limiter enabled" 0 "Speed limiter disabled" ;
VAL_ 646 SFCActiveEMS 3 "Function not present" 2 "Reserved for future use " 1 "SFC fucntion is  active" 0 "SFC fucntion is  disabled" ;
VAL_ 646 DrvModeIndctnEMSstatus 3 "Signal not available" 2 "Signal is Implausible" 1 "Reserved for future use" 0 "Signal is correct" ;
VAL_ 646 CruiseSpdLamp 3 "Not applicable or  Not supported" 2 "Temporary override" 1 "Cruise Lamp is Active" 0 "Cruise Lamp is Not active" ;
VAL_ 646 StartercControlStatus 3 "Signal not available" 2 "Signal is Implausible" 1 "Reserved for future use" 0 "Signal is correct" ;
VAL_ 646 CurrGearEms 15 "Reserved" 14 "Reserved" 13 "Reserved" 12 "Reserved" 11 "Reserved" 10 "Reserved" 9 "Reserved" 8 "Reverse Gear" 7 "Sixth Gear" 6 "Fifth Gear" 5 "Fourth Gear" 4 "Third Gear" 3 "Second Gear" 2 "First Gear" 1 "No gear engaged/ neutral" 0 "Invalid Gear" ;
VAL_ 646 CruiseSpdFault 3 "other subsystem fault" 2 "Cruise regulation fault" 1 "Cruise input switch fault" 0 "Value is correct" ;
VAL_ 646 CruiseSpdStatus 3 "Signal not available" 2 "Signal is Implausible" 1 "Reserved for future use" 0 "Signal is correct" ;
VAL_ 646 CurrGearEmsStatus 3 "Signal not available" 2 "Value is implausible" 1 "Reserved" 0 "Signal is plausible" ;
VAL_ 646 GearShiftIndctnEmsStatus 3 "Signal not available" 2 "Signal is Implausible" 1 "Reserved for future use" 0 "Signal is correct" ;
VAL_ 646 GearShiftIndctnEms 7 "Signal Not available" 6 "Reserved for future use" 5 "Reserved for future use" 4 "Reserved for future use" 3 "Reserved for future use" 2 "Shift Gear Up" 1 "Shift Gear Down" 0 "GearShift OK" ;
VAL_ 646 CruiseSwitchstate 3 "Invalid Key Pressed" 2 "Set / Cruise Spd - Key pressed" 1 "Resume / Cruise Spd+ Key pressed" 0 "No Key ( Resume/Cruise Speed+  && Set/Cruise Speed - ) pressed" ;
VAL_ 646 CruiseSwitchstateStatus 3 "Signal not available" 2 "Value is implausible " 1 "Reserved for future use" 0 "Signal is correct" ;
VAL_ 646 DrvModeIndctnEMS 15 "Reserved" 14 "Reserved" 13 "Reserved" 12 "Reserved" 11 "Tiptronic Rough Mode" 10 "Automatic Rough Mode" 9 "Manual Rough Mode" 8 "Tiptronic Economy Mode" 7 "Tiptronic Sport Mode" 6 "Tiptronic Normal / City Mode" 5 "Automatic Economy Mode" 4 "Automatic Sport Mode" 3 "Automatic Normal / City" 2 "Manual Economy Mode" 1 "Manual Sport Mode" 0 "Manual Normal / City Mode" ;
VAL_ 697 IcHuResetTripB 1 "Yes" 0 "No" ;
VAL_ 697 IcHuResetTripA 1 "Yes" 0 "No" ;
VAL_ 946 DoorStateRearLHStatus 3 "Signal not available" 2 "Reserved" 1 "Reserved" 0 "Value is plausible" ;
VAL_ 946 DoorStatePassStatus 3 "Signal not avialable" 2 "Reserved" 1 "Reserved" 0 "Value is plausible" ;
VAL_ 946 DoorStatePass 1 "Open" 0 "Close" ;
VAL_ 946 DoorStateDrvrStatus 3 "Signal not available" 2 "Reserved" 1 "Reserved " 0 "Signal is correct" ;
VAL_ 946 DoorStateDrvr 1 "open" 0 "Close" ;
VAL_ 946 DoorStateRearRH 1 "Open" 0 "Close" ;
VAL_ 946 DoorStateRearRHStatus 3 "Signal not available" 2 "Reserved" 1 "Reserved" 0 "Value is plausible" ;
VAL_ 946 DoorStateRearLH 1 "open" 0 "close" ;
VAL_ 946 TailgateState 1 "Open" 0 "Close" ;
VAL_ 946 TailgateStateStatus 3 "Signal not available" 2 "Reserved" 1 "Reserved" 0 "Value is plausible" ;
VAL_ 946 LowBeamMalFn 1 "Low Beam Malfunction" 0 "Low Beam Normal" ;
VAL_ 946 HighBeamTelltale 1 "High Beam ON" 0 "High Beam OFF" ;
VAL_ 946 HighBeamTelltaleStatus 3 "Signal not available" 2 "Reserved" 1 "Reserved" 0 "Value is plausible" ;
VAL_ 946 DRLTelltale 1 "DRL ON" 0 "DRL OFF" ;
VAL_ 946 DRLTelltaleStatus 3 "Signal not available" 2 "Reserved" 1 "Reserved" 0 "Value is plausible" ;
VAL_ 946 LowBeamMalFnStatus 3 "Signal not available" 2 "Reserved" 1 "Reserved" 0 "Value is plausible" ;
VAL_ 946 BonnetState 1 "Open" 0 "Close" ;
VAL_ 946 BonnetStateStatus 3 "Signal Not Available" 2 "Reserved for future" 1 "Reserved for future" 0 "Value is plausible" ;
VAL_ 948 OdoICFullSigPeriodicStatus 3 "Signal Not Available" 2 "Information given by IC is implausible" 1 "Reserved for future use" 0 "Information given by IC is correct" ;
VAL_ 1274 GlobalRealTimeGS 16777215 "Signal not available" ;
VAL_ 1274 OdoICFullSigGS 16777215 "Signal not available" ;
VAL_ 1274 BatVoltGS 255 "Signal nlot available" ;
VAL_ 1274 VehicleInteriorTempGS 255 "Signal not available" ;
VAL_ 1276 EngSpdGS 65535 "Signal not available" ;
VAL_ 1276 AccPedPosnGS 255 "Signal not available" ;
VAL_ 1276 ClntTempGS 255 "Signal not available" ;
VAL_ 1276 VehSpdGS 255 "Signal not available" ;
VAL_ 1276 OATICSigGS 255 "Signal not available" ;
VAL_ 1276 PowerModeStateGS 15 "Signal not available" 14 "Reserved" 13 "Reserved" 12 "Reserved" 11 "Tranpoer Drive Run" 10 "Transport Drive Crank" 9 "Start(Crank)" 8 "Run(Engine Run)" 7 "Transport Drive" 6 "Active(Ignition ON)" 5 "Accessory Delay" 4 "Accessory" 3 "KeyIn" 2 "Transport Park" 1 "Awake" 0 "Pre Stand By" ;
VAL_ 1276 ParkBrkStateGS 1 "Park Brake is ON" 0 "Park Brake is Off" ;
VAL_ 1280 RepeatMessageReq_BCM 1 "Repeat message state requested" 0 "Repeat message state not requested" ;
VAL_ 1280 ActiveWakeUp_BCM 1 "Node has  woken up the network(Active wakeup)" 0 "Node has not woken up the network(Passive wakeup)" ;
VAL_ 1280 CurrentState_BCM 1 "Normal Operation State" 0 "Repeat Messgae State" ;
VAL_ 1280 PreviousState_BCM 7 "Reserved" 6 "Reserved" 5 "Reserved" 4 " Bus Sleep State" 3 "Prepare Bus Sleep State" 2 "Ready Sleep State" 1 "Normal Operation State" 0 "Repeat Message State" ;
VAL_ 516 ActGear_Updated 0 "Not Updated" 1 "Updated" ;
VAL_ 519 MotPedalPosThrottleValve_Updated 0 "Not Updated" 1 "Updated" ;
VAL_ 519 MotRpm_Updated 0 "Not Updated" 1 "Updated" ;
VAL_ 529 CrbMaxRegenTorque_Updated 0 "Not Updated" 1 "Updated" ;
VAL_ 529 CrbActualRegenTorque_Updated 0 "Not Updated" 1 "Updated" ;
VAL_ 769 AxsOut_Qualifier 0 "NotInitialized" 1 "Normal" 2 "Faulty" 3 "ReducedMonitored" 4 "ReducedAccuracy" ;
VAL_ 769 Standstill_Qualifier 0 "NotInitialized" 1 "Normal" 2 "Faulty" ;
VAL_ 770 BlsOutDncQualifier 0 "Not_Initialized" 1 "Normal" 2 "Faulty" ;
VAL_ 770 ESPLamp 3 "Reserved for future" 2 "Lamp_Blink" 1 "Lamp_On" 0 "Lamp_Off" ;
VAL_ 770 ABSLamp 3 "Reserved for future" 2 "Lamp_Blink" 1 "Lamp_On" 0 "Lamp_Off" ;
VAL_ 770 EBDLamp 3 "Reserved for future" 2 "Lamp_Blink" 1 "Lamp_On" 0 "Lamp_Off" ;
VAL_ 772 VehicleSpeed_Qualifier 0 "NotInitialized" 1 "Normal" 2 "Faulty" 3 "DifferentCalculated" 4 "ReducedMonitored" 5 "NotCalculated" 6 "InvalidUndervoltage" ;
VAL_ 775 ApbSystemState 0 "NotInitialized" 1 "BrakeReleased" 2 "BrakeApplied" 3 "BrakeApplying" 4 "BrakeReleasing" ;
VAL_ 277 SteerAngEPAsDir 1 "Counter Clockwise Direct" 0 "Clockwise Direction" ;
VAL_ 277 SteerAngEPASStatus 3 "Reserved" 2 "Signal is implausible" 1 "Reserved " 0 "Signal is correct" ;
VAL_ 342 IMU_ERR_MEM_Status 1 "On" 0 "Off" ;
VAL_ 342 IMU_AX_failure 1 "On" 0 "Off" ;
VAL_ 342 IMU_AY_failure 1 "On" 0 "Off" ;
VAL_ 342 IMU_PSIP1_failure 1 "On" 0 "Off" ;
VAL_ 342 IMU_Busoff_detected 1 "On" 0 "Off" ;
VAL_ 342 IMU_Synchronisation_underflow 1 "On" 0 "Off" ;
VAL_ 342 IMU_Synchronisation_overflow 1 "On" 0 "Off" ;
VAL_ 342 IMU_Sensor_internal_failure 1 "On" 0 "Off" ;
VAL_ 342 IMU_Synchronisation_failure 1 "On" 0 "Off" ;
VAL_ 342 IMU_RQ_MSG_CRC_failure 1 "On" 0 "Off" ;
VAL_ 342 IMU_CLU_Type 15 "Unknown" 14 "Unknown" 13 "Unknown" 12 "Unknown" 11 "Unknown" 10 "Unknown" 9 "Unknown" 8 "Unknown" 7 "Unknown" 6 "Unknown" 5 "Unknown" 4 "Unknown" 3 "Unknown" 2 "DRS-MM5.8" 1 "DRS-MM5.7" 0 "Unknown" ;
VAL_ 337 IMU_LonAccStatus 15 "Reserved" 14 "Reserved" 13 "Reserved" 12 "Reserved" 11 "Reserved" 10 "Reserved" 9 "Reserved" 8 "Reserved" 7 "Initialization running" 6 "Initialization running" 5 "Initialization running" 4 "Initialization running" 3 "Reserved" 2 "Signal failure" 1 "Sensor not available" 0 "Signal in specification" ;
VAL_ 8 RB_Endianess 1 "Motorola Format" 0 "Intel Format" ;
VAL_ 8 RB_UNLOCK_ERR_MEM 1 "On" 0 "Off" ;
VAL_ 8 RB_RESET 1 "On" 0 "Off" ;
VAL_ 8 RB_KEEP_QUIET 1 "On" 0 "Off" ;
VAL_ 336 IMU_CLU_Status 3 "Sync underflow" 2 "Sync overflow" 1 "Invalid" 0 "No sync failure" ;
VAL_ 336 IMU_YawRtStatus 15 "Reserved" 14 "Reserved" 13 "Reserved" 12 "Reserved" 11 "Reserved" 10 "Reserved" 9 "Reserved" 8 "Reserved" 7 "Initialization running" 6 "Initialization running" 5 "Initialization running" 4 "Initialization running" 3 "Reserved" 2 "Signal failure" 1 "Sensor not available" 0 "Signal in specification" ;
VAL_ 336 IMU_LatAccStatus 15 "Reserved" 14 "Reserved" 13 "Reserved" 12 "Reserved" 11 "Reserved" 10 "Reserved" 9 "Reserved" 8 "Reserved" 7 "Initialization running" 6 "Initialization running" 5 "Initialization running" 4 "Initialization running" 3 "Reserved" 2 "Signal failure" 1 "Sensor not available" 0 "Signal in specification" ;
VAL_ 2147485697 Indicator_01 15 "Dim White" 14 "Dim Violet" 13 "Dim Blue" 12 "Dim Cyan" 11 "Dim Green" 10 "Dim Yellow" 9 "Dim Red" 8 "White" 7 "Violet" 6 "Blue" 5 "Cyan" 4 "Green" 3 "Yellow" 2 "Orange" 1 "Red" 0 "Black" ;
VAL_ 2147485697 Indicator_02 15 "Dim White" 14 "Dim Violet" 13 "Dim Blue" 12 "Dim Cyan" 11 "Dim Green" 10 "Dim Yellow" 9 "Dim Red" 8 "White" 7 "Violet" 6 "Blue" 5 "Cyan" 4 "Green" 3 "Yellow" 2 "Orange" 1 "Red" 0 "Black" ;
VAL_ 2147485697 Indicator_03 15 "Dim White" 14 "Dim Violet" 13 "Dim Blue" 12 "Dim Cyan" 11 "Dim Green" 10 "Dim Yellow" 9 "Dim Red" 8 "White" 7 "Violet" 6 "Blue" 5 "Cyan" 4 "Green" 3 "Yellow" 2 "Orange" 1 "Red" 0 "Black" ;
VAL_ 2147485697 Indicator_04 15 "Dim White" 14 "Dim Violet" 13 "Dim Blue" 12 "Dim Cyan" 11 "Dim Green" 10 "Dim Yellow" 9 "Dim Red" 8 "White" 7 "Violet" 6 "Blue" 5 "Cyan" 4 "Green" 3 "Yellow" 2 "Orange" 1 "Red" 0 "Black" ;
VAL_ 2147485697 Indicator_05 15 "Dim White" 14 "Dim Violet" 13 "Dim Blue" 12 "Dim Cyan" 11 "Dim Green" 10 "Dim Yellow" 9 "Dim Red" 8 "White" 7 "Violet" 6 "Blue" 5 "Cyan" 4 "Green" 3 "Yellow" 2 "Orange" 1 "Red" 0 "Black" ;
VAL_ 2147485697 Indicator_06 15 "Dim White" 14 "Dim Violet" 13 "Dim Blue" 12 "Dim Cyan" 11 "Dim Green" 10 "Dim Yellow" 9 "Dim Red" 8 "White" 7 "Violet" 6 "Blue" 5 "Cyan" 4 "Green" 3 "Yellow" 2 "Orange" 1 "Red" 0 "Black" ;
VAL_ 2147485697 Indicator_07 15 "Dim White" 14 "Dim Violet" 13 "Dim Blue" 12 "Dim Cyan" 11 "Dim Green" 10 "Dim Yellow" 9 "Dim Red" 8 "White" 7 "Violet" 6 "Blue" 5 "Cyan" 4 "Green" 3 "Yellow" 2 "Orange" 1 "Red" 0 "Black" ;
VAL_ 2147485697 Indicator_08 15 "Dim White" 14 "Dim Violet" 13 "Dim Blue" 12 "Dim Cyan" 11 "Dim Green" 10 "Dim Yellow" 9 "Dim Red" 8 "White" 7 "Violet" 6 "Blue" 5 "Cyan" 4 "Green" 3 "Yellow" 2 "Orange" 1 "Red" 0 "Black" ;
VAL_ 2147485697 Indicator_09 15 "Dim White" 14 "Dim Violet" 13 "Dim Blue" 12 "Dim Cyan" 11 "Dim Green" 10 "Dim Yellow" 9 "Dim Red" 8 "White" 7 "Violet" 6 "Blue" 5 "Cyan" 4 "Green" 3 "Yellow" 2 "Orange" 1 "Red" 0 "Black" ;
VAL_ 2147485697 Indicator_10 15 "Dim White" 14 "Dim Violet" 13 "Dim Blue" 12 "Dim Cyan" 11 "Dim Green" 10 "Dim Yellow" 9 "Dim Red" 8 "White" 7 "Violet" 6 "Blue" 5 "Cyan" 4 "Green" 3 "Yellow" 2 "Orange" 1 "Red" 0 "Black" ;
VAL_ 2147485697 Indicator_11 15 "Dim White" 14 "Dim Violet" 13 "Dim Blue" 12 "Dim Cyan" 11 "Dim Green" 10 "Dim Yellow" 9 "Dim Red" 8 "White" 7 "Violet" 6 "Blue" 5 "Cyan" 4 "Green" 3 "Yellow" 2 "Orange" 1 "Red" 0 "Black" ;
VAL_ 2147485697 Indicator_12 15 "Dim White" 14 "Dim Violet" 13 "Dim Blue" 12 "Dim Cyan" 11 "Dim Green" 10 "Dim Yellow" 9 "Dim Red" 8 "White" 7 "Violet" 6 "Blue" 5 "Cyan" 4 "Green" 3 "Yellow" 2 "Orange" 1 "Red" 0 "Black" ;
